AUTOSAR XML (schema 4-2-2)
package /MICROSAR/NvM_swc/DataTypes
  impl type NvM_RequestResultType: compu {0=NVM_REQ_OK, 1=NVM_REQ_NOT_OK, 2=NVM_REQ_PENDING, 3=NVM_REQ_INTEGRITY_FAILED, 4=NVM_REQ_BLOCK_SKIPPED, 5=NVM_REQ_NV_INVALIDATED, 6=NVM_REQ_CANCELED, 7=NVM_REQ_REDUNDANCY_FAILED, 8=NVM_REQ_RESTORED_FROM_ROM}, implementation-data-type=uint8
  impl type NvM_BlockIdType: range raw 1..32767, implementation-data-type=uint16
package /MICROSAR/NvM_swc/Interfaces
  client server interface NvMAdministration: is-service=true, service-kind=NON-VOLATILE-RAM-MANAGER
    operation SetBlockProtection: possible-error=NvMAdministration/E_NOT_OK
      arg ProtectionEnabled: type=boolean, direction=IN
    error E_NOT_OK: error-code=1
  client server interface NvMService_AC3_SRBS: is-service=true, service-kind=NON-VOLATILE-RAM-MANAGER
    6 x operation, all with possible-error=NvMService_AC3_SRBS/E_NOT_OK:
      GetErrorStatus
        arg ErrorStatus: type=NvM_RequestResultType, direction=OUT
      SetRamBlockStatus
        arg RamBlockStatus: type=boolean, direction=IN
      ReadBlock
        arg DstPtr: type=dtRef_VOID, direction=IN
      WriteBlock
        arg SrcPtr: type=dtRef_const_VOID, direction=IN
      InvalidateNvBlock
      EraseBlock
    error E_NOT_OK: error-code=1
  client server interface NvMService_AC3_SRBS_Defs: is-service=true, service-kind=NON-VOLATILE-RAM-MANAGER
    7 x operation, all with possible-error=NvMService_AC3_SRBS_Defs/E_NOT_OK:
      GetErrorStatus
        arg ErrorStatus: type=NvM_RequestResultType, direction=OUT
      SetRamBlockStatus
        arg RamBlockStatus: type=boolean, direction=IN
      ReadBlock
        arg DstPtr: type=dtRef_VOID, direction=IN
      WriteBlock
        arg SrcPtr: type=dtRef_const_VOID, direction=IN
      RestoreBlockDefaults
        arg DstPtr: type=dtRef_VOID, direction=IN
      InvalidateNvBlock
      EraseBlock
    error E_NOT_OK: error-code=1
package /MICROSAR/NvM_swc/ComponentTypes
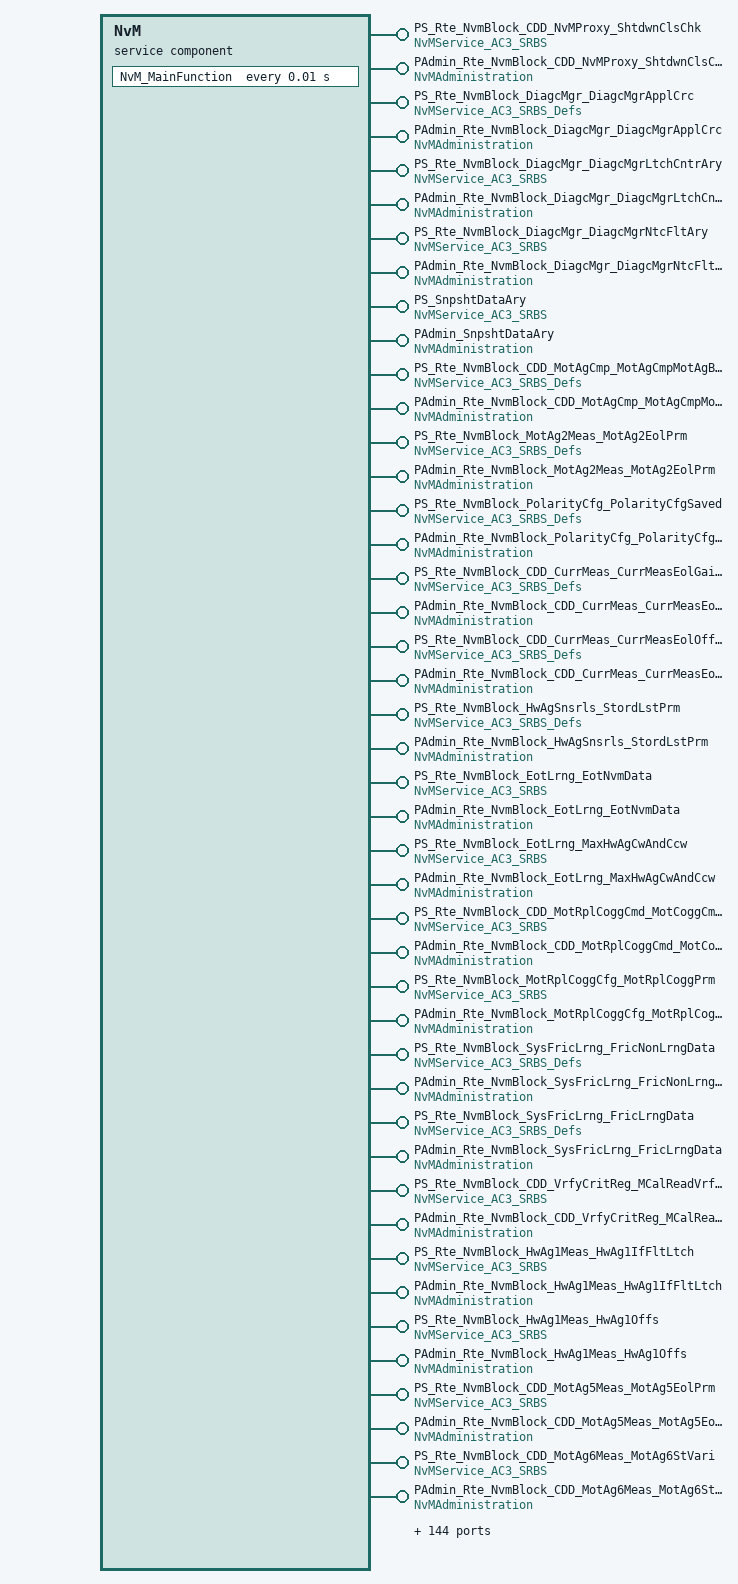
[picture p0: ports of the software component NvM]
  service sw component type NvM: category=SERVICE_COMPONENT
    188 x provide port:
      PS_Rte_NvmBlock_CDD_NvMProxy_ShtdwnClsChk: provided-interface=NvMService_AC3_SRBS
      PAdmin_Rte_NvmBlock_CDD_NvMProxy_ShtdwnClsChk: provided-interface=NvMAdministration
      PS_Rte_NvmBlock_DiagcMgr_DiagcMgrApplCrc: provided-interface=NvMService_AC3_SRBS_Defs
      PAdmin_Rte_NvmBlock_DiagcMgr_DiagcMgrApplCrc: provided-interface=NvMAdministration
      PS_Rte_NvmBlock_DiagcMgr_DiagcMgrLtchCntrAry: provided-interface=NvMService_AC3_SRBS
      PAdmin_Rte_NvmBlock_DiagcMgr_DiagcMgrLtchCntrAry: provided-interface=NvMAdministration
      PS_Rte_NvmBlock_DiagcMgr_DiagcMgrNtcFltAry: provided-interface=NvMService_AC3_SRBS
      PAdmin_Rte_NvmBlock_DiagcMgr_DiagcMgrNtcFltAry: provided-interface=NvMAdministration
      PS_SnpshtDataAry: provided-interface=NvMService_AC3_SRBS
      PAdmin_SnpshtDataAry: provided-interface=NvMAdministration
      PS_Rte_NvmBlock_CDD_MotAgCmp_MotAgCmpMotAgBackEmf: provided-interface=NvMService_AC3_SRBS_Defs
      PAdmin_Rte_NvmBlock_CDD_MotAgCmp_MotAgCmpMotAgBackEmf: provided-interface=NvMAdministration
      PS_Rte_NvmBlock_MotAg2Meas_MotAg2EolPrm: provided-interface=NvMService_AC3_SRBS_Defs
      PAdmin_Rte_NvmBlock_MotAg2Meas_MotAg2EolPrm: provided-interface=NvMAdministration
      PS_Rte_NvmBlock_PolarityCfg_PolarityCfgSaved: provided-interface=NvMService_AC3_SRBS_Defs
      PAdmin_Rte_NvmBlock_PolarityCfg_PolarityCfgSaved: provided-interface=NvMAdministration
      PS_Rte_NvmBlock_CDD_CurrMeas_CurrMeasEolGainCalSetABC: provided-interface=NvMService_AC3_SRBS_Defs
      PAdmin_Rte_NvmBlock_CDD_CurrMeas_CurrMeasEolGainCalSetABC: provided-interface=NvMAdministration
      PS_Rte_NvmBlock_CDD_CurrMeas_CurrMeasEolOffsCalSetABC: provided-interface=NvMService_AC3_SRBS_Defs
      PAdmin_Rte_NvmBlock_CDD_CurrMeas_CurrMeasEolOffsCalSetABC: provided-interface=NvMAdministration
      PS_Rte_NvmBlock_HwAgSnsrls_StordLstPrm: provided-interface=NvMService_AC3_SRBS_Defs
      PAdmin_Rte_NvmBlock_HwAgSnsrls_StordLstPrm: provided-interface=NvMAdministration
      PS_Rte_NvmBlock_EotLrng_EotNvmData: provided-interface=NvMService_AC3_SRBS
      PAdmin_Rte_NvmBlock_EotLrng_EotNvmData: provided-interface=NvMAdministration
      PS_Rte_NvmBlock_EotLrng_MaxHwAgCwAndCcw: provided-interface=NvMService_AC3_SRBS
      PAdmin_Rte_NvmBlock_EotLrng_MaxHwAgCwAndCcw: provided-interface=NvMAdministration
      PS_Rte_NvmBlock_CDD_MotRplCoggCmd_MotCoggCmdY: provided-interface=NvMService_AC3_SRBS
      PAdmin_Rte_NvmBlock_CDD_MotRplCoggCmd_MotCoggCmdY: provided-interface=NvMAdministration
      PS_Rte_NvmBlock_MotRplCoggCfg_MotRplCoggPrm: provided-interface=NvMService_AC3_SRBS
      PAdmin_Rte_NvmBlock_MotRplCoggCfg_MotRplCoggPrm: provided-interface=NvMAdministration
      PS_Rte_NvmBlock_SysFricLrng_FricNonLrngData: provided-interface=NvMService_AC3_SRBS_Defs
      PAdmin_Rte_NvmBlock_SysFricLrng_FricNonLrngData: provided-interface=NvMAdministration
      PS_Rte_NvmBlock_SysFricLrng_FricLrngData: provided-interface=NvMService_AC3_SRBS_Defs
      PAdmin_Rte_NvmBlock_SysFricLrng_FricLrngData: provided-interface=NvMAdministration
      PS_Rte_NvmBlock_CDD_VrfyCritReg_MCalReadVrfyCritRegFltNvmInfo: provided-interface=NvMService_AC3_SRBS
      PAdmin_Rte_NvmBlock_CDD_VrfyCritReg_MCalReadVrfyCritRegFltNvmInfo: provided-interface=NvMAdministration
      PS_Rte_NvmBlock_HwAg1Meas_HwAg1IfFltLtch: provided-interface=NvMService_AC3_SRBS
      PAdmin_Rte_NvmBlock_HwAg1Meas_HwAg1IfFltLtch: provided-interface=NvMAdministration
      PS_Rte_NvmBlock_HwAg1Meas_HwAg1Offs: provided-interface=NvMService_AC3_SRBS
      PAdmin_Rte_NvmBlock_HwAg1Meas_HwAg1Offs: provided-interface=NvMAdministration
      PS_Rte_NvmBlock_CDD_MotAg5Meas_MotAg5EolPrm: provided-interface=NvMService_AC3_SRBS
      PAdmin_Rte_NvmBlock_CDD_MotAg5Meas_MotAg5EolPrm: provided-interface=NvMAdministration
      PS_Rte_NvmBlock_CDD_MotAg6Meas_MotAg6StVari: provided-interface=NvMService_AC3_SRBS
      PAdmin_Rte_NvmBlock_CDD_MotAg6Meas_MotAg6StVari: provided-interface=NvMAdministration
      PS_Rte_NvmBlock_CDD_MotAg6Meas_MotAg6EolPrm: provided-interface=NvMService_AC3_SRBS
      PAdmin_Rte_NvmBlock_CDD_MotAg6Meas_MotAg6EolPrm: provided-interface=NvMAdministration
      PS_Rte_NvmBlock_CDD_MotAg5Meas_MotAg5StVari: provided-interface=NvMService_AC3_SRBS
      PAdmin_Rte_NvmBlock_CDD_MotAg5Meas_MotAg5StVari: provided-interface=NvMAdministration
      PS_Rte_NvmBlock_MotCtrlPrmEstimn_MotPrmNom: provided-interface=NvMService_AC3_SRBS
      PAdmin_Rte_NvmBlock_MotCtrlPrmEstimn_MotPrmNom: provided-interface=NvMAdministration
      PS_Deprecated_Rte_NvmBlock_HwTqCorrln_HwTqChACmnModCmpLpFilSt: provided-interface=NvMService_AC3_SRBS
      PAdmin_Deprecated_Rte_NvmBlock_HwTqCorrln_HwTqChACmnModCmpLpFilSt: provided-interface=NvMAdministration
      PS_Rte_NvmBlock_MotTqCmdSca_MotTqScaFac: provided-interface=NvMService_AC3_SRBS
      PAdmin_Rte_NvmBlock_MotTqCmdSca_MotTqScaFac: provided-interface=NvMAdministration
      PS_Rte_NvmBlock_DutyCycThermProtn_FilStVal: provided-interface=NvMService_AC3_SRBS
      PAdmin_Rte_NvmBlock_DutyCycThermProtn_FilStVal: provided-interface=NvMAdministration
      PS_Rte_NvmBlock_CmnMfgSrv_MfgTmpBuf1: provided-interface=NvMService_AC3_SRBS
      PAdmin_Rte_NvmBlock_CmnMfgSrv_MfgTmpBuf1: provided-interface=NvMAdministration
      PS_Rte_NvmBlock_CmnMfgSrv_DiRestore: provided-interface=NvMService_AC3_SRBS
      PAdmin_Rte_NvmBlock_CmnMfgSrv_DiRestore: provided-interface=NvMAdministration
      PS_Rte_NvmBlock_CmnMfgSrv_NxtrMfgEnaCntr: provided-interface=NvMService_AC3_SRBS_Defs
      PAdmin_Rte_NvmBlock_CmnMfgSrv_NxtrMfgEnaCntr: provided-interface=NvMAdministration
      PS_Rte_NvmBlock_CmnMfgSrv_MfgTmpBuf0: provided-interface=NvMService_AC3_SRBS
      PAdmin_Rte_NvmBlock_CmnMfgSrv_MfgTmpBuf0: provided-interface=NvMAdministration
      PS_Rte_NvmBlock_CmnMfgSrv_MfgTmpBuf3: provided-interface=NvMService_AC3_SRBS
      PAdmin_Rte_NvmBlock_CmnMfgSrv_MfgTmpBuf3: provided-interface=NvMAdministration
      PS_Rte_NvmBlock_CmnMfgSrv_EpsSysSerlNr: provided-interface=NvMService_AC3_SRBS
      PAdmin_Rte_NvmBlock_CmnMfgSrv_EpsSysSerlNr: provided-interface=NvMAdministration
      PS_Rte_NvmBlock_CmnMfgSrv_MfgTmpBuf2: provided-interface=NvMService_AC3_SRBS
      PAdmin_Rte_NvmBlock_CmnMfgSrv_MfgTmpBuf2: provided-interface=NvMAdministration
      PS_Rte_NvmBlock_CmnMfgSrv_CcaHwPartNr: provided-interface=NvMService_AC3_SRBS
      PAdmin_Rte_NvmBlock_CmnMfgSrv_CcaHwPartNr: provided-interface=NvMAdministration
      PS_Rte_NvmBlock_CmnMfgSrv_MfgTmpBuf4: provided-interface=NvMService_AC3_SRBS
      PAdmin_Rte_NvmBlock_CmnMfgSrv_MfgTmpBuf4: provided-interface=NvMAdministration
      PS_Rte_NvmBlock_CmnMfgSrv_SeedKey: provided-interface=NvMService_AC3_SRBS_Defs
      PAdmin_Rte_NvmBlock_CmnMfgSrv_SeedKey: provided-interface=NvMAdministration
      PS_Rte_NvmBlock_CmnMfgSrv_IgnCntr: provided-interface=NvMService_AC3_SRBS_Defs
      PAdmin_Rte_NvmBlock_CmnMfgSrv_IgnCntr: provided-interface=NvMAdministration
      PS_Rte_NvmBlock_CmnMfgSrv_CcaSerlNr: provided-interface=NvMService_AC3_SRBS
      PAdmin_Rte_NvmBlock_CmnMfgSrv_CcaSerlNr: provided-interface=NvMAdministration
      PS_Rte_NvmBlock_CDD_HwTq1Meas_HwTq1Offs: provided-interface=NvMService_AC3_SRBS_Defs
      PAdmin_Rte_NvmBlock_CDD_HwTq1Meas_HwTq1Offs: provided-interface=NvMAdministration
      PS_Rte_NvmBlock_CDD_HwTq8Meas_HwTq8Offs: provided-interface=NvMService_AC3_SRBS_Defs
      PAdmin_Rte_NvmBlock_CDD_HwTq8Meas_HwTq8Offs: provided-interface=NvMAdministration
      PS_Rte_NvmBlock_TEstimn_TFilStVal: provided-interface=NvMService_AC3_SRBS
      PAdmin_Rte_NvmBlock_TEstimn_TFilStVal: provided-interface=NvMAdministration
      PS_Rte_NvmBlock_HwTq9Meas_HwTq9Offs: provided-interface=NvMService_AC3_SRBS
      PAdmin_Rte_NvmBlock_HwTq9Meas_HwTq9Offs: provided-interface=NvMAdministration
      PS_Rte_NvmBlock_HwTq10Meas_HwTq10Offs: provided-interface=NvMService_AC3_SRBS
      PAdmin_Rte_NvmBlock_HwTq10Meas_HwTq10Offs: provided-interface=NvMAdministration
      PS_Rte_NvmBlock_CustDiag_DidDE04: provided-interface=NvMService_AC3_SRBS_Defs
      PAdmin_Rte_NvmBlock_CustDiag_DidDE04: provided-interface=NvMAdministration
      PS_Rte_NvmBlock_CustDiag_Did3003: provided-interface=NvMService_AC3_SRBS_Defs
      PAdmin_Rte_NvmBlock_CustDiag_Did3003: provided-interface=NvMAdministration
      PS_Rte_NvmBlock_CustDiag_DidEE01: provided-interface=NvMService_AC3_SRBS_Defs
      PAdmin_Rte_NvmBlock_CustDiag_DidEE01: provided-interface=NvMAdministration
      PS_Rte_NvmBlock_CustDiag_DidF111: provided-interface=NvMService_AC3_SRBS_Defs
      PAdmin_Rte_NvmBlock_CustDiag_DidF111: provided-interface=NvMAdministration
      PS_Rte_NvmBlock_CustDiag_DidF113: provided-interface=NvMService_AC3_SRBS_Defs
      PAdmin_Rte_NvmBlock_CustDiag_DidF113: provided-interface=NvMAdministration
      PS_Rte_NvmBlock_CustDiag_DidEE02: provided-interface=NvMService_AC3_SRBS_Defs
      PAdmin_Rte_NvmBlock_CustDiag_DidEE02: provided-interface=NvMAdministration
      PS_Rte_NvmBlock_CustDiag_DidDE02: provided-interface=NvMService_AC3_SRBS_Defs
      PAdmin_Rte_NvmBlock_CustDiag_DidDE02: provided-interface=NvMAdministration
      PS_Rte_NvmBlock_CustDiag_DidDE03: provided-interface=NvMService_AC3_SRBS_Defs
      PAdmin_Rte_NvmBlock_CustDiag_DidDE03: provided-interface=NvMAdministration
      PS_Rte_NvmBlock_CustDiag_DidDE00: provided-interface=NvMService_AC3_SRBS_Defs
      PAdmin_Rte_NvmBlock_CustDiag_DidDE00: provided-interface=NvMAdministration
      PS_Rte_NvmBlock_CustDiag_DidDE01: provided-interface=NvMService_AC3_SRBS_Defs
      PAdmin_Rte_NvmBlock_CustDiag_DidDE01: provided-interface=NvMAdministration
      PS_Rte_NvmBlock_FordVehSpdArbn_FordVehTireCircum: provided-interface=NvMService_AC3_SRBS
      PAdmin_Rte_NvmBlock_FordVehSpdArbn_FordVehTireCircum: provided-interface=NvMAdministration
      PS_Rte_NvmBlock_FordHwAgArbn_PrevIgnCycVal: provided-interface=NvMService_AC3_SRBS_Defs
      PAdmin_Rte_NvmBlock_FordHwAgArbn_PrevIgnCycVal: provided-interface=NvMAdministration
      PS_Rte_NvmBlock_FordHwAgArbn_NonAbsOffsVldFlg: provided-interface=NvMService_AC3_SRBS
      PAdmin_Rte_NvmBlock_FordHwAgArbn_NonAbsOffsVldFlg: provided-interface=NvMAdministration
      PS_Rte_NvmBlock_FordHwAgArbn_NonAbsOffs: provided-interface=NvMService_AC3_SRBS
      PAdmin_Rte_NvmBlock_FordHwAgArbn_NonAbsOffs: provided-interface=NvMAdministration
      PS_Rte_NvmBlock_CustDiag_DidF15F: provided-interface=NvMService_AC3_SRBS_Defs
      PAdmin_Rte_NvmBlock_CustDiag_DidF15F: provided-interface=NvMAdministration
      PS_Rte_NvmBlock_CustDiag_DidEE88: provided-interface=NvMService_AC3_SRBS_Defs
      PAdmin_Rte_NvmBlock_CustDiag_DidEE88: provided-interface=NvMAdministration
      PS_Rte_NvmBlock_CustDiag_DidF110: provided-interface=NvMService_AC3_SRBS_Defs
      PAdmin_Rte_NvmBlock_CustDiag_DidF110: provided-interface=NvMAdministration
      PS_Rte_NvmBlock_CustDiag_DidEED0: provided-interface=NvMService_AC3_SRBS_Defs
      PAdmin_Rte_NvmBlock_CustDiag_DidEED0: provided-interface=NvMAdministration
      PS_Rte_NvmBlock_CustDiag_DidEE83: provided-interface=NvMService_AC3_SRBS_Defs
      PAdmin_Rte_NvmBlock_CustDiag_DidEE83: provided-interface=NvMAdministration
      PS_Rte_NvmBlock_CustDiag_Did301A: provided-interface=NvMService_AC3_SRBS_Defs
      PAdmin_Rte_NvmBlock_CustDiag_Did301A: provided-interface=NvMAdministration
      PS_Rte_NvmBlock_CustDiag_DidF162: provided-interface=NvMService_AC3_SRBS_Defs
      PAdmin_Rte_NvmBlock_CustDiag_DidF162: provided-interface=NvMAdministration
      PS_Rte_NvmBlock_CustDiag_DidEE40: provided-interface=NvMService_AC3_SRBS_Defs
      PAdmin_Rte_NvmBlock_CustDiag_DidEE40: provided-interface=NvMAdministration
      PS_Rte_NvmBlock_CustDiag_DidEE81: provided-interface=NvMService_AC3_SRBS_Defs
      PAdmin_Rte_NvmBlock_CustDiag_DidEE81: provided-interface=NvMAdministration
      PS_Rte_NvmBlock_CustDiag_DidEE82: provided-interface=NvMService_AC3_SRBS_Defs
      PAdmin_Rte_NvmBlock_CustDiag_DidEE82: provided-interface=NvMAdministration
      PS_Rte_NvmBlock_CustDiag_DidEE41: provided-interface=NvMService_AC3_SRBS_Defs
      PAdmin_Rte_NvmBlock_CustDiag_DidEE41: provided-interface=NvMAdministration
      PS_Rte_NvmBlock_CustDiag_DidEE84: provided-interface=NvMService_AC3_SRBS_Defs
      PAdmin_Rte_NvmBlock_CustDiag_DidEE84: provided-interface=NvMAdministration
      PS_Rte_NvmBlock_CustDiag_DidF18A: provided-interface=NvMService_AC3_SRBS_Defs
      PAdmin_Rte_NvmBlock_CustDiag_DidF18A: provided-interface=NvMAdministration
      PS_Rte_NvmBlock_CustDiag_DidEE00: provided-interface=NvMService_AC3_SRBS_Defs
      PAdmin_Rte_NvmBlock_CustDiag_DidEE00: provided-interface=NvMAdministration
      PS_Rte_NvmBlock_CustDiag_DidF166: provided-interface=NvMService_AC3_SRBS_Defs
      PAdmin_Rte_NvmBlock_CustDiag_DidF166: provided-interface=NvMAdministration
      PS_Rte_NvmBlock_CustDiag_Did205A: provided-interface=NvMService_AC3_SRBS_Defs
      PAdmin_Rte_NvmBlock_CustDiag_Did205A: provided-interface=NvMAdministration
      PS_Rte_NvmBlock_CustDiag_DidEE87: provided-interface=NvMService_AC3_SRBS_Defs
      PAdmin_Rte_NvmBlock_CustDiag_DidEE87: provided-interface=NvMAdministration
      PS_Rte_NvmBlock_CustDiag_DidDE05: provided-interface=NvMService_AC3_SRBS_Defs
      PAdmin_Rte_NvmBlock_CustDiag_DidDE05: provided-interface=NvMAdministration
      PS_Rte_NvmBlock_CustDiag_DidEE86: provided-interface=NvMService_AC3_SRBS_Defs
      PAdmin_Rte_NvmBlock_CustDiag_DidEE86: provided-interface=NvMAdministration
      PS_Rte_NvmBlock_CustDiag_DidF163: provided-interface=NvMService_AC3_SRBS_Defs
      PAdmin_Rte_NvmBlock_CustDiag_DidF163: provided-interface=NvMAdministration
      PS_Rte_NvmBlock_CustDiag_DidF18C: provided-interface=NvMService_AC3_SRBS_Defs
      PAdmin_Rte_NvmBlock_CustDiag_DidF18C: provided-interface=NvMAdministration
      PS_Rte_NvmBlock_CustDiag_Did205B: provided-interface=NvMService_AC3_SRBS_Defs
      PAdmin_Rte_NvmBlock_CustDiag_Did205B: provided-interface=NvMAdministration
      PS_Rte_NvmBlock_CustDiag_DidEE85: provided-interface=NvMService_AC3_SRBS_Defs
      PAdmin_Rte_NvmBlock_CustDiag_DidEE85: provided-interface=NvMAdministration
      PS_Rte_NvmBlock_CustDiag_DidEE21: provided-interface=NvMService_AC3_SRBS_Defs
      PAdmin_Rte_NvmBlock_CustDiag_DidEE21: provided-interface=NvMAdministration
      PS_Rte_NvmBlock_CustDiag_DidEE22: provided-interface=NvMService_AC3_SRBS_Defs
      PAdmin_Rte_NvmBlock_CustDiag_DidEE22: provided-interface=NvMAdministration
      PS_Rte_NvmBlock_CustDiag_DidF190: provided-interface=NvMService_AC3_SRBS_Defs
      PAdmin_Rte_NvmBlock_CustDiag_DidF190: provided-interface=NvMAdministration
      PS_Rte_NvmBlock_CustDiag_Did630F: provided-interface=NvMService_AC3_SRBS_Defs
      PAdmin_Rte_NvmBlock_CustDiag_Did630F: provided-interface=NvMAdministration
      PS_Rte_NvmBlock_CustDiag_Did630FChk: provided-interface=NvMService_AC3_SRBS_Defs
      PAdmin_Rte_NvmBlock_CustDiag_Did630FChk: provided-interface=NvMAdministration
      PS_Rte_NvmBlock_CustDiag_DidEE23: provided-interface=NvMService_AC3_SRBS_Defs
      PAdmin_Rte_NvmBlock_CustDiag_DidEE23: provided-interface=NvMAdministration
      PS_Rte_NvmBlock_StackMeas_StackMeasRes: provided-interface=NvMService_AC3_SRBS_Defs
      PAdmin_Rte_NvmBlock_StackMeas_StackMeasRes: provided-interface=NvMAdministration
      PS_Rte_NvmBlock_StackMeas_StackMeasApplCrc: provided-interface=NvMService_AC3_SRBS
      PAdmin_Rte_NvmBlock_StackMeas_StackMeasApplCrc: provided-interface=NvMAdministration
      PS_Rte_NvmBlock_CDD_FordBlaBoxIfCmp1_LaneAssi: provided-interface=NvMService_AC3_SRBS_Defs
      PAdmin_Rte_NvmBlock_CDD_FordBlaBoxIfCmp1_LaneAssi: provided-interface=NvMAdministration
      PS_Rte_NvmBlock_CDD_FordBlaBoxIfCmp1_PullDriftCmp: provided-interface=NvMService_AC3_SRBS_Defs
      PAdmin_Rte_NvmBlock_CDD_FordBlaBoxIfCmp1_PullDriftCmp: provided-interface=NvMAdministration
      PS_Rte_NvmBlock_CDD_FordBlaBoxIfCmp1_TrlrBackupAssi: provided-interface=NvMService_AC3_SRBS_Defs
      PAdmin_Rte_NvmBlock_CDD_FordBlaBoxIfCmp1_TrlrBackupAssi: provided-interface=NvMAdministration
      PS_Rte_NvmBlock_CDD_FordBlaBoxIfCmp1_ActvNiblCtrl: provided-interface=NvMService_AC3_SRBS_Defs
      PAdmin_Rte_NvmBlock_CDD_FordBlaBoxIfCmp1_ActvNiblCtrl: provided-interface=NvMAdministration
    behavior NvMInternalBehavior: handle-termination-and-restart=NO-SUPPORT
      timing event Timer_NvM_MainFunction: start-on-event=NvM_MainFunction, period=0.01
      717 x operation invoked event:
        OpEventGetErrorStatus_GetErrorStatus_PS_Rte_NvmBlock_CDD_NvMProxy_ShtdwnClsChk: start-on-event=GetErrorStatus, operation=PS_Rte_NvmBlock_CDD_NvMProxy_ShtdwnClsChk.GetErrorStatus
        OpEventGetErrorStatus_GetErrorStatus_PS_Rte_NvmBlock_DiagcMgr_DiagcMgrApplCrc: start-on-event=GetErrorStatus, operation=PS_Rte_NvmBlock_DiagcMgr_DiagcMgrApplCrc.GetErrorStatus
        OpEventGetErrorStatus_GetErrorStatus_PS_Rte_NvmBlock_DiagcMgr_DiagcMgrLtchCntrAry: start-on-event=GetErrorStatus, operation=PS_Rte_NvmBlock_DiagcMgr_DiagcMgrLtchCntrAry.GetErrorStatus
        OpEventGetErrorStatus_GetErrorStatus_PS_Rte_NvmBlock_DiagcMgr_DiagcMgrNtcFltAry: start-on-event=GetErrorStatus, operation=PS_Rte_NvmBlock_DiagcMgr_DiagcMgrNtcFltAry.GetErrorStatus
        OpEventGetErrorStatus_GetErrorStatus_PS_SnpshtDataAry: start-on-event=GetErrorStatus, operation=PS_SnpshtDataAry.GetErrorStatus
        OpEventGetErrorStatus_GetErrorStatus_PS_Rte_NvmBlock_CDD_MotAgCmp_MotAgCmpMotAgBackEmf: start-on-event=GetErrorStatus, operation=PS_Rte_NvmBlock_CDD_MotAgCmp_MotAgCmpMotAgBackEmf.GetErrorStatus
        OpEventGetErrorStatus_GetErrorStatus_PS_Rte_NvmBlock_MotAg2Meas_MotAg2EolPrm: start-on-event=GetErrorStatus, operation=PS_Rte_NvmBlock_MotAg2Meas_MotAg2EolPrm.GetErrorStatus
        OpEventGetErrorStatus_GetErrorStatus_PS_Rte_NvmBlock_PolarityCfg_PolarityCfgSaved: start-on-event=GetErrorStatus, operation=PS_Rte_NvmBlock_PolarityCfg_PolarityCfgSaved.GetErrorStatus
        OpEventGetErrorStatus_GetErrorStatus_PS_Rte_NvmBlock_CDD_CurrMeas_CurrMeasEolGainCalSetABC: start-on-event=GetErrorStatus, operation=PS_Rte_NvmBlock_CDD_CurrMeas_CurrMeasEolGainCalSetABC.GetErrorStatus
        OpEventGetErrorStatus_GetErrorStatus_PS_Rte_NvmBlock_CDD_CurrMeas_CurrMeasEolOffsCalSetABC: start-on-event=GetErrorStatus, operation=PS_Rte_NvmBlock_CDD_CurrMeas_CurrMeasEolOffsCalSetABC.GetErrorStatus
        OpEventGetErrorStatus_GetErrorStatus_PS_Rte_NvmBlock_HwAgSnsrls_StordLstPrm: start-on-event=GetErrorStatus, operation=PS_Rte_NvmBlock_HwAgSnsrls_StordLstPrm.GetErrorStatus
        OpEventGetErrorStatus_GetErrorStatus_PS_Rte_NvmBlock_EotLrng_EotNvmData: start-on-event=GetErrorStatus, operation=PS_Rte_NvmBlock_EotLrng_EotNvmData.GetErrorStatus
        OpEventGetErrorStatus_GetErrorStatus_PS_Rte_NvmBlock_EotLrng_MaxHwAgCwAndCcw: start-on-event=GetErrorStatus, operation=PS_Rte_NvmBlock_EotLrng_MaxHwAgCwAndCcw.GetErrorStatus
        OpEventGetErrorStatus_GetErrorStatus_PS_Rte_NvmBlock_CDD_MotRplCoggCmd_MotCoggCmdY: start-on-event=GetErrorStatus, operation=PS_Rte_NvmBlock_CDD_MotRplCoggCmd_MotCoggCmdY.GetErrorStatus
        OpEventGetErrorStatus_GetErrorStatus_PS_Rte_NvmBlock_MotRplCoggCfg_MotRplCoggPrm: start-on-event=GetErrorStatus, operation=PS_Rte_NvmBlock_MotRplCoggCfg_MotRplCoggPrm.GetErrorStatus
        OpEventGetErrorStatus_GetErrorStatus_PS_Rte_NvmBlock_SysFricLrng_FricNonLrngData: start-on-event=GetErrorStatus, operation=PS_Rte_NvmBlock_SysFricLrng_FricNonLrngData.GetErrorStatus
        OpEventGetErrorStatus_GetErrorStatus_PS_Rte_NvmBlock_SysFricLrng_FricLrngData: start-on-event=GetErrorStatus, operation=PS_Rte_NvmBlock_SysFricLrng_FricLrngData.GetErrorStatus
        OpEventGetErrorStatus_GetErrorStatus_PS_Rte_NvmBlock_CDD_VrfyCritReg_MCalReadVrfyCritRegFltNvmInfo: start-on-event=GetErrorStatus, operation=PS_Rte_NvmBlock_CDD_VrfyCritReg_MCalReadVrfyCritRegFltNvmInfo.GetErrorStatus
        OpEventGetErrorStatus_GetErrorStatus_PS_Rte_NvmBlock_HwAg1Meas_HwAg1IfFltLtch: start-on-event=GetErrorStatus, operation=PS_Rte_NvmBlock_HwAg1Meas_HwAg1IfFltLtch.GetErrorStatus
        OpEventGetErrorStatus_GetErrorStatus_PS_Rte_NvmBlock_HwAg1Meas_HwAg1Offs: start-on-event=GetErrorStatus, operation=PS_Rte_NvmBlock_HwAg1Meas_HwAg1Offs.GetErrorStatus
        OpEventGetErrorStatus_GetErrorStatus_PS_Rte_NvmBlock_CDD_MotAg5Meas_MotAg5EolPrm: start-on-event=GetErrorStatus, operation=PS_Rte_NvmBlock_CDD_MotAg5Meas_MotAg5EolPrm.GetErrorStatus
        OpEventGetErrorStatus_GetErrorStatus_PS_Rte_NvmBlock_CDD_MotAg6Meas_MotAg6StVari: start-on-event=GetErrorStatus, operation=PS_Rte_NvmBlock_CDD_MotAg6Meas_MotAg6StVari.GetErrorStatus
        OpEventGetErrorStatus_GetErrorStatus_PS_Rte_NvmBlock_CDD_MotAg6Meas_MotAg6EolPrm: start-on-event=GetErrorStatus, operation=PS_Rte_NvmBlock_CDD_MotAg6Meas_MotAg6EolPrm.GetErrorStatus
        OpEventGetErrorStatus_GetErrorStatus_PS_Rte_NvmBlock_CDD_MotAg5Meas_MotAg5StVari: start-on-event=GetErrorStatus, operation=PS_Rte_NvmBlock_CDD_MotAg5Meas_MotAg5StVari.GetErrorStatus
        OpEventGetErrorStatus_GetErrorStatus_PS_Rte_NvmBlock_MotCtrlPrmEstimn_MotPrmNom: start-on-event=GetErrorStatus, operation=PS_Rte_NvmBlock_MotCtrlPrmEstimn_MotPrmNom.GetErrorStatus
        OpEventGetErrorStatus_GetErrorStatus_PS_Deprecated_Rte_NvmBlock_HwTqCorrln_HwTqChACmnModCmpLpFilSt: start-on-event=GetErrorStatus, operation=PS_Deprecated_Rte_NvmBlock_HwTqCorrln_HwTqChACmnModCmpLpFilSt.GetErrorStatus
        OpEventGetErrorStatus_GetErrorStatus_PS_Rte_NvmBlock_MotTqCmdSca_MotTqScaFac: start-on-event=GetErrorStatus, operation=PS_Rte_NvmBlock_MotTqCmdSca_MotTqScaFac.GetErrorStatus
        OpEventGetErrorStatus_GetErrorStatus_PS_Rte_NvmBlock_DutyCycThermProtn_FilStVal: start-on-event=GetErrorStatus, operation=PS_Rte_NvmBlock_DutyCycThermProtn_FilStVal.GetErrorStatus
        OpEventGetErrorStatus_GetErrorStatus_PS_Rte_NvmBlock_CmnMfgSrv_MfgTmpBuf1: start-on-event=GetErrorStatus, operation=PS_Rte_NvmBlock_CmnMfgSrv_MfgTmpBuf1.GetErrorStatus
        OpEventGetErrorStatus_GetErrorStatus_PS_Rte_NvmBlock_CmnMfgSrv_DiRestore: start-on-event=GetErrorStatus, operation=PS_Rte_NvmBlock_CmnMfgSrv_DiRestore.GetErrorStatus
        OpEventGetErrorStatus_GetErrorStatus_PS_Rte_NvmBlock_CmnMfgSrv_NxtrMfgEnaCntr: start-on-event=GetErrorStatus, operation=PS_Rte_NvmBlock_CmnMfgSrv_NxtrMfgEnaCntr.GetErrorStatus
        OpEventGetErrorStatus_GetErrorStatus_PS_Rte_NvmBlock_CmnMfgSrv_MfgTmpBuf0: start-on-event=GetErrorStatus, operation=PS_Rte_NvmBlock_CmnMfgSrv_MfgTmpBuf0.GetErrorStatus
        OpEventGetErrorStatus_GetErrorStatus_PS_Rte_NvmBlock_CmnMfgSrv_MfgTmpBuf3: start-on-event=GetErrorStatus, operation=PS_Rte_NvmBlock_CmnMfgSrv_MfgTmpBuf3.GetErrorStatus
        OpEventGetErrorStatus_GetErrorStatus_PS_Rte_NvmBlock_CmnMfgSrv_EpsSysSerlNr: start-on-event=GetErrorStatus, operation=PS_Rte_NvmBlock_CmnMfgSrv_EpsSysSerlNr.GetErrorStatus
        OpEventGetErrorStatus_GetErrorStatus_PS_Rte_NvmBlock_CmnMfgSrv_MfgTmpBuf2: start-on-event=GetErrorStatus, operation=PS_Rte_NvmBlock_CmnMfgSrv_MfgTmpBuf2.GetErrorStatus
        OpEventGetErrorStatus_GetErrorStatus_PS_Rte_NvmBlock_CmnMfgSrv_CcaHwPartNr: start-on-event=GetErrorStatus, operation=PS_Rte_NvmBlock_CmnMfgSrv_CcaHwPartNr.GetErrorStatus
        OpEventGetErrorStatus_GetErrorStatus_PS_Rte_NvmBlock_CmnMfgSrv_MfgTmpBuf4: start-on-event=GetErrorStatus, operation=PS_Rte_NvmBlock_CmnMfgSrv_MfgTmpBuf4.GetErrorStatus
        OpEventGetErrorStatus_GetErrorStatus_PS_Rte_NvmBlock_CmnMfgSrv_SeedKey: start-on-event=GetErrorStatus, operation=PS_Rte_NvmBlock_CmnMfgSrv_SeedKey.GetErrorStatus
        OpEventGetErrorStatus_GetErrorStatus_PS_Rte_NvmBlock_CmnMfgSrv_IgnCntr: start-on-event=GetErrorStatus, operation=PS_Rte_NvmBlock_CmnMfgSrv_IgnCntr.GetErrorStatus
        OpEventGetErrorStatus_GetErrorStatus_PS_Rte_NvmBlock_CmnMfgSrv_CcaSerlNr: start-on-event=GetErrorStatus, operation=PS_Rte_NvmBlock_CmnMfgSrv_CcaSerlNr.GetErrorStatus
        OpEventGetErrorStatus_GetErrorStatus_PS_Rte_NvmBlock_CDD_HwTq1Meas_HwTq1Offs: start-on-event=GetErrorStatus, operation=PS_Rte_NvmBlock_CDD_HwTq1Meas_HwTq1Offs.GetErrorStatus
        OpEventGetErrorStatus_GetErrorStatus_PS_Rte_NvmBlock_CDD_HwTq8Meas_HwTq8Offs: start-on-event=GetErrorStatus, operation=PS_Rte_NvmBlock_CDD_HwTq8Meas_HwTq8Offs.GetErrorStatus
        OpEventGetErrorStatus_GetErrorStatus_PS_Rte_NvmBlock_TEstimn_TFilStVal: start-on-event=GetErrorStatus, operation=PS_Rte_NvmBlock_TEstimn_TFilStVal.GetErrorStatus
        OpEventGetErrorStatus_GetErrorStatus_PS_Rte_NvmBlock_HwTq9Meas_HwTq9Offs: start-on-event=GetErrorStatus, operation=PS_Rte_NvmBlock_HwTq9Meas_HwTq9Offs.GetErrorStatus
        OpEventGetErrorStatus_GetErrorStatus_PS_Rte_NvmBlock_HwTq10Meas_HwTq10Offs: start-on-event=GetErrorStatus, operation=PS_Rte_NvmBlock_HwTq10Meas_HwTq10Offs.GetErrorStatus
        OpEventSetRamBlockStatus_SetRamBlockStatus_PS_Rte_NvmBlock_CDD_NvMProxy_ShtdwnClsChk: start-on-event=SetRamBlockStatus, operation=PS_Rte_NvmBlock_CDD_NvMProxy_ShtdwnClsChk.SetRamBlockStatus
        OpEventSetRamBlockStatus_SetRamBlockStatus_PS_Rte_NvmBlock_DiagcMgr_DiagcMgrApplCrc: start-on-event=SetRamBlockStatus, operation=PS_Rte_NvmBlock_DiagcMgr_DiagcMgrApplCrc.SetRamBlockStatus
        OpEventSetRamBlockStatus_SetRamBlockStatus_PS_Rte_NvmBlock_DiagcMgr_DiagcMgrLtchCntrAry: start-on-event=SetRamBlockStatus, operation=PS_Rte_NvmBlock_DiagcMgr_DiagcMgrLtchCntrAry.SetRamBlockStatus
        OpEventSetRamBlockStatus_SetRamBlockStatus_PS_Rte_NvmBlock_DiagcMgr_DiagcMgrNtcFltAry: start-on-event=SetRamBlockStatus, operation=PS_Rte_NvmBlock_DiagcMgr_DiagcMgrNtcFltAry.SetRamBlockStatus
        OpEventSetRamBlockStatus_SetRamBlockStatus_PS_SnpshtDataAry: start-on-event=SetRamBlockStatus, operation=PS_SnpshtDataAry.SetRamBlockStatus
        OpEventSetRamBlockStatus_SetRamBlockStatus_PS_Rte_NvmBlock_CDD_MotAgCmp_MotAgCmpMotAgBackEmf: start-on-event=SetRamBlockStatus, operation=PS_Rte_NvmBlock_CDD_MotAgCmp_MotAgCmpMotAgBackEmf.SetRamBlockStatus
        OpEventSetRamBlockStatus_SetRamBlockStatus_PS_Rte_NvmBlock_MotAg2Meas_MotAg2EolPrm: start-on-event=SetRamBlockStatus, operation=PS_Rte_NvmBlock_MotAg2Meas_MotAg2EolPrm.SetRamBlockStatus
        OpEventSetRamBlockStatus_SetRamBlockStatus_PS_Rte_NvmBlock_PolarityCfg_PolarityCfgSaved: start-on-event=SetRamBlockStatus, operation=PS_Rte_NvmBlock_PolarityCfg_PolarityCfgSaved.SetRamBlockStatus
        OpEventSetRamBlockStatus_SetRamBlockStatus_PS_Rte_NvmBlock_CDD_CurrMeas_CurrMeasEolGainCalSetABC: start-on-event=SetRamBlockStatus, operation=PS_Rte_NvmBlock_CDD_CurrMeas_CurrMeasEolGainCalSetABC.SetRamBlockStatus
        OpEventSetRamBlockStatus_SetRamBlockStatus_PS_Rte_NvmBlock_CDD_CurrMeas_CurrMeasEolOffsCalSetABC: start-on-event=SetRamBlockStatus, operation=PS_Rte_NvmBlock_CDD_CurrMeas_CurrMeasEolOffsCalSetABC.SetRamBlockStatus
        OpEventSetRamBlockStatus_SetRamBlockStatus_PS_Rte_NvmBlock_HwAgSnsrls_StordLstPrm: start-on-event=SetRamBlockStatus, operation=PS_Rte_NvmBlock_HwAgSnsrls_StordLstPrm.SetRamBlockStatus
        OpEventSetRamBlockStatus_SetRamBlockStatus_PS_Rte_NvmBlock_EotLrng_EotNvmData: start-on-event=SetRamBlockStatus, operation=PS_Rte_NvmBlock_EotLrng_EotNvmData.SetRamBlockStatus
        OpEventSetRamBlockStatus_SetRamBlockStatus_PS_Rte_NvmBlock_EotLrng_MaxHwAgCwAndCcw: start-on-event=SetRamBlockStatus, operation=PS_Rte_NvmBlock_EotLrng_MaxHwAgCwAndCcw.SetRamBlockStatus
        OpEventSetRamBlockStatus_SetRamBlockStatus_PS_Rte_NvmBlock_CDD_MotRplCoggCmd_MotCoggCmdY: start-on-event=SetRamBlockStatus, operation=PS_Rte_NvmBlock_CDD_MotRplCoggCmd_MotCoggCmdY.SetRamBlockStatus
        OpEventSetRamBlockStatus_SetRamBlockStatus_PS_Rte_NvmBlock_MotRplCoggCfg_MotRplCoggPrm: start-on-event=SetRamBlockStatus, operation=PS_Rte_NvmBlock_MotRplCoggCfg_MotRplCoggPrm.SetRamBlockStatus
        OpEventSetRamBlockStatus_SetRamBlockStatus_PS_Rte_NvmBlock_SysFricLrng_FricNonLrngData: start-on-event=SetRamBlockStatus, operation=PS_Rte_NvmBlock_SysFricLrng_FricNonLrngData.SetRamBlockStatus
        OpEventSetRamBlockStatus_SetRamBlockStatus_PS_Rte_NvmBlock_SysFricLrng_FricLrngData: start-on-event=SetRamBlockStatus, operation=PS_Rte_NvmBlock_SysFricLrng_FricLrngData.SetRamBlockStatus
        OpEventSetRamBlockStatus_SetRamBlockStatus_PS_Rte_NvmBlock_CDD_VrfyCritReg_MCalReadVrfyCritRegFltNvmInfo: start-on-event=SetRamBlockStatus, operation=PS_Rte_NvmBlock_CDD_VrfyCritReg_MCalReadVrfyCritRegFltNvmInfo.SetRamBlockStatus
        OpEventSetRamBlockStatus_SetRamBlockStatus_PS_Rte_NvmBlock_HwAg1Meas_HwAg1IfFltLtch: start-on-event=SetRamBlockStatus, operation=PS_Rte_NvmBlock_HwAg1Meas_HwAg1IfFltLtch.SetRamBlockStatus
        OpEventSetRamBlockStatus_SetRamBlockStatus_PS_Rte_NvmBlock_HwAg1Meas_HwAg1Offs: start-on-event=SetRamBlockStatus, operation=PS_Rte_NvmBlock_HwAg1Meas_HwAg1Offs.SetRamBlockStatus
        OpEventSetRamBlockStatus_SetRamBlockStatus_PS_Rte_NvmBlock_CDD_MotAg5Meas_MotAg5EolPrm: start-on-event=SetRamBlockStatus, operation=PS_Rte_NvmBlock_CDD_MotAg5Meas_MotAg5EolPrm.SetRamBlockStatus
        OpEventSetRamBlockStatus_SetRamBlockStatus_PS_Rte_NvmBlock_CDD_MotAg6Meas_MotAg6StVari: start-on-event=SetRamBlockStatus, operation=PS_Rte_NvmBlock_CDD_MotAg6Meas_MotAg6StVari.SetRamBlockStatus
        OpEventSetRamBlockStatus_SetRamBlockStatus_PS_Rte_NvmBlock_CDD_MotAg6Meas_MotAg6EolPrm: start-on-event=SetRamBlockStatus, operation=PS_Rte_NvmBlock_CDD_MotAg6Meas_MotAg6EolPrm.SetRamBlockStatus
        OpEventSetRamBlockStatus_SetRamBlockStatus_PS_Rte_NvmBlock_CDD_MotAg5Meas_MotAg5StVari: start-on-event=SetRamBlockStatus, operation=PS_Rte_NvmBlock_CDD_MotAg5Meas_MotAg5StVari.SetRamBlockStatus
        OpEventSetRamBlockStatus_SetRamBlockStatus_PS_Rte_NvmBlock_MotCtrlPrmEstimn_MotPrmNom: start-on-event=SetRamBlockStatus, operation=PS_Rte_NvmBlock_MotCtrlPrmEstimn_MotPrmNom.SetRamBlockStatus
        OpEventSetRamBlockStatus_SetRamBlockStatus_PS_Deprecated_Rte_NvmBlock_HwTqCorrln_HwTqChACmnModCmpLpFilSt: start-on-event=SetRamBlockStatus, operation=PS_Deprecated_Rte_NvmBlock_HwTqCorrln_HwTqChACmnModCmpLpFilSt.SetRamBlockStatus
        OpEventSetRamBlockStatus_SetRamBlockStatus_PS_Rte_NvmBlock_MotTqCmdSca_MotTqScaFac: start-on-event=SetRamBlockStatus, operation=PS_Rte_NvmBlock_MotTqCmdSca_MotTqScaFac.SetRamBlockStatus
        OpEventSetRamBlockStatus_SetRamBlockStatus_PS_Rte_NvmBlock_DutyCycThermProtn_FilStVal: start-on-event=SetRamBlockStatus, operation=PS_Rte_NvmBlock_DutyCycThermProtn_FilStVal.SetRamBlockStatus
        OpEventSetRamBlockStatus_SetRamBlockStatus_PS_Rte_NvmBlock_CmnMfgSrv_MfgTmpBuf1: start-on-event=SetRamBlockStatus, operation=PS_Rte_NvmBlock_CmnMfgSrv_MfgTmpBuf1.SetRamBlockStatus
        OpEventSetRamBlockStatus_SetRamBlockStatus_PS_Rte_NvmBlock_CmnMfgSrv_DiRestore: start-on-event=SetRamBlockStatus, operation=PS_Rte_NvmBlock_CmnMfgSrv_DiRestore.SetRamBlockStatus
        OpEventSetRamBlockStatus_SetRamBlockStatus_PS_Rte_NvmBlock_CmnMfgSrv_NxtrMfgEnaCntr: start-on-event=SetRamBlockStatus, operation=PS_Rte_NvmBlock_CmnMfgSrv_NxtrMfgEnaCntr.SetRamBlockStatus
        OpEventSetRamBlockStatus_SetRamBlockStatus_PS_Rte_NvmBlock_CmnMfgSrv_MfgTmpBuf0: start-on-event=SetRamBlockStatus, operation=PS_Rte_NvmBlock_CmnMfgSrv_MfgTmpBuf0.SetRamBlockStatus
        OpEventSetRamBlockStatus_SetRamBlockStatus_PS_Rte_NvmBlock_CmnMfgSrv_MfgTmpBuf3: start-on-event=SetRamBlockStatus, operation=PS_Rte_NvmBlock_CmnMfgSrv_MfgTmpBuf3.SetRamBlockStatus
        OpEventSetRamBlockStatus_SetRamBlockStatus_PS_Rte_NvmBlock_CmnMfgSrv_EpsSysSerlNr: start-on-event=SetRamBlockStatus, operation=PS_Rte_NvmBlock_CmnMfgSrv_EpsSysSerlNr.SetRamBlockStatus
        OpEventSetRamBlockStatus_SetRamBlockStatus_PS_Rte_NvmBlock_CmnMfgSrv_MfgTmpBuf2: start-on-event=SetRamBlockStatus, operation=PS_Rte_NvmBlock_CmnMfgSrv_MfgTmpBuf2.SetRamBlockStatus
        OpEventSetRamBlockStatus_SetRamBlockStatus_PS_Rte_NvmBlock_CmnMfgSrv_CcaHwPartNr: start-on-event=SetRamBlockStatus, operation=PS_Rte_NvmBlock_CmnMfgSrv_CcaHwPartNr.SetRamBlockStatus
        OpEventSetRamBlockStatus_SetRamBlockStatus_PS_Rte_NvmBlock_CmnMfgSrv_MfgTmpBuf4: start-on-event=SetRamBlockStatus, operation=PS_Rte_NvmBlock_CmnMfgSrv_MfgTmpBuf4.SetRamBlockStatus
        OpEventSetRamBlockStatus_SetRamBlockStatus_PS_Rte_NvmBlock_CmnMfgSrv_SeedKey: start-on-event=SetRamBlockStatus, operation=PS_Rte_NvmBlock_CmnMfgSrv_SeedKey.SetRamBlockStatus
        OpEventSetRamBlockStatus_SetRamBlockStatus_PS_Rte_NvmBlock_CmnMfgSrv_IgnCntr: start-on-event=SetRamBlockStatus, operation=PS_Rte_NvmBlock_CmnMfgSrv_IgnCntr.SetRamBlockStatus
        OpEventSetRamBlockStatus_SetRamBlockStatus_PS_Rte_NvmBlock_CmnMfgSrv_CcaSerlNr: start-on-event=SetRamBlockStatus, operation=PS_Rte_NvmBlock_CmnMfgSrv_CcaSerlNr.SetRamBlockStatus
        OpEventSetRamBlockStatus_SetRamBlockStatus_PS_Rte_NvmBlock_CDD_HwTq1Meas_HwTq1Offs: start-on-event=SetRamBlockStatus, operation=PS_Rte_NvmBlock_CDD_HwTq1Meas_HwTq1Offs.SetRamBlockStatus
        OpEventSetRamBlockStatus_SetRamBlockStatus_PS_Rte_NvmBlock_CDD_HwTq8Meas_HwTq8Offs: start-on-event=SetRamBlockStatus, operation=PS_Rte_NvmBlock_CDD_HwTq8Meas_HwTq8Offs.SetRamBlockStatus
        OpEventSetRamBlockStatus_SetRamBlockStatus_PS_Rte_NvmBlock_TEstimn_TFilStVal: start-on-event=SetRamBlockStatus, operation=PS_Rte_NvmBlock_TEstimn_TFilStVal.SetRamBlockStatus
        OpEventSetRamBlockStatus_SetRamBlockStatus_PS_Rte_NvmBlock_HwTq9Meas_HwTq9Offs: start-on-event=SetRamBlockStatus, operation=PS_Rte_NvmBlock_HwTq9Meas_HwTq9Offs.SetRamBlockStatus
        OpEventSetRamBlockStatus_SetRamBlockStatus_PS_Rte_NvmBlock_HwTq10Meas_HwTq10Offs: start-on-event=SetRamBlockStatus, operation=PS_Rte_NvmBlock_HwTq10Meas_HwTq10Offs.SetRamBlockStatus
        OpEventReadBlock_ReadBlock_PS_Rte_NvmBlock_CDD_NvMProxy_ShtdwnClsChk: start-on-event=ReadBlock, operation=PS_Rte_NvmBlock_CDD_NvMProxy_ShtdwnClsChk.ReadBlock
        OpEventReadBlock_ReadBlock_PS_Rte_NvmBlock_DiagcMgr_DiagcMgrApplCrc: start-on-event=ReadBlock, operation=PS_Rte_NvmBlock_DiagcMgr_DiagcMgrApplCrc.ReadBlock
        OpEventReadBlock_ReadBlock_PS_Rte_NvmBlock_DiagcMgr_DiagcMgrLtchCntrAry: start-on-event=ReadBlock, operation=PS_Rte_NvmBlock_DiagcMgr_DiagcMgrLtchCntrAry.ReadBlock
        OpEventReadBlock_ReadBlock_PS_Rte_NvmBlock_DiagcMgr_DiagcMgrNtcFltAry: start-on-event=ReadBlock, operation=PS_Rte_NvmBlock_DiagcMgr_DiagcMgrNtcFltAry.ReadBlock
        OpEventReadBlock_ReadBlock_PS_SnpshtDataAry: start-on-event=ReadBlock, operation=PS_SnpshtDataAry.ReadBlock
        OpEventReadBlock_ReadBlock_PS_Rte_NvmBlock_CDD_MotAgCmp_MotAgCmpMotAgBackEmf: start-on-event=ReadBlock, operation=PS_Rte_NvmBlock_CDD_MotAgCmp_MotAgCmpMotAgBackEmf.ReadBlock
        OpEventReadBlock_ReadBlock_PS_Rte_NvmBlock_MotAg2Meas_MotAg2EolPrm: start-on-event=ReadBlock, operation=PS_Rte_NvmBlock_MotAg2Meas_MotAg2EolPrm.ReadBlock
        OpEventReadBlock_ReadBlock_PS_Rte_NvmBlock_PolarityCfg_PolarityCfgSaved: start-on-event=ReadBlock, operation=PS_Rte_NvmBlock_PolarityCfg_PolarityCfgSaved.ReadBlock
        OpEventReadBlock_ReadBlock_PS_Rte_NvmBlock_CDD_CurrMeas_CurrMeasEolGainCalSetABC: start-on-event=ReadBlock, operation=PS_Rte_NvmBlock_CDD_CurrMeas_CurrMeasEolGainCalSetABC.ReadBlock
        OpEventReadBlock_ReadBlock_PS_Rte_NvmBlock_CDD_CurrMeas_CurrMeasEolOffsCalSetABC: start-on-event=ReadBlock, operation=PS_Rte_NvmBlock_CDD_CurrMeas_CurrMeasEolOffsCalSetABC.ReadBlock
        OpEventReadBlock_ReadBlock_PS_Rte_NvmBlock_HwAgSnsrls_StordLstPrm: start-on-event=ReadBlock, operation=PS_Rte_NvmBlock_HwAgSnsrls_StordLstPrm.ReadBlock
        OpEventReadBlock_ReadBlock_PS_Rte_NvmBlock_EotLrng_EotNvmData: start-on-event=ReadBlock, operation=PS_Rte_NvmBlock_EotLrng_EotNvmData.ReadBlock
        OpEventReadBlock_ReadBlock_PS_Rte_NvmBlock_EotLrng_MaxHwAgCwAndCcw: start-on-event=ReadBlock, operation=PS_Rte_NvmBlock_EotLrng_MaxHwAgCwAndCcw.ReadBlock
        OpEventReadBlock_ReadBlock_PS_Rte_NvmBlock_CDD_MotRplCoggCmd_MotCoggCmdY: start-on-event=ReadBlock, operation=PS_Rte_NvmBlock_CDD_MotRplCoggCmd_MotCoggCmdY.ReadBlock
        OpEventReadBlock_ReadBlock_PS_Rte_NvmBlock_MotRplCoggCfg_MotRplCoggPrm: start-on-event=ReadBlock, operation=PS_Rte_NvmBlock_MotRplCoggCfg_MotRplCoggPrm.ReadBlock
        OpEventReadBlock_ReadBlock_PS_Rte_NvmBlock_SysFricLrng_FricNonLrngData: start-on-event=ReadBlock, operation=PS_Rte_NvmBlock_SysFricLrng_FricNonLrngData.ReadBlock
        OpEventReadBlock_ReadBlock_PS_Rte_NvmBlock_SysFricLrng_FricLrngData: start-on-event=ReadBlock, operation=PS_Rte_NvmBlock_SysFricLrng_FricLrngData.ReadBlock
        OpEventReadBlock_ReadBlock_PS_Rte_NvmBlock_CDD_VrfyCritReg_MCalReadVrfyCritRegFltNvmInfo: start-on-event=ReadBlock, operation=PS_Rte_NvmBlock_CDD_VrfyCritReg_MCalReadVrfyCritRegFltNvmInfo.ReadBlock
        OpEventReadBlock_ReadBlock_PS_Rte_NvmBlock_HwAg1Meas_HwAg1IfFltLtch: start-on-event=ReadBlock, operation=PS_Rte_NvmBlock_HwAg1Meas_HwAg1IfFltLtch.ReadBlock
        OpEventReadBlock_ReadBlock_PS_Rte_NvmBlock_HwAg1Meas_HwAg1Offs: start-on-event=ReadBlock, operation=PS_Rte_NvmBlock_HwAg1Meas_HwAg1Offs.ReadBlock
        OpEventReadBlock_ReadBlock_PS_Rte_NvmBlock_CDD_MotAg5Meas_MotAg5EolPrm: start-on-event=ReadBlock, operation=PS_Rte_NvmBlock_CDD_MotAg5Meas_MotAg5EolPrm.ReadBlock
        OpEventReadBlock_ReadBlock_PS_Rte_NvmBlock_CDD_MotAg6Meas_MotAg6StVari: start-on-event=ReadBlock, operation=PS_Rte_NvmBlock_CDD_MotAg6Meas_MotAg6StVari.ReadBlock
        OpEventReadBlock_ReadBlock_PS_Rte_NvmBlock_CDD_MotAg6Meas_MotAg6EolPrm: start-on-event=ReadBlock, operation=PS_Rte_NvmBlock_CDD_MotAg6Meas_MotAg6EolPrm.ReadBlock
        OpEventReadBlock_ReadBlock_PS_Rte_NvmBlock_CDD_MotAg5Meas_MotAg5StVari: start-on-event=ReadBlock, operation=PS_Rte_NvmBlock_CDD_MotAg5Meas_MotAg5StVari.ReadBlock
        OpEventReadBlock_ReadBlock_PS_Rte_NvmBlock_MotCtrlPrmEstimn_MotPrmNom: start-on-event=ReadBlock, operation=PS_Rte_NvmBlock_MotCtrlPrmEstimn_MotPrmNom.ReadBlock
        OpEventReadBlock_ReadBlock_PS_Deprecated_Rte_NvmBlock_HwTqCorrln_HwTqChACmnModCmpLpFilSt: start-on-event=ReadBlock, operation=PS_Deprecated_Rte_NvmBlock_HwTqCorrln_HwTqChACmnModCmpLpFilSt.ReadBlock
        OpEventReadBlock_ReadBlock_PS_Rte_NvmBlock_MotTqCmdSca_MotTqScaFac: start-on-event=ReadBlock, operation=PS_Rte_NvmBlock_MotTqCmdSca_MotTqScaFac.ReadBlock
        OpEventReadBlock_ReadBlock_PS_Rte_NvmBlock_DutyCycThermProtn_FilStVal: start-on-event=ReadBlock, operation=PS_Rte_NvmBlock_DutyCycThermProtn_FilStVal.ReadBlock
        OpEventReadBlock_ReadBlock_PS_Rte_NvmBlock_CmnMfgSrv_MfgTmpBuf1: start-on-event=ReadBlock, operation=PS_Rte_NvmBlock_CmnMfgSrv_MfgTmpBuf1.ReadBlock
        OpEventReadBlock_ReadBlock_PS_Rte_NvmBlock_CmnMfgSrv_DiRestore: start-on-event=ReadBlock, operation=PS_Rte_NvmBlock_CmnMfgSrv_DiRestore.ReadBlock
        OpEventReadBlock_ReadBlock_PS_Rte_NvmBlock_CmnMfgSrv_NxtrMfgEnaCntr: start-on-event=ReadBlock, operation=PS_Rte_NvmBlock_CmnMfgSrv_NxtrMfgEnaCntr.ReadBlock
        OpEventReadBlock_ReadBlock_PS_Rte_NvmBlock_CmnMfgSrv_MfgTmpBuf0: start-on-event=ReadBlock, operation=PS_Rte_NvmBlock_CmnMfgSrv_MfgTmpBuf0.ReadBlock
        OpEventReadBlock_ReadBlock_PS_Rte_NvmBlock_CmnMfgSrv_MfgTmpBuf3: start-on-event=ReadBlock, operation=PS_Rte_NvmBlock_CmnMfgSrv_MfgTmpBuf3.ReadBlock
        OpEventReadBlock_ReadBlock_PS_Rte_NvmBlock_CmnMfgSrv_EpsSysSerlNr: start-on-event=ReadBlock, operation=PS_Rte_NvmBlock_CmnMfgSrv_EpsSysSerlNr.ReadBlock
        OpEventReadBlock_ReadBlock_PS_Rte_NvmBlock_CmnMfgSrv_MfgTmpBuf2: start-on-event=ReadBlock, operation=PS_Rte_NvmBlock_CmnMfgSrv_MfgTmpBuf2.ReadBlock
        OpEventReadBlock_ReadBlock_PS_Rte_NvmBlock_CmnMfgSrv_CcaHwPartNr: start-on-event=ReadBlock, operation=PS_Rte_NvmBlock_CmnMfgSrv_CcaHwPartNr.ReadBlock
        OpEventReadBlock_ReadBlock_PS_Rte_NvmBlock_CmnMfgSrv_MfgTmpBuf4: start-on-event=ReadBlock, operation=PS_Rte_NvmBlock_CmnMfgSrv_MfgTmpBuf4.ReadBlock
        OpEventReadBlock_ReadBlock_PS_Rte_NvmBlock_CmnMfgSrv_SeedKey: start-on-event=ReadBlock, operation=PS_Rte_NvmBlock_CmnMfgSrv_SeedKey.ReadBlock
        OpEventReadBlock_ReadBlock_PS_Rte_NvmBlock_CmnMfgSrv_IgnCntr: start-on-event=ReadBlock, operation=PS_Rte_NvmBlock_CmnMfgSrv_IgnCntr.ReadBlock
        OpEventReadBlock_ReadBlock_PS_Rte_NvmBlock_CmnMfgSrv_CcaSerlNr: start-on-event=ReadBlock, operation=PS_Rte_NvmBlock_CmnMfgSrv_CcaSerlNr.ReadBlock
        OpEventReadBlock_ReadBlock_PS_Rte_NvmBlock_CDD_HwTq1Meas_HwTq1Offs: start-on-event=ReadBlock, operation=PS_Rte_NvmBlock_CDD_HwTq1Meas_HwTq1Offs.ReadBlock
        OpEventReadBlock_ReadBlock_PS_Rte_NvmBlock_CDD_HwTq8Meas_HwTq8Offs: start-on-event=ReadBlock, operation=PS_Rte_NvmBlock_CDD_HwTq8Meas_HwTq8Offs.ReadBlock
        OpEventReadBlock_ReadBlock_PS_Rte_NvmBlock_TEstimn_TFilStVal: start-on-event=ReadBlock, operation=PS_Rte_NvmBlock_TEstimn_TFilStVal.ReadBlock
        OpEventReadBlock_ReadBlock_PS_Rte_NvmBlock_HwTq9Meas_HwTq9Offs: start-on-event=ReadBlock, operation=PS_Rte_NvmBlock_HwTq9Meas_HwTq9Offs.ReadBlock
        OpEventReadBlock_ReadBlock_PS_Rte_NvmBlock_HwTq10Meas_HwTq10Offs: start-on-event=ReadBlock, operation=PS_Rte_NvmBlock_HwTq10Meas_HwTq10Offs.ReadBlock
        OpEventWriteBlock_WriteBlock_PS_Rte_NvmBlock_CDD_NvMProxy_ShtdwnClsChk: start-on-event=WriteBlock, operation=PS_Rte_NvmBlock_CDD_NvMProxy_ShtdwnClsChk.WriteBlock
        OpEventWriteBlock_WriteBlock_PS_Rte_NvmBlock_DiagcMgr_DiagcMgrApplCrc: start-on-event=WriteBlock, operation=PS_Rte_NvmBlock_DiagcMgr_DiagcMgrApplCrc.WriteBlock
        OpEventWriteBlock_WriteBlock_PS_Rte_NvmBlock_DiagcMgr_DiagcMgrLtchCntrAry: start-on-event=WriteBlock, operation=PS_Rte_NvmBlock_DiagcMgr_DiagcMgrLtchCntrAry.WriteBlock
        OpEventWriteBlock_WriteBlock_PS_Rte_NvmBlock_DiagcMgr_DiagcMgrNtcFltAry: start-on-event=WriteBlock, operation=PS_Rte_NvmBlock_DiagcMgr_DiagcMgrNtcFltAry.WriteBlock
        OpEventWriteBlock_WriteBlock_PS_SnpshtDataAry: start-on-event=WriteBlock, operation=PS_SnpshtDataAry.WriteBlock
        OpEventWriteBlock_WriteBlock_PS_Rte_NvmBlock_CDD_MotAgCmp_MotAgCmpMotAgBackEmf: start-on-event=WriteBlock, operation=PS_Rte_NvmBlock_CDD_MotAgCmp_MotAgCmpMotAgBackEmf.WriteBlock
        OpEventWriteBlock_WriteBlock_PS_Rte_NvmBlock_MotAg2Meas_MotAg2EolPrm: start-on-event=WriteBlock, operation=PS_Rte_NvmBlock_MotAg2Meas_MotAg2EolPrm.WriteBlock
        OpEventWriteBlock_WriteBlock_PS_Rte_NvmBlock_PolarityCfg_PolarityCfgSaved: start-on-event=WriteBlock, operation=PS_Rte_NvmBlock_PolarityCfg_PolarityCfgSaved.WriteBlock
        OpEventWriteBlock_WriteBlock_PS_Rte_NvmBlock_CDD_CurrMeas_CurrMeasEolGainCalSetABC: start-on-event=WriteBlock, operation=PS_Rte_NvmBlock_CDD_CurrMeas_CurrMeasEolGainCalSetABC.WriteBlock
        OpEventWriteBlock_WriteBlock_PS_Rte_NvmBlock_CDD_CurrMeas_CurrMeasEolOffsCalSetABC: start-on-event=WriteBlock, operation=PS_Rte_NvmBlock_CDD_CurrMeas_CurrMeasEolOffsCalSetABC.WriteBlock
        OpEventWriteBlock_WriteBlock_PS_Rte_NvmBlock_HwAgSnsrls_StordLstPrm: start-on-event=WriteBlock, operation=PS_Rte_NvmBlock_HwAgSnsrls_StordLstPrm.WriteBlock
        OpEventWriteBlock_WriteBlock_PS_Rte_NvmBlock_EotLrng_EotNvmData: start-on-event=WriteBlock, operation=PS_Rte_NvmBlock_EotLrng_EotNvmData.WriteBlock
        OpEventWriteBlock_WriteBlock_PS_Rte_NvmBlock_EotLrng_MaxHwAgCwAndCcw: start-on-event=WriteBlock, operation=PS_Rte_NvmBlock_EotLrng_MaxHwAgCwAndCcw.WriteBlock
        OpEventWriteBlock_WriteBlock_PS_Rte_NvmBlock_CDD_MotRplCoggCmd_MotCoggCmdY: start-on-event=WriteBlock, operation=PS_Rte_NvmBlock_CDD_MotRplCoggCmd_MotCoggCmdY.WriteBlock
        OpEventWriteBlock_WriteBlock_PS_Rte_NvmBlock_MotRplCoggCfg_MotRplCoggPrm: start-on-event=WriteBlock, operation=PS_Rte_NvmBlock_MotRplCoggCfg_MotRplCoggPrm.WriteBlock
        OpEventWriteBlock_WriteBlock_PS_Rte_NvmBlock_SysFricLrng_FricNonLrngData: start-on-event=WriteBlock, operation=PS_Rte_NvmBlock_SysFricLrng_FricNonLrngData.WriteBlock
        OpEventWriteBlock_WriteBlock_PS_Rte_NvmBlock_SysFricLrng_FricLrngData: start-on-event=WriteBlock, operation=PS_Rte_NvmBlock_SysFricLrng_FricLrngData.WriteBlock
        OpEventWriteBlock_WriteBlock_PS_Rte_NvmBlock_CDD_VrfyCritReg_MCalReadVrfyCritRegFltNvmInfo: start-on-event=WriteBlock, operation=PS_Rte_NvmBlock_CDD_VrfyCritReg_MCalReadVrfyCritRegFltNvmInfo.WriteBlock
        OpEventWriteBlock_WriteBlock_PS_Rte_NvmBlock_HwAg1Meas_HwAg1IfFltLtch: start-on-event=WriteBlock, operation=PS_Rte_NvmBlock_HwAg1Meas_HwAg1IfFltLtch.WriteBlock
        OpEventWriteBlock_WriteBlock_PS_Rte_NvmBlock_HwAg1Meas_HwAg1Offs: start-on-event=WriteBlock, operation=PS_Rte_NvmBlock_HwAg1Meas_HwAg1Offs.WriteBlock
        OpEventWriteBlock_WriteBlock_PS_Rte_NvmBlock_CDD_MotAg5Meas_MotAg5EolPrm: start-on-event=WriteBlock, operation=PS_Rte_NvmBlock_CDD_MotAg5Meas_MotAg5EolPrm.WriteBlock
        OpEventWriteBlock_WriteBlock_PS_Rte_NvmBlock_CDD_MotAg6Meas_MotAg6StVari: start-on-event=WriteBlock, operation=PS_Rte_NvmBlock_CDD_MotAg6Meas_MotAg6StVari.WriteBlock
        OpEventWriteBlock_WriteBlock_PS_Rte_NvmBlock_CDD_MotAg6Meas_MotAg6EolPrm: start-on-event=WriteBlock, operation=PS_Rte_NvmBlock_CDD_MotAg6Meas_MotAg6EolPrm.WriteBlock
        OpEventWriteBlock_WriteBlock_PS_Rte_NvmBlock_CDD_MotAg5Meas_MotAg5StVari: start-on-event=WriteBlock, operation=PS_Rte_NvmBlock_CDD_MotAg5Meas_MotAg5StVari.WriteBlock
        OpEventWriteBlock_WriteBlock_PS_Rte_NvmBlock_MotCtrlPrmEstimn_MotPrmNom: start-on-event=WriteBlock, operation=PS_Rte_NvmBlock_MotCtrlPrmEstimn_MotPrmNom.WriteBlock
        OpEventWriteBlock_WriteBlock_PS_Deprecated_Rte_NvmBlock_HwTqCorrln_HwTqChACmnModCmpLpFilSt: start-on-event=WriteBlock, operation=PS_Deprecated_Rte_NvmBlock_HwTqCorrln_HwTqChACmnModCmpLpFilSt.WriteBlock
        OpEventWriteBlock_WriteBlock_PS_Rte_NvmBlock_MotTqCmdSca_MotTqScaFac: start-on-event=WriteBlock, operation=PS_Rte_NvmBlock_MotTqCmdSca_MotTqScaFac.WriteBlock
        OpEventWriteBlock_WriteBlock_PS_Rte_NvmBlock_DutyCycThermProtn_FilStVal: start-on-event=WriteBlock, operation=PS_Rte_NvmBlock_DutyCycThermProtn_FilStVal.WriteBlock
        OpEventWriteBlock_WriteBlock_PS_Rte_NvmBlock_CmnMfgSrv_MfgTmpBuf1: start-on-event=WriteBlock, operation=PS_Rte_NvmBlock_CmnMfgSrv_MfgTmpBuf1.WriteBlock
        OpEventWriteBlock_WriteBlock_PS_Rte_NvmBlock_CmnMfgSrv_DiRestore: start-on-event=WriteBlock, operation=PS_Rte_NvmBlock_CmnMfgSrv_DiRestore.WriteBlock
        OpEventWriteBlock_WriteBlock_PS_Rte_NvmBlock_CmnMfgSrv_NxtrMfgEnaCntr: start-on-event=WriteBlock, operation=PS_Rte_NvmBlock_CmnMfgSrv_NxtrMfgEnaCntr.WriteBlock
        OpEventWriteBlock_WriteBlock_PS_Rte_NvmBlock_CmnMfgSrv_MfgTmpBuf0: start-on-event=WriteBlock, operation=PS_Rte_NvmBlock_CmnMfgSrv_MfgTmpBuf0.WriteBlock
        OpEventWriteBlock_WriteBlock_PS_Rte_NvmBlock_CmnMfgSrv_MfgTmpBuf3: start-on-event=WriteBlock, operation=PS_Rte_NvmBlock_CmnMfgSrv_MfgTmpBuf3.WriteBlock
        OpEventWriteBlock_WriteBlock_PS_Rte_NvmBlock_CmnMfgSrv_EpsSysSerlNr: start-on-event=WriteBlock, operation=PS_Rte_NvmBlock_CmnMfgSrv_EpsSysSerlNr.WriteBlock
        OpEventWriteBlock_WriteBlock_PS_Rte_NvmBlock_CmnMfgSrv_MfgTmpBuf2: start-on-event=WriteBlock, operation=PS_Rte_NvmBlock_CmnMfgSrv_MfgTmpBuf2.WriteBlock
        OpEventWriteBlock_WriteBlock_PS_Rte_NvmBlock_CmnMfgSrv_CcaHwPartNr: start-on-event=WriteBlock, operation=PS_Rte_NvmBlock_CmnMfgSrv_CcaHwPartNr.WriteBlock
        OpEventWriteBlock_WriteBlock_PS_Rte_NvmBlock_CmnMfgSrv_MfgTmpBuf4: start-on-event=WriteBlock, operation=PS_Rte_NvmBlock_CmnMfgSrv_MfgTmpBuf4.WriteBlock
        OpEventWriteBlock_WriteBlock_PS_Rte_NvmBlock_CmnMfgSrv_SeedKey: start-on-event=WriteBlock, operation=PS_Rte_NvmBlock_CmnMfgSrv_SeedKey.WriteBlock
        OpEventWriteBlock_WriteBlock_PS_Rte_NvmBlock_CmnMfgSrv_IgnCntr: start-on-event=WriteBlock, operation=PS_Rte_NvmBlock_CmnMfgSrv_IgnCntr.WriteBlock
        OpEventWriteBlock_WriteBlock_PS_Rte_NvmBlock_CmnMfgSrv_CcaSerlNr: start-on-event=WriteBlock, operation=PS_Rte_NvmBlock_CmnMfgSrv_CcaSerlNr.WriteBlock
        OpEventWriteBlock_WriteBlock_PS_Rte_NvmBlock_CDD_HwTq1Meas_HwTq1Offs: start-on-event=WriteBlock, operation=PS_Rte_NvmBlock_CDD_HwTq1Meas_HwTq1Offs.WriteBlock
        OpEventWriteBlock_WriteBlock_PS_Rte_NvmBlock_CDD_HwTq8Meas_HwTq8Offs: start-on-event=WriteBlock, operation=PS_Rte_NvmBlock_CDD_HwTq8Meas_HwTq8Offs.WriteBlock
        OpEventWriteBlock_WriteBlock_PS_Rte_NvmBlock_TEstimn_TFilStVal: start-on-event=WriteBlock, operation=PS_Rte_NvmBlock_TEstimn_TFilStVal.WriteBlock
        OpEventWriteBlock_WriteBlock_PS_Rte_NvmBlock_HwTq9Meas_HwTq9Offs: start-on-event=WriteBlock, operation=PS_Rte_NvmBlock_HwTq9Meas_HwTq9Offs.WriteBlock
        OpEventWriteBlock_WriteBlock_PS_Rte_NvmBlock_HwTq10Meas_HwTq10Offs: start-on-event=WriteBlock, operation=PS_Rte_NvmBlock_HwTq10Meas_HwTq10Offs.WriteBlock
        OpEventInvalidateNvBlock_InvalidateNvBlock_PS_Rte_NvmBlock_CDD_NvMProxy_ShtdwnClsChk: start-on-event=InvalidateNvBlock, operation=PS_Rte_NvmBlock_CDD_NvMProxy_ShtdwnClsChk.InvalidateNvBlock
        OpEventInvalidateNvBlock_InvalidateNvBlock_PS_Rte_NvmBlock_DiagcMgr_DiagcMgrApplCrc: start-on-event=InvalidateNvBlock, operation=PS_Rte_NvmBlock_DiagcMgr_DiagcMgrApplCrc.InvalidateNvBlock
        OpEventInvalidateNvBlock_InvalidateNvBlock_PS_Rte_NvmBlock_DiagcMgr_DiagcMgrLtchCntrAry: start-on-event=InvalidateNvBlock, operation=PS_Rte_NvmBlock_DiagcMgr_DiagcMgrLtchCntrAry.InvalidateNvBlock
        OpEventInvalidateNvBlock_InvalidateNvBlock_PS_Rte_NvmBlock_DiagcMgr_DiagcMgrNtcFltAry: start-on-event=InvalidateNvBlock, operation=PS_Rte_NvmBlock_DiagcMgr_DiagcMgrNtcFltAry.InvalidateNvBlock
        OpEventInvalidateNvBlock_InvalidateNvBlock_PS_SnpshtDataAry: start-on-event=InvalidateNvBlock, operation=PS_SnpshtDataAry.InvalidateNvBlock
        OpEventInvalidateNvBlock_InvalidateNvBlock_PS_Rte_NvmBlock_CDD_MotAgCmp_MotAgCmpMotAgBackEmf: start-on-event=InvalidateNvBlock, operation=PS_Rte_NvmBlock_CDD_MotAgCmp_MotAgCmpMotAgBackEmf.InvalidateNvBlock
        OpEventInvalidateNvBlock_InvalidateNvBlock_PS_Rte_NvmBlock_MotAg2Meas_MotAg2EolPrm: start-on-event=InvalidateNvBlock, operation=PS_Rte_NvmBlock_MotAg2Meas_MotAg2EolPrm.InvalidateNvBlock
        OpEventInvalidateNvBlock_InvalidateNvBlock_PS_Rte_NvmBlock_PolarityCfg_PolarityCfgSaved: start-on-event=InvalidateNvBlock, operation=PS_Rte_NvmBlock_PolarityCfg_PolarityCfgSaved.InvalidateNvBlock
        OpEventInvalidateNvBlock_InvalidateNvBlock_PS_Rte_NvmBlock_CDD_CurrMeas_CurrMeasEolGainCalSetABC: start-on-event=InvalidateNvBlock, operation=PS_Rte_NvmBlock_CDD_CurrMeas_CurrMeasEolGainCalSetABC.InvalidateNvBlock
        OpEventInvalidateNvBlock_InvalidateNvBlock_PS_Rte_NvmBlock_CDD_CurrMeas_CurrMeasEolOffsCalSetABC: start-on-event=InvalidateNvBlock, operation=PS_Rte_NvmBlock_CDD_CurrMeas_CurrMeasEolOffsCalSetABC.InvalidateNvBlock
        OpEventInvalidateNvBlock_InvalidateNvBlock_PS_Rte_NvmBlock_HwAgSnsrls_StordLstPrm: start-on-event=InvalidateNvBlock, operation=PS_Rte_NvmBlock_HwAgSnsrls_StordLstPrm.InvalidateNvBlock
        OpEventInvalidateNvBlock_InvalidateNvBlock_PS_Rte_NvmBlock_EotLrng_EotNvmData: start-on-event=InvalidateNvBlock, operation=PS_Rte_NvmBlock_EotLrng_EotNvmData.InvalidateNvBlock
        OpEventInvalidateNvBlock_InvalidateNvBlock_PS_Rte_NvmBlock_EotLrng_MaxHwAgCwAndCcw: start-on-event=InvalidateNvBlock, operation=PS_Rte_NvmBlock_EotLrng_MaxHwAgCwAndCcw.InvalidateNvBlock
        OpEventInvalidateNvBlock_InvalidateNvBlock_PS_Rte_NvmBlock_CDD_MotRplCoggCmd_MotCoggCmdY: start-on-event=InvalidateNvBlock, operation=PS_Rte_NvmBlock_CDD_MotRplCoggCmd_MotCoggCmdY.InvalidateNvBlock
        OpEventInvalidateNvBlock_InvalidateNvBlock_PS_Rte_NvmBlock_MotRplCoggCfg_MotRplCoggPrm: start-on-event=InvalidateNvBlock, operation=PS_Rte_NvmBlock_MotRplCoggCfg_MotRplCoggPrm.InvalidateNvBlock
        OpEventInvalidateNvBlock_InvalidateNvBlock_PS_Rte_NvmBlock_SysFricLrng_FricNonLrngData: start-on-event=InvalidateNvBlock, operation=PS_Rte_NvmBlock_SysFricLrng_FricNonLrngData.InvalidateNvBlock
        OpEventInvalidateNvBlock_InvalidateNvBlock_PS_Rte_NvmBlock_SysFricLrng_FricLrngData: start-on-event=InvalidateNvBlock, operation=PS_Rte_NvmBlock_SysFricLrng_FricLrngData.InvalidateNvBlock
        OpEventInvalidateNvBlock_InvalidateNvBlock_PS_Rte_NvmBlock_CDD_VrfyCritReg_MCalReadVrfyCritRegFltNvmInfo: start-on-event=InvalidateNvBlock, operation=PS_Rte_NvmBlock_CDD_VrfyCritReg_MCalReadVrfyCritRegFltNvmInfo.InvalidateNvBlock
        OpEventInvalidateNvBlock_InvalidateNvBlock_PS_Rte_NvmBlock_HwAg1Meas_HwAg1IfFltLtch: start-on-event=InvalidateNvBlock, operation=PS_Rte_NvmBlock_HwAg1Meas_HwAg1IfFltLtch.InvalidateNvBlock
        OpEventInvalidateNvBlock_InvalidateNvBlock_PS_Rte_NvmBlock_HwAg1Meas_HwAg1Offs: start-on-event=InvalidateNvBlock, operation=PS_Rte_NvmBlock_HwAg1Meas_HwAg1Offs.InvalidateNvBlock
        OpEventInvalidateNvBlock_InvalidateNvBlock_PS_Rte_NvmBlock_CDD_MotAg5Meas_MotAg5EolPrm: start-on-event=InvalidateNvBlock, operation=PS_Rte_NvmBlock_CDD_MotAg5Meas_MotAg5EolPrm.InvalidateNvBlock
        OpEventInvalidateNvBlock_InvalidateNvBlock_PS_Rte_NvmBlock_CDD_MotAg6Meas_MotAg6StVari: start-on-event=InvalidateNvBlock, operation=PS_Rte_NvmBlock_CDD_MotAg6Meas_MotAg6StVari.InvalidateNvBlock
        OpEventInvalidateNvBlock_InvalidateNvBlock_PS_Rte_NvmBlock_CDD_MotAg6Meas_MotAg6EolPrm: start-on-event=InvalidateNvBlock, operation=PS_Rte_NvmBlock_CDD_MotAg6Meas_MotAg6EolPrm.InvalidateNvBlock
        OpEventInvalidateNvBlock_InvalidateNvBlock_PS_Rte_NvmBlock_CDD_MotAg5Meas_MotAg5StVari: start-on-event=InvalidateNvBlock, operation=PS_Rte_NvmBlock_CDD_MotAg5Meas_MotAg5StVari.InvalidateNvBlock
        OpEventInvalidateNvBlock_InvalidateNvBlock_PS_Rte_NvmBlock_MotCtrlPrmEstimn_MotPrmNom: start-on-event=InvalidateNvBlock, operation=PS_Rte_NvmBlock_MotCtrlPrmEstimn_MotPrmNom.InvalidateNvBlock
        OpEventInvalidateNvBlock_InvalidateNvBlock_PS_Deprecated_Rte_NvmBlock_HwTqCorrln_HwTqChACmnModCmpLpFilSt: start-on-event=InvalidateNvBlock, operation=PS_Deprecated_Rte_NvmBlock_HwTqCorrln_HwTqChACmnModCmpLpFilSt.InvalidateNvBlock
        OpEventInvalidateNvBlock_InvalidateNvBlock_PS_Rte_NvmBlock_MotTqCmdSca_MotTqScaFac: start-on-event=InvalidateNvBlock, operation=PS_Rte_NvmBlock_MotTqCmdSca_MotTqScaFac.InvalidateNvBlock
        OpEventInvalidateNvBlock_InvalidateNvBlock_PS_Rte_NvmBlock_DutyCycThermProtn_FilStVal: start-on-event=InvalidateNvBlock, operation=PS_Rte_NvmBlock_DutyCycThermProtn_FilStVal.InvalidateNvBlock
        OpEventInvalidateNvBlock_InvalidateNvBlock_PS_Rte_NvmBlock_CmnMfgSrv_MfgTmpBuf1: start-on-event=InvalidateNvBlock, operation=PS_Rte_NvmBlock_CmnMfgSrv_MfgTmpBuf1.InvalidateNvBlock
        OpEventInvalidateNvBlock_InvalidateNvBlock_PS_Rte_NvmBlock_CmnMfgSrv_DiRestore: start-on-event=InvalidateNvBlock, operation=PS_Rte_NvmBlock_CmnMfgSrv_DiRestore.InvalidateNvBlock
        OpEventInvalidateNvBlock_InvalidateNvBlock_PS_Rte_NvmBlock_CmnMfgSrv_NxtrMfgEnaCntr: start-on-event=InvalidateNvBlock, operation=PS_Rte_NvmBlock_CmnMfgSrv_NxtrMfgEnaCntr.InvalidateNvBlock
        OpEventInvalidateNvBlock_InvalidateNvBlock_PS_Rte_NvmBlock_CmnMfgSrv_MfgTmpBuf0: start-on-event=InvalidateNvBlock, operation=PS_Rte_NvmBlock_CmnMfgSrv_MfgTmpBuf0.InvalidateNvBlock
        OpEventInvalidateNvBlock_InvalidateNvBlock_PS_Rte_NvmBlock_CmnMfgSrv_MfgTmpBuf3: start-on-event=InvalidateNvBlock, operation=PS_Rte_NvmBlock_CmnMfgSrv_MfgTmpBuf3.InvalidateNvBlock
        OpEventInvalidateNvBlock_InvalidateNvBlock_PS_Rte_NvmBlock_CmnMfgSrv_EpsSysSerlNr: start-on-event=InvalidateNvBlock, operation=PS_Rte_NvmBlock_CmnMfgSrv_EpsSysSerlNr.InvalidateNvBlock
        OpEventInvalidateNvBlock_InvalidateNvBlock_PS_Rte_NvmBlock_CmnMfgSrv_MfgTmpBuf2: start-on-event=InvalidateNvBlock, operation=PS_Rte_NvmBlock_CmnMfgSrv_MfgTmpBuf2.InvalidateNvBlock
        OpEventInvalidateNvBlock_InvalidateNvBlock_PS_Rte_NvmBlock_CmnMfgSrv_CcaHwPartNr: start-on-event=InvalidateNvBlock, operation=PS_Rte_NvmBlock_CmnMfgSrv_CcaHwPartNr.InvalidateNvBlock
        OpEventInvalidateNvBlock_InvalidateNvBlock_PS_Rte_NvmBlock_CmnMfgSrv_MfgTmpBuf4: start-on-event=InvalidateNvBlock, operation=PS_Rte_NvmBlock_CmnMfgSrv_MfgTmpBuf4.InvalidateNvBlock
        OpEventInvalidateNvBlock_InvalidateNvBlock_PS_Rte_NvmBlock_CmnMfgSrv_SeedKey: start-on-event=InvalidateNvBlock, operation=PS_Rte_NvmBlock_CmnMfgSrv_SeedKey.InvalidateNvBlock
        OpEventInvalidateNvBlock_InvalidateNvBlock_PS_Rte_NvmBlock_CmnMfgSrv_IgnCntr: start-on-event=InvalidateNvBlock, operation=PS_Rte_NvmBlock_CmnMfgSrv_IgnCntr.InvalidateNvBlock
        OpEventInvalidateNvBlock_InvalidateNvBlock_PS_Rte_NvmBlock_CmnMfgSrv_CcaSerlNr: start-on-event=InvalidateNvBlock, operation=PS_Rte_NvmBlock_CmnMfgSrv_CcaSerlNr.InvalidateNvBlock
        OpEventInvalidateNvBlock_InvalidateNvBlock_PS_Rte_NvmBlock_CDD_HwTq1Meas_HwTq1Offs: start-on-event=InvalidateNvBlock, operation=PS_Rte_NvmBlock_CDD_HwTq1Meas_HwTq1Offs.InvalidateNvBlock
        OpEventInvalidateNvBlock_InvalidateNvBlock_PS_Rte_NvmBlock_CDD_HwTq8Meas_HwTq8Offs: start-on-event=InvalidateNvBlock, operation=PS_Rte_NvmBlock_CDD_HwTq8Meas_HwTq8Offs.InvalidateNvBlock
        OpEventInvalidateNvBlock_InvalidateNvBlock_PS_Rte_NvmBlock_TEstimn_TFilStVal: start-on-event=InvalidateNvBlock, operation=PS_Rte_NvmBlock_TEstimn_TFilStVal.InvalidateNvBlock
        OpEventInvalidateNvBlock_InvalidateNvBlock_PS_Rte_NvmBlock_HwTq9Meas_HwTq9Offs: start-on-event=InvalidateNvBlock, operation=PS_Rte_NvmBlock_HwTq9Meas_HwTq9Offs.InvalidateNvBlock
        OpEventInvalidateNvBlock_InvalidateNvBlock_PS_Rte_NvmBlock_HwTq10Meas_HwTq10Offs: start-on-event=InvalidateNvBlock, operation=PS_Rte_NvmBlock_HwTq10Meas_HwTq10Offs.InvalidateNvBlock
        OpEventEraseBlock_EraseBlock_PS_Rte_NvmBlock_CDD_NvMProxy_ShtdwnClsChk: start-on-event=EraseBlock, operation=PS_Rte_NvmBlock_CDD_NvMProxy_ShtdwnClsChk.EraseBlock
        OpEventEraseBlock_EraseBlock_PS_Rte_NvmBlock_DiagcMgr_DiagcMgrApplCrc: start-on-event=EraseBlock, operation=PS_Rte_NvmBlock_DiagcMgr_DiagcMgrApplCrc.EraseBlock
        OpEventEraseBlock_EraseBlock_PS_Rte_NvmBlock_DiagcMgr_DiagcMgrLtchCntrAry: start-on-event=EraseBlock, operation=PS_Rte_NvmBlock_DiagcMgr_DiagcMgrLtchCntrAry.EraseBlock
        OpEventEraseBlock_EraseBlock_PS_Rte_NvmBlock_DiagcMgr_DiagcMgrNtcFltAry: start-on-event=EraseBlock, operation=PS_Rte_NvmBlock_DiagcMgr_DiagcMgrNtcFltAry.EraseBlock
        OpEventEraseBlock_EraseBlock_PS_SnpshtDataAry: start-on-event=EraseBlock, operation=PS_SnpshtDataAry.EraseBlock
        OpEventEraseBlock_EraseBlock_PS_Rte_NvmBlock_CDD_MotAgCmp_MotAgCmpMotAgBackEmf: start-on-event=EraseBlock, operation=PS_Rte_NvmBlock_CDD_MotAgCmp_MotAgCmpMotAgBackEmf.EraseBlock
        OpEventEraseBlock_EraseBlock_PS_Rte_NvmBlock_MotAg2Meas_MotAg2EolPrm: start-on-event=EraseBlock, operation=PS_Rte_NvmBlock_MotAg2Meas_MotAg2EolPrm.EraseBlock
        OpEventEraseBlock_EraseBlock_PS_Rte_NvmBlock_PolarityCfg_PolarityCfgSaved: start-on-event=EraseBlock, operation=PS_Rte_NvmBlock_PolarityCfg_PolarityCfgSaved.EraseBlock
        OpEventEraseBlock_EraseBlock_PS_Rte_NvmBlock_CDD_CurrMeas_CurrMeasEolGainCalSetABC: start-on-event=EraseBlock, operation=PS_Rte_NvmBlock_CDD_CurrMeas_CurrMeasEolGainCalSetABC.EraseBlock
        OpEventEraseBlock_EraseBlock_PS_Rte_NvmBlock_CDD_CurrMeas_CurrMeasEolOffsCalSetABC: start-on-event=EraseBlock, operation=PS_Rte_NvmBlock_CDD_CurrMeas_CurrMeasEolOffsCalSetABC.EraseBlock
        OpEventEraseBlock_EraseBlock_PS_Rte_NvmBlock_HwAgSnsrls_StordLstPrm: start-on-event=EraseBlock, operation=PS_Rte_NvmBlock_HwAgSnsrls_StordLstPrm.EraseBlock
        OpEventEraseBlock_EraseBlock_PS_Rte_NvmBlock_EotLrng_EotNvmData: start-on-event=EraseBlock, operation=PS_Rte_NvmBlock_EotLrng_EotNvmData.EraseBlock
        OpEventEraseBlock_EraseBlock_PS_Rte_NvmBlock_EotLrng_MaxHwAgCwAndCcw: start-on-event=EraseBlock, operation=PS_Rte_NvmBlock_EotLrng_MaxHwAgCwAndCcw.EraseBlock
        OpEventEraseBlock_EraseBlock_PS_Rte_NvmBlock_CDD_MotRplCoggCmd_MotCoggCmdY: start-on-event=EraseBlock, operation=PS_Rte_NvmBlock_CDD_MotRplCoggCmd_MotCoggCmdY.EraseBlock
        OpEventEraseBlock_EraseBlock_PS_Rte_NvmBlock_MotRplCoggCfg_MotRplCoggPrm: start-on-event=EraseBlock, operation=PS_Rte_NvmBlock_MotRplCoggCfg_MotRplCoggPrm.EraseBlock
        OpEventEraseBlock_EraseBlock_PS_Rte_NvmBlock_SysFricLrng_FricNonLrngData: start-on-event=EraseBlock, operation=PS_Rte_NvmBlock_SysFricLrng_FricNonLrngData.EraseBlock
        OpEventEraseBlock_EraseBlock_PS_Rte_NvmBlock_SysFricLrng_FricLrngData: start-on-event=EraseBlock, operation=PS_Rte_NvmBlock_SysFricLrng_FricLrngData.EraseBlock
        OpEventEraseBlock_EraseBlock_PS_Rte_NvmBlock_CDD_VrfyCritReg_MCalReadVrfyCritRegFltNvmInfo: start-on-event=EraseBlock, operation=PS_Rte_NvmBlock_CDD_VrfyCritReg_MCalReadVrfyCritRegFltNvmInfo.EraseBlock
        OpEventEraseBlock_EraseBlock_PS_Rte_NvmBlock_HwAg1Meas_HwAg1IfFltLtch: start-on-event=EraseBlock, operation=PS_Rte_NvmBlock_HwAg1Meas_HwAg1IfFltLtch.EraseBlock
        OpEventEraseBlock_EraseBlock_PS_Rte_NvmBlock_HwAg1Meas_HwAg1Offs: start-on-event=EraseBlock, operation=PS_Rte_NvmBlock_HwAg1Meas_HwAg1Offs.EraseBlock
        OpEventEraseBlock_EraseBlock_PS_Rte_NvmBlock_CDD_MotAg5Meas_MotAg5EolPrm: start-on-event=EraseBlock, operation=PS_Rte_NvmBlock_CDD_MotAg5Meas_MotAg5EolPrm.EraseBlock
        OpEventEraseBlock_EraseBlock_PS_Rte_NvmBlock_CDD_MotAg6Meas_MotAg6StVari: start-on-event=EraseBlock, operation=PS_Rte_NvmBlock_CDD_MotAg6Meas_MotAg6StVari.EraseBlock
        OpEventEraseBlock_EraseBlock_PS_Rte_NvmBlock_CDD_MotAg6Meas_MotAg6EolPrm: start-on-event=EraseBlock, operation=PS_Rte_NvmBlock_CDD_MotAg6Meas_MotAg6EolPrm.EraseBlock
        OpEventEraseBlock_EraseBlock_PS_Rte_NvmBlock_CDD_MotAg5Meas_MotAg5StVari: start-on-event=EraseBlock, operation=PS_Rte_NvmBlock_CDD_MotAg5Meas_MotAg5StVari.EraseBlock
        OpEventEraseBlock_EraseBlock_PS_Rte_NvmBlock_MotCtrlPrmEstimn_MotPrmNom: start-on-event=EraseBlock, operation=PS_Rte_NvmBlock_MotCtrlPrmEstimn_MotPrmNom.EraseBlock
        OpEventEraseBlock_EraseBlock_PS_Deprecated_Rte_NvmBlock_HwTqCorrln_HwTqChACmnModCmpLpFilSt: start-on-event=EraseBlock, operation=PS_Deprecated_Rte_NvmBlock_HwTqCorrln_HwTqChACmnModCmpLpFilSt.EraseBlock
        OpEventEraseBlock_EraseBlock_PS_Rte_NvmBlock_MotTqCmdSca_MotTqScaFac: start-on-event=EraseBlock, operation=PS_Rte_NvmBlock_MotTqCmdSca_MotTqScaFac.EraseBlock
        OpEventEraseBlock_EraseBlock_PS_Rte_NvmBlock_DutyCycThermProtn_FilStVal: start-on-event=EraseBlock, operation=PS_Rte_NvmBlock_DutyCycThermProtn_FilStVal.EraseBlock
        OpEventEraseBlock_EraseBlock_PS_Rte_NvmBlock_CmnMfgSrv_MfgTmpBuf1: start-on-event=EraseBlock, operation=PS_Rte_NvmBlock_CmnMfgSrv_MfgTmpBuf1.EraseBlock
        OpEventEraseBlock_EraseBlock_PS_Rte_NvmBlock_CmnMfgSrv_DiRestore: start-on-event=EraseBlock, operation=PS_Rte_NvmBlock_CmnMfgSrv_DiRestore.EraseBlock
        OpEventEraseBlock_EraseBlock_PS_Rte_NvmBlock_CmnMfgSrv_NxtrMfgEnaCntr: start-on-event=EraseBlock, operation=PS_Rte_NvmBlock_CmnMfgSrv_NxtrMfgEnaCntr.EraseBlock
        OpEventEraseBlock_EraseBlock_PS_Rte_NvmBlock_CmnMfgSrv_MfgTmpBuf0: start-on-event=EraseBlock, operation=PS_Rte_NvmBlock_CmnMfgSrv_MfgTmpBuf0.EraseBlock
        OpEventEraseBlock_EraseBlock_PS_Rte_NvmBlock_CmnMfgSrv_MfgTmpBuf3: start-on-event=EraseBlock, operation=PS_Rte_NvmBlock_CmnMfgSrv_MfgTmpBuf3.EraseBlock
        OpEventEraseBlock_EraseBlock_PS_Rte_NvmBlock_CmnMfgSrv_EpsSysSerlNr: start-on-event=EraseBlock, operation=PS_Rte_NvmBlock_CmnMfgSrv_EpsSysSerlNr.EraseBlock
        OpEventEraseBlock_EraseBlock_PS_Rte_NvmBlock_CmnMfgSrv_MfgTmpBuf2: start-on-event=EraseBlock, operation=PS_Rte_NvmBlock_CmnMfgSrv_MfgTmpBuf2.EraseBlock
        OpEventEraseBlock_EraseBlock_PS_Rte_NvmBlock_CmnMfgSrv_CcaHwPartNr: start-on-event=EraseBlock, operation=PS_Rte_NvmBlock_CmnMfgSrv_CcaHwPartNr.EraseBlock
        OpEventEraseBlock_EraseBlock_PS_Rte_NvmBlock_CmnMfgSrv_MfgTmpBuf4: start-on-event=EraseBlock, operation=PS_Rte_NvmBlock_CmnMfgSrv_MfgTmpBuf4.EraseBlock
        OpEventEraseBlock_EraseBlock_PS_Rte_NvmBlock_CmnMfgSrv_SeedKey: start-on-event=EraseBlock, operation=PS_Rte_NvmBlock_CmnMfgSrv_SeedKey.EraseBlock
        OpEventEraseBlock_EraseBlock_PS_Rte_NvmBlock_CmnMfgSrv_IgnCntr: start-on-event=EraseBlock, operation=PS_Rte_NvmBlock_CmnMfgSrv_IgnCntr.EraseBlock
        OpEventEraseBlock_EraseBlock_PS_Rte_NvmBlock_CmnMfgSrv_CcaSerlNr: start-on-event=EraseBlock, operation=PS_Rte_NvmBlock_CmnMfgSrv_CcaSerlNr.EraseBlock
        OpEventEraseBlock_EraseBlock_PS_Rte_NvmBlock_CDD_HwTq1Meas_HwTq1Offs: start-on-event=EraseBlock, operation=PS_Rte_NvmBlock_CDD_HwTq1Meas_HwTq1Offs.EraseBlock
        OpEventEraseBlock_EraseBlock_PS_Rte_NvmBlock_CDD_HwTq8Meas_HwTq8Offs: start-on-event=EraseBlock, operation=PS_Rte_NvmBlock_CDD_HwTq8Meas_HwTq8Offs.EraseBlock
        OpEventEraseBlock_EraseBlock_PS_Rte_NvmBlock_TEstimn_TFilStVal: start-on-event=EraseBlock, operation=PS_Rte_NvmBlock_TEstimn_TFilStVal.EraseBlock
        OpEventEraseBlock_EraseBlock_PS_Rte_NvmBlock_HwTq9Meas_HwTq9Offs: start-on-event=EraseBlock, operation=PS_Rte_NvmBlock_HwTq9Meas_HwTq9Offs.EraseBlock
        OpEventEraseBlock_EraseBlock_PS_Rte_NvmBlock_HwTq10Meas_HwTq10Offs: start-on-event=EraseBlock, operation=PS_Rte_NvmBlock_HwTq10Meas_HwTq10Offs.EraseBlock
        OpEventSetBlockProtection_SetBlockProtection_PAdmin_Rte_NvmBlock_CDD_NvMProxy_ShtdwnClsChk: start-on-event=SetBlockProtection, operation=PAdmin_Rte_NvmBlock_CDD_NvMProxy_ShtdwnClsChk.SetBlockProtection
        OpEventSetBlockProtection_SetBlockProtection_PAdmin_Rte_NvmBlock_DiagcMgr_DiagcMgrApplCrc: start-on-event=SetBlockProtection, operation=PAdmin_Rte_NvmBlock_DiagcMgr_DiagcMgrApplCrc.SetBlockProtection
        OpEventSetBlockProtection_SetBlockProtection_PAdmin_Rte_NvmBlock_DiagcMgr_DiagcMgrLtchCntrAry: start-on-event=SetBlockProtection, operation=PAdmin_Rte_NvmBlock_DiagcMgr_DiagcMgrLtchCntrAry.SetBlockProtection
        OpEventSetBlockProtection_SetBlockProtection_PAdmin_Rte_NvmBlock_DiagcMgr_DiagcMgrNtcFltAry: start-on-event=SetBlockProtection, operation=PAdmin_Rte_NvmBlock_DiagcMgr_DiagcMgrNtcFltAry.SetBlockProtection
        OpEventSetBlockProtection_SetBlockProtection_PAdmin_SnpshtDataAry: start-on-event=SetBlockProtection, operation=PAdmin_SnpshtDataAry.SetBlockProtection
        OpEventSetBlockProtection_SetBlockProtection_PAdmin_Rte_NvmBlock_CDD_MotAgCmp_MotAgCmpMotAgBackEmf: start-on-event=SetBlockProtection, operation=PAdmin_Rte_NvmBlock_CDD_MotAgCmp_MotAgCmpMotAgBackEmf.SetBlockProtection
        OpEventSetBlockProtection_SetBlockProtection_PAdmin_Rte_NvmBlock_MotAg2Meas_MotAg2EolPrm: start-on-event=SetBlockProtection, operation=PAdmin_Rte_NvmBlock_MotAg2Meas_MotAg2EolPrm.SetBlockProtection
        OpEventSetBlockProtection_SetBlockProtection_PAdmin_Rte_NvmBlock_PolarityCfg_PolarityCfgSaved: start-on-event=SetBlockProtection, operation=PAdmin_Rte_NvmBlock_PolarityCfg_PolarityCfgSaved.SetBlockProtection
        OpEventSetBlockProtection_SetBlockProtection_PAdmin_Rte_NvmBlock_CDD_CurrMeas_CurrMeasEolGainCalSetABC: start-on-event=SetBlockProtection, operation=PAdmin_Rte_NvmBlock_CDD_CurrMeas_CurrMeasEolGainCalSetABC.SetBlockProtection
        OpEventSetBlockProtection_SetBlockProtection_PAdmin_Rte_NvmBlock_CDD_CurrMeas_CurrMeasEolOffsCalSetABC: start-on-event=SetBlockProtection, operation=PAdmin_Rte_NvmBlock_CDD_CurrMeas_CurrMeasEolOffsCalSetABC.SetBlockProtection
        OpEventSetBlockProtection_SetBlockProtection_PAdmin_Rte_NvmBlock_HwAgSnsrls_StordLstPrm: start-on-event=SetBlockProtection, operation=PAdmin_Rte_NvmBlock_HwAgSnsrls_StordLstPrm.SetBlockProtection
        OpEventSetBlockProtection_SetBlockProtection_PAdmin_Rte_NvmBlock_EotLrng_EotNvmData: start-on-event=SetBlockProtection, operation=PAdmin_Rte_NvmBlock_EotLrng_EotNvmData.SetBlockProtection
        OpEventSetBlockProtection_SetBlockProtection_PAdmin_Rte_NvmBlock_EotLrng_MaxHwAgCwAndCcw: start-on-event=SetBlockProtection, operation=PAdmin_Rte_NvmBlock_EotLrng_MaxHwAgCwAndCcw.SetBlockProtection
        OpEventSetBlockProtection_SetBlockProtection_PAdmin_Rte_NvmBlock_CDD_MotRplCoggCmd_MotCoggCmdY: start-on-event=SetBlockProtection, operation=PAdmin_Rte_NvmBlock_CDD_MotRplCoggCmd_MotCoggCmdY.SetBlockProtection
        OpEventSetBlockProtection_SetBlockProtection_PAdmin_Rte_NvmBlock_MotRplCoggCfg_MotRplCoggPrm: start-on-event=SetBlockProtection, operation=PAdmin_Rte_NvmBlock_MotRplCoggCfg_MotRplCoggPrm.SetBlockProtection
        OpEventSetBlockProtection_SetBlockProtection_PAdmin_Rte_NvmBlock_SysFricLrng_FricNonLrngData: start-on-event=SetBlockProtection, operation=PAdmin_Rte_NvmBlock_SysFricLrng_FricNonLrngData.SetBlockProtection
        OpEventSetBlockProtection_SetBlockProtection_PAdmin_Rte_NvmBlock_SysFricLrng_FricLrngData: start-on-event=SetBlockProtection, operation=PAdmin_Rte_NvmBlock_SysFricLrng_FricLrngData.SetBlockProtection
        OpEventSetBlockProtection_SetBlockProtection_PAdmin_Rte_NvmBlock_CDD_VrfyCritReg_MCalReadVrfyCritRegFltNvmInfo: start-on-event=SetBlockProtection, operation=PAdmin_Rte_NvmBlock_CDD_VrfyCritReg_MCalReadVrfyCritRegFltNvmInfo.SetBlockProtection
        OpEventSetBlockProtection_SetBlockProtection_PAdmin_Rte_NvmBlock_HwAg1Meas_HwAg1IfFltLtch: start-on-event=SetBlockProtection, operation=PAdmin_Rte_NvmBlock_HwAg1Meas_HwAg1IfFltLtch.SetBlockProtection
        OpEventSetBlockProtection_SetBlockProtection_PAdmin_Rte_NvmBlock_HwAg1Meas_HwAg1Offs: start-on-event=SetBlockProtection, operation=PAdmin_Rte_NvmBlock_HwAg1Meas_HwAg1Offs.SetBlockProtection
        OpEventSetBlockProtection_SetBlockProtection_PAdmin_Rte_NvmBlock_CDD_MotAg5Meas_MotAg5EolPrm: start-on-event=SetBlockProtection, operation=PAdmin_Rte_NvmBlock_CDD_MotAg5Meas_MotAg5EolPrm.SetBlockProtection
        OpEventSetBlockProtection_SetBlockProtection_PAdmin_Rte_NvmBlock_CDD_MotAg6Meas_MotAg6StVari: start-on-event=SetBlockProtection, operation=PAdmin_Rte_NvmBlock_CDD_MotAg6Meas_MotAg6StVari.SetBlockProtection
        OpEventSetBlockProtection_SetBlockProtection_PAdmin_Rte_NvmBlock_CDD_MotAg6Meas_MotAg6EolPrm: start-on-event=SetBlockProtection, operation=PAdmin_Rte_NvmBlock_CDD_MotAg6Meas_MotAg6EolPrm.SetBlockProtection
        OpEventSetBlockProtection_SetBlockProtection_PAdmin_Rte_NvmBlock_CDD_MotAg5Meas_MotAg5StVari: start-on-event=SetBlockProtection, operation=PAdmin_Rte_NvmBlock_CDD_MotAg5Meas_MotAg5StVari.SetBlockProtection
        OpEventSetBlockProtection_SetBlockProtection_PAdmin_Rte_NvmBlock_MotCtrlPrmEstimn_MotPrmNom: start-on-event=SetBlockProtection, operation=PAdmin_Rte_NvmBlock_MotCtrlPrmEstimn_MotPrmNom.SetBlockProtection
        OpEventSetBlockProtection_SetBlockProtection_PAdmin_Deprecated_Rte_NvmBlock_HwTqCorrln_HwTqChACmnModCmpLpFilSt: start-on-event=SetBlockProtection, operation=PAdmin_Deprecated_Rte_NvmBlock_HwTqCorrln_HwTqChACmnModCmpLpFilSt.SetBlockProtection
        OpEventSetBlockProtection_SetBlockProtection_PAdmin_Rte_NvmBlock_MotTqCmdSca_MotTqScaFac: start-on-event=SetBlockProtection, operation=PAdmin_Rte_NvmBlock_MotTqCmdSca_MotTqScaFac.SetBlockProtection
        OpEventSetBlockProtection_SetBlockProtection_PAdmin_Rte_NvmBlock_DutyCycThermProtn_FilStVal: start-on-event=SetBlockProtection, operation=PAdmin_Rte_NvmBlock_DutyCycThermProtn_FilStVal.SetBlockProtection
        OpEventSetBlockProtection_SetBlockProtection_PAdmin_Rte_NvmBlock_CmnMfgSrv_MfgTmpBuf1: start-on-event=SetBlockProtection, operation=PAdmin_Rte_NvmBlock_CmnMfgSrv_MfgTmpBuf1.SetBlockProtection
        OpEventSetBlockProtection_SetBlockProtection_PAdmin_Rte_NvmBlock_CmnMfgSrv_DiRestore: start-on-event=SetBlockProtection, operation=PAdmin_Rte_NvmBlock_CmnMfgSrv_DiRestore.SetBlockProtection
        OpEventSetBlockProtection_SetBlockProtection_PAdmin_Rte_NvmBlock_CmnMfgSrv_NxtrMfgEnaCntr: start-on-event=SetBlockProtection, operation=PAdmin_Rte_NvmBlock_CmnMfgSrv_NxtrMfgEnaCntr.SetBlockProtection
        OpEventSetBlockProtection_SetBlockProtection_PAdmin_Rte_NvmBlock_CmnMfgSrv_MfgTmpBuf0: start-on-event=SetBlockProtection, operation=PAdmin_Rte_NvmBlock_CmnMfgSrv_MfgTmpBuf0.SetBlockProtection
        OpEventSetBlockProtection_SetBlockProtection_PAdmin_Rte_NvmBlock_CmnMfgSrv_MfgTmpBuf3: start-on-event=SetBlockProtection, operation=PAdmin_Rte_NvmBlock_CmnMfgSrv_MfgTmpBuf3.SetBlockProtection
        OpEventSetBlockProtection_SetBlockProtection_PAdmin_Rte_NvmBlock_CmnMfgSrv_EpsSysSerlNr: start-on-event=SetBlockProtection, operation=PAdmin_Rte_NvmBlock_CmnMfgSrv_EpsSysSerlNr.SetBlockProtection
        OpEventSetBlockProtection_SetBlockProtection_PAdmin_Rte_NvmBlock_CmnMfgSrv_MfgTmpBuf2: start-on-event=SetBlockProtection, operation=PAdmin_Rte_NvmBlock_CmnMfgSrv_MfgTmpBuf2.SetBlockProtection
        OpEventSetBlockProtection_SetBlockProtection_PAdmin_Rte_NvmBlock_CmnMfgSrv_CcaHwPartNr: start-on-event=SetBlockProtection, operation=PAdmin_Rte_NvmBlock_CmnMfgSrv_CcaHwPartNr.SetBlockProtection
        OpEventSetBlockProtection_SetBlockProtection_PAdmin_Rte_NvmBlock_CmnMfgSrv_MfgTmpBuf4: start-on-event=SetBlockProtection, operation=PAdmin_Rte_NvmBlock_CmnMfgSrv_MfgTmpBuf4.SetBlockProtection
        OpEventSetBlockProtection_SetBlockProtection_PAdmin_Rte_NvmBlock_CmnMfgSrv_SeedKey: start-on-event=SetBlockProtection, operation=PAdmin_Rte_NvmBlock_CmnMfgSrv_SeedKey.SetBlockProtection
        OpEventSetBlockProtection_SetBlockProtection_PAdmin_Rte_NvmBlock_CmnMfgSrv_IgnCntr: start-on-event=SetBlockProtection, operation=PAdmin_Rte_NvmBlock_CmnMfgSrv_IgnCntr.SetBlockProtection
        OpEventSetBlockProtection_SetBlockProtection_PAdmin_Rte_NvmBlock_CmnMfgSrv_CcaSerlNr: start-on-event=SetBlockProtection, operation=PAdmin_Rte_NvmBlock_CmnMfgSrv_CcaSerlNr.SetBlockProtection
        OpEventSetBlockProtection_SetBlockProtection_PAdmin_Rte_NvmBlock_CDD_HwTq1Meas_HwTq1Offs: start-on-event=SetBlockProtection, operation=PAdmin_Rte_NvmBlock_CDD_HwTq1Meas_HwTq1Offs.SetBlockProtection
        OpEventSetBlockProtection_SetBlockProtection_PAdmin_Rte_NvmBlock_CDD_HwTq8Meas_HwTq8Offs: start-on-event=SetBlockProtection, operation=PAdmin_Rte_NvmBlock_CDD_HwTq8Meas_HwTq8Offs.SetBlockProtection
        OpEventSetBlockProtection_SetBlockProtection_PAdmin_Rte_NvmBlock_TEstimn_TFilStVal: start-on-event=SetBlockProtection, operation=PAdmin_Rte_NvmBlock_TEstimn_TFilStVal.SetBlockProtection
        OpEventSetBlockProtection_SetBlockProtection_PAdmin_Rte_NvmBlock_HwTq9Meas_HwTq9Offs: start-on-event=SetBlockProtection, operation=PAdmin_Rte_NvmBlock_HwTq9Meas_HwTq9Offs.SetBlockProtection
        OpEventSetBlockProtection_SetBlockProtection_PAdmin_Rte_NvmBlock_HwTq10Meas_HwTq10Offs: start-on-event=SetBlockProtection, operation=PAdmin_Rte_NvmBlock_HwTq10Meas_HwTq10Offs.SetBlockProtection
        OpEventRestoreBlockDefaults_RestoreBlockDefaults_PS_Rte_NvmBlock_DiagcMgr_DiagcMgrApplCrc: start-on-event=RestoreBlockDefaults, operation=PS_Rte_NvmBlock_DiagcMgr_DiagcMgrApplCrc.RestoreBlockDefaults
        OpEventRestoreBlockDefaults_RestoreBlockDefaults_PS_Rte_NvmBlock_CDD_MotAgCmp_MotAgCmpMotAgBackEmf: start-on-event=RestoreBlockDefaults, operation=PS_Rte_NvmBlock_CDD_MotAgCmp_MotAgCmpMotAgBackEmf.RestoreBlockDefaults
        OpEventRestoreBlockDefaults_RestoreBlockDefaults_PS_Rte_NvmBlock_MotAg2Meas_MotAg2EolPrm: start-on-event=RestoreBlockDefaults, operation=PS_Rte_NvmBlock_MotAg2Meas_MotAg2EolPrm.RestoreBlockDefaults
        OpEventRestoreBlockDefaults_RestoreBlockDefaults_PS_Rte_NvmBlock_PolarityCfg_PolarityCfgSaved: start-on-event=RestoreBlockDefaults, operation=PS_Rte_NvmBlock_PolarityCfg_PolarityCfgSaved.RestoreBlockDefaults
        OpEventRestoreBlockDefaults_RestoreBlockDefaults_PS_Rte_NvmBlock_CDD_CurrMeas_CurrMeasEolGainCalSetABC: start-on-event=RestoreBlockDefaults, operation=PS_Rte_NvmBlock_CDD_CurrMeas_CurrMeasEolGainCalSetABC.RestoreBlockDefaults
        OpEventRestoreBlockDefaults_RestoreBlockDefaults_PS_Rte_NvmBlock_CDD_CurrMeas_CurrMeasEolOffsCalSetABC: start-on-event=RestoreBlockDefaults, operation=PS_Rte_NvmBlock_CDD_CurrMeas_CurrMeasEolOffsCalSetABC.RestoreBlockDefaults
        OpEventRestoreBlockDefaults_RestoreBlockDefaults_PS_Rte_NvmBlock_HwAgSnsrls_StordLstPrm: start-on-event=RestoreBlockDefaults, operation=PS_Rte_NvmBlock_HwAgSnsrls_StordLstPrm.RestoreBlockDefaults
        OpEventRestoreBlockDefaults_RestoreBlockDefaults_PS_Rte_NvmBlock_SysFricLrng_FricNonLrngData: start-on-event=RestoreBlockDefaults, operation=PS_Rte_NvmBlock_SysFricLrng_FricNonLrngData.RestoreBlockDefaults
        OpEventRestoreBlockDefaults_RestoreBlockDefaults_PS_Rte_NvmBlock_SysFricLrng_FricLrngData: start-on-event=RestoreBlockDefaults, operation=PS_Rte_NvmBlock_SysFricLrng_FricLrngData.RestoreBlockDefaults
        OpEventRestoreBlockDefaults_RestoreBlockDefaults_PS_Rte_NvmBlock_CmnMfgSrv_NxtrMfgEnaCntr: start-on-event=RestoreBlockDefaults, operation=PS_Rte_NvmBlock_CmnMfgSrv_NxtrMfgEnaCntr.RestoreBlockDefaults
        OpEventRestoreBlockDefaults_RestoreBlockDefaults_PS_Rte_NvmBlock_CmnMfgSrv_SeedKey: start-on-event=RestoreBlockDefaults, operation=PS_Rte_NvmBlock_CmnMfgSrv_SeedKey.RestoreBlockDefaults
        OpEventRestoreBlockDefaults_RestoreBlockDefaults_PS_Rte_NvmBlock_CmnMfgSrv_IgnCntr: start-on-event=RestoreBlockDefaults, operation=PS_Rte_NvmBlock_CmnMfgSrv_IgnCntr.RestoreBlockDefaults
        OpEventRestoreBlockDefaults_RestoreBlockDefaults_PS_Rte_NvmBlock_CDD_HwTq1Meas_HwTq1Offs: start-on-event=RestoreBlockDefaults, operation=PS_Rte_NvmBlock_CDD_HwTq1Meas_HwTq1Offs.RestoreBlockDefaults
        OpEventRestoreBlockDefaults_RestoreBlockDefaults_PS_Rte_NvmBlock_CDD_HwTq8Meas_HwTq8Offs: start-on-event=RestoreBlockDefaults, operation=PS_Rte_NvmBlock_CDD_HwTq8Meas_HwTq8Offs.RestoreBlockDefaults
        OpEventGetErrorStatus_GetErrorStatus_PS_Rte_NvmBlock_CustDiag_DidDE04: start-on-event=GetErrorStatus, operation=PS_Rte_NvmBlock_CustDiag_DidDE04.GetErrorStatus
        OpEventGetErrorStatus_GetErrorStatus_PS_Rte_NvmBlock_CustDiag_Did3003: start-on-event=GetErrorStatus, operation=PS_Rte_NvmBlock_CustDiag_Did3003.GetErrorStatus
        OpEventGetErrorStatus_GetErrorStatus_PS_Rte_NvmBlock_CustDiag_DidEE01: start-on-event=GetErrorStatus, operation=PS_Rte_NvmBlock_CustDiag_DidEE01.GetErrorStatus
        OpEventGetErrorStatus_GetErrorStatus_PS_Rte_NvmBlock_CustDiag_DidF111: start-on-event=GetErrorStatus, operation=PS_Rte_NvmBlock_CustDiag_DidF111.GetErrorStatus
        OpEventGetErrorStatus_GetErrorStatus_PS_Rte_NvmBlock_CustDiag_DidF113: start-on-event=GetErrorStatus, operation=PS_Rte_NvmBlock_CustDiag_DidF113.GetErrorStatus
        OpEventGetErrorStatus_GetErrorStatus_PS_Rte_NvmBlock_CustDiag_DidEE02: start-on-event=GetErrorStatus, operation=PS_Rte_NvmBlock_CustDiag_DidEE02.GetErrorStatus
        OpEventGetErrorStatus_GetErrorStatus_PS_Rte_NvmBlock_CustDiag_DidDE02: start-on-event=GetErrorStatus, operation=PS_Rte_NvmBlock_CustDiag_DidDE02.GetErrorStatus
        OpEventGetErrorStatus_GetErrorStatus_PS_Rte_NvmBlock_CustDiag_DidDE03: start-on-event=GetErrorStatus, operation=PS_Rte_NvmBlock_CustDiag_DidDE03.GetErrorStatus
        OpEventGetErrorStatus_GetErrorStatus_PS_Rte_NvmBlock_CustDiag_DidDE00: start-on-event=GetErrorStatus, operation=PS_Rte_NvmBlock_CustDiag_DidDE00.GetErrorStatus
        OpEventGetErrorStatus_GetErrorStatus_PS_Rte_NvmBlock_CustDiag_DidDE01: start-on-event=GetErrorStatus, operation=PS_Rte_NvmBlock_CustDiag_DidDE01.GetErrorStatus
        OpEventSetRamBlockStatus_SetRamBlockStatus_PS_Rte_NvmBlock_CustDiag_DidDE04: start-on-event=SetRamBlockStatus, operation=PS_Rte_NvmBlock_CustDiag_DidDE04.SetRamBlockStatus
        OpEventSetRamBlockStatus_SetRamBlockStatus_PS_Rte_NvmBlock_CustDiag_Did3003: start-on-event=SetRamBlockStatus, operation=PS_Rte_NvmBlock_CustDiag_Did3003.SetRamBlockStatus
        OpEventSetRamBlockStatus_SetRamBlockStatus_PS_Rte_NvmBlock_CustDiag_DidEE01: start-on-event=SetRamBlockStatus, operation=PS_Rte_NvmBlock_CustDiag_DidEE01.SetRamBlockStatus
        OpEventSetRamBlockStatus_SetRamBlockStatus_PS_Rte_NvmBlock_CustDiag_DidF111: start-on-event=SetRamBlockStatus, operation=PS_Rte_NvmBlock_CustDiag_DidF111.SetRamBlockStatus
        OpEventSetRamBlockStatus_SetRamBlockStatus_PS_Rte_NvmBlock_CustDiag_DidF113: start-on-event=SetRamBlockStatus, operation=PS_Rte_NvmBlock_CustDiag_DidF113.SetRamBlockStatus
        OpEventSetRamBlockStatus_SetRamBlockStatus_PS_Rte_NvmBlock_CustDiag_DidEE02: start-on-event=SetRamBlockStatus, operation=PS_Rte_NvmBlock_CustDiag_DidEE02.SetRamBlockStatus
        OpEventSetRamBlockStatus_SetRamBlockStatus_PS_Rte_NvmBlock_CustDiag_DidDE02: start-on-event=SetRamBlockStatus, operation=PS_Rte_NvmBlock_CustDiag_DidDE02.SetRamBlockStatus
        OpEventSetRamBlockStatus_SetRamBlockStatus_PS_Rte_NvmBlock_CustDiag_DidDE03: start-on-event=SetRamBlockStatus, operation=PS_Rte_NvmBlock_CustDiag_DidDE03.SetRamBlockStatus
        OpEventSetRamBlockStatus_SetRamBlockStatus_PS_Rte_NvmBlock_CustDiag_DidDE00: start-on-event=SetRamBlockStatus, operation=PS_Rte_NvmBlock_CustDiag_DidDE00.SetRamBlockStatus
        OpEventSetRamBlockStatus_SetRamBlockStatus_PS_Rte_NvmBlock_CustDiag_DidDE01: start-on-event=SetRamBlockStatus, operation=PS_Rte_NvmBlock_CustDiag_DidDE01.SetRamBlockStatus
        OpEventReadBlock_ReadBlock_PS_Rte_NvmBlock_CustDiag_DidDE04: start-on-event=ReadBlock, operation=PS_Rte_NvmBlock_CustDiag_DidDE04.ReadBlock
        OpEventReadBlock_ReadBlock_PS_Rte_NvmBlock_CustDiag_Did3003: start-on-event=ReadBlock, operation=PS_Rte_NvmBlock_CustDiag_Did3003.ReadBlock
        OpEventReadBlock_ReadBlock_PS_Rte_NvmBlock_CustDiag_DidEE01: start-on-event=ReadBlock, operation=PS_Rte_NvmBlock_CustDiag_DidEE01.ReadBlock
        OpEventReadBlock_ReadBlock_PS_Rte_NvmBlock_CustDiag_DidF111: start-on-event=ReadBlock, operation=PS_Rte_NvmBlock_CustDiag_DidF111.ReadBlock
        OpEventReadBlock_ReadBlock_PS_Rte_NvmBlock_CustDiag_DidF113: start-on-event=ReadBlock, operation=PS_Rte_NvmBlock_CustDiag_DidF113.ReadBlock
        OpEventReadBlock_ReadBlock_PS_Rte_NvmBlock_CustDiag_DidEE02: start-on-event=ReadBlock, operation=PS_Rte_NvmBlock_CustDiag_DidEE02.ReadBlock
        OpEventReadBlock_ReadBlock_PS_Rte_NvmBlock_CustDiag_DidDE02: start-on-event=ReadBlock, operation=PS_Rte_NvmBlock_CustDiag_DidDE02.ReadBlock
        OpEventReadBlock_ReadBlock_PS_Rte_NvmBlock_CustDiag_DidDE03: start-on-event=ReadBlock, operation=PS_Rte_NvmBlock_CustDiag_DidDE03.ReadBlock
        OpEventReadBlock_ReadBlock_PS_Rte_NvmBlock_CustDiag_DidDE00: start-on-event=ReadBlock, operation=PS_Rte_NvmBlock_CustDiag_DidDE00.ReadBlock
        OpEventReadBlock_ReadBlock_PS_Rte_NvmBlock_CustDiag_DidDE01: start-on-event=ReadBlock, operation=PS_Rte_NvmBlock_CustDiag_DidDE01.ReadBlock
        OpEventWriteBlock_WriteBlock_PS_Rte_NvmBlock_CustDiag_DidDE04: start-on-event=WriteBlock, operation=PS_Rte_NvmBlock_CustDiag_DidDE04.WriteBlock
        OpEventWriteBlock_WriteBlock_PS_Rte_NvmBlock_CustDiag_Did3003: start-on-event=WriteBlock, operation=PS_Rte_NvmBlock_CustDiag_Did3003.WriteBlock
        OpEventWriteBlock_WriteBlock_PS_Rte_NvmBlock_CustDiag_DidEE01: start-on-event=WriteBlock, operation=PS_Rte_NvmBlock_CustDiag_DidEE01.WriteBlock
        OpEventWriteBlock_WriteBlock_PS_Rte_NvmBlock_CustDiag_DidF111: start-on-event=WriteBlock, operation=PS_Rte_NvmBlock_CustDiag_DidF111.WriteBlock
        OpEventWriteBlock_WriteBlock_PS_Rte_NvmBlock_CustDiag_DidF113: start-on-event=WriteBlock, operation=PS_Rte_NvmBlock_CustDiag_DidF113.WriteBlock
        OpEventWriteBlock_WriteBlock_PS_Rte_NvmBlock_CustDiag_DidEE02: start-on-event=WriteBlock, operation=PS_Rte_NvmBlock_CustDiag_DidEE02.WriteBlock
        OpEventWriteBlock_WriteBlock_PS_Rte_NvmBlock_CustDiag_DidDE02: start-on-event=WriteBlock, operation=PS_Rte_NvmBlock_CustDiag_DidDE02.WriteBlock
        OpEventWriteBlock_WriteBlock_PS_Rte_NvmBlock_CustDiag_DidDE03: start-on-event=WriteBlock, operation=PS_Rte_NvmBlock_CustDiag_DidDE03.WriteBlock
        OpEventWriteBlock_WriteBlock_PS_Rte_NvmBlock_CustDiag_DidDE00: start-on-event=WriteBlock, operation=PS_Rte_NvmBlock_CustDiag_DidDE00.WriteBlock
        OpEventWriteBlock_WriteBlock_PS_Rte_NvmBlock_CustDiag_DidDE01: start-on-event=WriteBlock, operation=PS_Rte_NvmBlock_CustDiag_DidDE01.WriteBlock
        OpEventInvalidateNvBlock_InvalidateNvBlock_PS_Rte_NvmBlock_CustDiag_DidDE04: start-on-event=InvalidateNvBlock, operation=PS_Rte_NvmBlock_CustDiag_DidDE04.InvalidateNvBlock
        OpEventInvalidateNvBlock_InvalidateNvBlock_PS_Rte_NvmBlock_CustDiag_Did3003: start-on-event=InvalidateNvBlock, operation=PS_Rte_NvmBlock_CustDiag_Did3003.InvalidateNvBlock
        OpEventInvalidateNvBlock_InvalidateNvBlock_PS_Rte_NvmBlock_CustDiag_DidEE01: start-on-event=InvalidateNvBlock, operation=PS_Rte_NvmBlock_CustDiag_DidEE01.InvalidateNvBlock
        OpEventInvalidateNvBlock_InvalidateNvBlock_PS_Rte_NvmBlock_CustDiag_DidF111: start-on-event=InvalidateNvBlock, operation=PS_Rte_NvmBlock_CustDiag_DidF111.InvalidateNvBlock
        OpEventInvalidateNvBlock_InvalidateNvBlock_PS_Rte_NvmBlock_CustDiag_DidF113: start-on-event=InvalidateNvBlock, operation=PS_Rte_NvmBlock_CustDiag_DidF113.InvalidateNvBlock
        OpEventInvalidateNvBlock_InvalidateNvBlock_PS_Rte_NvmBlock_CustDiag_DidEE02: start-on-event=InvalidateNvBlock, operation=PS_Rte_NvmBlock_CustDiag_DidEE02.InvalidateNvBlock
        OpEventInvalidateNvBlock_InvalidateNvBlock_PS_Rte_NvmBlock_CustDiag_DidDE02: start-on-event=InvalidateNvBlock, operation=PS_Rte_NvmBlock_CustDiag_DidDE02.InvalidateNvBlock
        OpEventInvalidateNvBlock_InvalidateNvBlock_PS_Rte_NvmBlock_CustDiag_DidDE03: start-on-event=InvalidateNvBlock, operation=PS_Rte_NvmBlock_CustDiag_DidDE03.InvalidateNvBlock
        OpEventInvalidateNvBlock_InvalidateNvBlock_PS_Rte_NvmBlock_CustDiag_DidDE00: start-on-event=InvalidateNvBlock, operation=PS_Rte_NvmBlock_CustDiag_DidDE00.InvalidateNvBlock
        OpEventInvalidateNvBlock_InvalidateNvBlock_PS_Rte_NvmBlock_CustDiag_DidDE01: start-on-event=InvalidateNvBlock, operation=PS_Rte_NvmBlock_CustDiag_DidDE01.InvalidateNvBlock
        OpEventEraseBlock_EraseBlock_PS_Rte_NvmBlock_CustDiag_DidDE04: start-on-event=EraseBlock, operation=PS_Rte_NvmBlock_CustDiag_DidDE04.EraseBlock
        OpEventEraseBlock_EraseBlock_PS_Rte_NvmBlock_CustDiag_Did3003: start-on-event=EraseBlock, operation=PS_Rte_NvmBlock_CustDiag_Did3003.EraseBlock
        OpEventEraseBlock_EraseBlock_PS_Rte_NvmBlock_CustDiag_DidEE01: start-on-event=EraseBlock, operation=PS_Rte_NvmBlock_CustDiag_DidEE01.EraseBlock
        OpEventEraseBlock_EraseBlock_PS_Rte_NvmBlock_CustDiag_DidF111: start-on-event=EraseBlock, operation=PS_Rte_NvmBlock_CustDiag_DidF111.EraseBlock
        OpEventEraseBlock_EraseBlock_PS_Rte_NvmBlock_CustDiag_DidF113: start-on-event=EraseBlock, operation=PS_Rte_NvmBlock_CustDiag_DidF113.EraseBlock
        OpEventEraseBlock_EraseBlock_PS_Rte_NvmBlock_CustDiag_DidEE02: start-on-event=EraseBlock, operation=PS_Rte_NvmBlock_CustDiag_DidEE02.EraseBlock
        OpEventEraseBlock_EraseBlock_PS_Rte_NvmBlock_CustDiag_DidDE02: start-on-event=EraseBlock, operation=PS_Rte_NvmBlock_CustDiag_DidDE02.EraseBlock
        OpEventEraseBlock_EraseBlock_PS_Rte_NvmBlock_CustDiag_DidDE03: start-on-event=EraseBlock, operation=PS_Rte_NvmBlock_CustDiag_DidDE03.EraseBlock
        OpEventEraseBlock_EraseBlock_PS_Rte_NvmBlock_CustDiag_DidDE00: start-on-event=EraseBlock, operation=PS_Rte_NvmBlock_CustDiag_DidDE00.EraseBlock
        OpEventEraseBlock_EraseBlock_PS_Rte_NvmBlock_CustDiag_DidDE01: start-on-event=EraseBlock, operation=PS_Rte_NvmBlock_CustDiag_DidDE01.EraseBlock
        OpEventSetBlockProtection_SetBlockProtection_PAdmin_Rte_NvmBlock_CustDiag_DidDE04: start-on-event=SetBlockProtection, operation=PAdmin_Rte_NvmBlock_CustDiag_DidDE04.SetBlockProtection
        OpEventSetBlockProtection_SetBlockProtection_PAdmin_Rte_NvmBlock_CustDiag_Did3003: start-on-event=SetBlockProtection, operation=PAdmin_Rte_NvmBlock_CustDiag_Did3003.SetBlockProtection
        OpEventSetBlockProtection_SetBlockProtection_PAdmin_Rte_NvmBlock_CustDiag_DidEE01: start-on-event=SetBlockProtection, operation=PAdmin_Rte_NvmBlock_CustDiag_DidEE01.SetBlockProtection
        OpEventSetBlockProtection_SetBlockProtection_PAdmin_Rte_NvmBlock_CustDiag_DidF111: start-on-event=SetBlockProtection, operation=PAdmin_Rte_NvmBlock_CustDiag_DidF111.SetBlockProtection
        OpEventSetBlockProtection_SetBlockProtection_PAdmin_Rte_NvmBlock_CustDiag_DidF113: start-on-event=SetBlockProtection, operation=PAdmin_Rte_NvmBlock_CustDiag_DidF113.SetBlockProtection
        OpEventSetBlockProtection_SetBlockProtection_PAdmin_Rte_NvmBlock_CustDiag_DidEE02: start-on-event=SetBlockProtection, operation=PAdmin_Rte_NvmBlock_CustDiag_DidEE02.SetBlockProtection
        OpEventSetBlockProtection_SetBlockProtection_PAdmin_Rte_NvmBlock_CustDiag_DidDE02: start-on-event=SetBlockProtection, operation=PAdmin_Rte_NvmBlock_CustDiag_DidDE02.SetBlockProtection
        OpEventSetBlockProtection_SetBlockProtection_PAdmin_Rte_NvmBlock_CustDiag_DidDE03: start-on-event=SetBlockProtection, operation=PAdmin_Rte_NvmBlock_CustDiag_DidDE03.SetBlockProtection
        OpEventSetBlockProtection_SetBlockProtection_PAdmin_Rte_NvmBlock_CustDiag_DidDE00: start-on-event=SetBlockProtection, operation=PAdmin_Rte_NvmBlock_CustDiag_DidDE00.SetBlockProtection
        OpEventSetBlockProtection_SetBlockProtection_PAdmin_Rte_NvmBlock_CustDiag_DidDE01: start-on-event=SetBlockProtection, operation=PAdmin_Rte_NvmBlock_CustDiag_DidDE01.SetBlockProtection
        OpEventRestoreBlockDefaults_RestoreBlockDefaults_PS_Rte_NvmBlock_CustDiag_DidDE01: start-on-event=RestoreBlockDefaults, operation=PS_Rte_NvmBlock_CustDiag_DidDE01.RestoreBlockDefaults
        OpEventRestoreBlockDefaults_RestoreBlockDefaults_PS_Rte_NvmBlock_CustDiag_Did3003: start-on-event=RestoreBlockDefaults, operation=PS_Rte_NvmBlock_CustDiag_Did3003.RestoreBlockDefaults
        OpEventRestoreBlockDefaults_RestoreBlockDefaults_PS_Rte_NvmBlock_CustDiag_DidF113: start-on-event=RestoreBlockDefaults, operation=PS_Rte_NvmBlock_CustDiag_DidF113.RestoreBlockDefaults
        OpEventRestoreBlockDefaults_RestoreBlockDefaults_PS_Rte_NvmBlock_CustDiag_DidDE03: start-on-event=RestoreBlockDefaults, operation=PS_Rte_NvmBlock_CustDiag_DidDE03.RestoreBlockDefaults
        OpEventRestoreBlockDefaults_RestoreBlockDefaults_PS_Rte_NvmBlock_CustDiag_DidEE02: start-on-event=RestoreBlockDefaults, operation=PS_Rte_NvmBlock_CustDiag_DidEE02.RestoreBlockDefaults
        OpEventRestoreBlockDefaults_RestoreBlockDefaults_PS_Rte_NvmBlock_CustDiag_DidDE02: start-on-event=RestoreBlockDefaults, operation=PS_Rte_NvmBlock_CustDiag_DidDE02.RestoreBlockDefaults
        OpEventRestoreBlockDefaults_RestoreBlockDefaults_PS_Rte_NvmBlock_CustDiag_DidEE01: start-on-event=RestoreBlockDefaults, operation=PS_Rte_NvmBlock_CustDiag_DidEE01.RestoreBlockDefaults
        OpEventRestoreBlockDefaults_RestoreBlockDefaults_PS_Rte_NvmBlock_CustDiag_DidDE00: start-on-event=RestoreBlockDefaults, operation=PS_Rte_NvmBlock_CustDiag_DidDE00.RestoreBlockDefaults
        OpEventRestoreBlockDefaults_RestoreBlockDefaults_PS_Rte_NvmBlock_CustDiag_DidF111: start-on-event=RestoreBlockDefaults, operation=PS_Rte_NvmBlock_CustDiag_DidF111.RestoreBlockDefaults
        OpEventRestoreBlockDefaults_RestoreBlockDefaults_PS_Rte_NvmBlock_CustDiag_DidDE04: start-on-event=RestoreBlockDefaults, operation=PS_Rte_NvmBlock_CustDiag_DidDE04.RestoreBlockDefaults
        OpEventGetErrorStatus_GetErrorStatus_PS_Rte_NvmBlock_FordVehSpdArbn_FordVehTireCircum: start-on-event=GetErrorStatus, operation=PS_Rte_NvmBlock_FordVehSpdArbn_FordVehTireCircum.GetErrorStatus
        OpEventGetErrorStatus_GetErrorStatus_PS_Rte_NvmBlock_FordHwAgArbn_PrevIgnCycVal: start-on-event=GetErrorStatus, operation=PS_Rte_NvmBlock_FordHwAgArbn_PrevIgnCycVal.GetErrorStatus
        OpEventGetErrorStatus_GetErrorStatus_PS_Rte_NvmBlock_FordHwAgArbn_NonAbsOffsVldFlg: start-on-event=GetErrorStatus, operation=PS_Rte_NvmBlock_FordHwAgArbn_NonAbsOffsVldFlg.GetErrorStatus
        OpEventGetErrorStatus_GetErrorStatus_PS_Rte_NvmBlock_FordHwAgArbn_NonAbsOffs: start-on-event=GetErrorStatus, operation=PS_Rte_NvmBlock_FordHwAgArbn_NonAbsOffs.GetErrorStatus
        OpEventSetRamBlockStatus_SetRamBlockStatus_PS_Rte_NvmBlock_FordVehSpdArbn_FordVehTireCircum: start-on-event=SetRamBlockStatus, operation=PS_Rte_NvmBlock_FordVehSpdArbn_FordVehTireCircum.SetRamBlockStatus
        OpEventSetRamBlockStatus_SetRamBlockStatus_PS_Rte_NvmBlock_FordHwAgArbn_PrevIgnCycVal: start-on-event=SetRamBlockStatus, operation=PS_Rte_NvmBlock_FordHwAgArbn_PrevIgnCycVal.SetRamBlockStatus
        OpEventSetRamBlockStatus_SetRamBlockStatus_PS_Rte_NvmBlock_FordHwAgArbn_NonAbsOffsVldFlg: start-on-event=SetRamBlockStatus, operation=PS_Rte_NvmBlock_FordHwAgArbn_NonAbsOffsVldFlg.SetRamBlockStatus
        OpEventSetRamBlockStatus_SetRamBlockStatus_PS_Rte_NvmBlock_FordHwAgArbn_NonAbsOffs: start-on-event=SetRamBlockStatus, operation=PS_Rte_NvmBlock_FordHwAgArbn_NonAbsOffs.SetRamBlockStatus
        OpEventReadBlock_ReadBlock_PS_Rte_NvmBlock_FordVehSpdArbn_FordVehTireCircum: start-on-event=ReadBlock, operation=PS_Rte_NvmBlock_FordVehSpdArbn_FordVehTireCircum.ReadBlock
        OpEventReadBlock_ReadBlock_PS_Rte_NvmBlock_FordHwAgArbn_PrevIgnCycVal: start-on-event=ReadBlock, operation=PS_Rte_NvmBlock_FordHwAgArbn_PrevIgnCycVal.ReadBlock
        OpEventReadBlock_ReadBlock_PS_Rte_NvmBlock_FordHwAgArbn_NonAbsOffsVldFlg: start-on-event=ReadBlock, operation=PS_Rte_NvmBlock_FordHwAgArbn_NonAbsOffsVldFlg.ReadBlock
        OpEventReadBlock_ReadBlock_PS_Rte_NvmBlock_FordHwAgArbn_NonAbsOffs: start-on-event=ReadBlock, operation=PS_Rte_NvmBlock_FordHwAgArbn_NonAbsOffs.ReadBlock
        OpEventWriteBlock_WriteBlock_PS_Rte_NvmBlock_FordVehSpdArbn_FordVehTireCircum: start-on-event=WriteBlock, operation=PS_Rte_NvmBlock_FordVehSpdArbn_FordVehTireCircum.WriteBlock
        OpEventWriteBlock_WriteBlock_PS_Rte_NvmBlock_FordHwAgArbn_PrevIgnCycVal: start-on-event=WriteBlock, operation=PS_Rte_NvmBlock_FordHwAgArbn_PrevIgnCycVal.WriteBlock
        OpEventWriteBlock_WriteBlock_PS_Rte_NvmBlock_FordHwAgArbn_NonAbsOffsVldFlg: start-on-event=WriteBlock, operation=PS_Rte_NvmBlock_FordHwAgArbn_NonAbsOffsVldFlg.WriteBlock
        OpEventWriteBlock_WriteBlock_PS_Rte_NvmBlock_FordHwAgArbn_NonAbsOffs: start-on-event=WriteBlock, operation=PS_Rte_NvmBlock_FordHwAgArbn_NonAbsOffs.WriteBlock
        OpEventInvalidateNvBlock_InvalidateNvBlock_PS_Rte_NvmBlock_FordVehSpdArbn_FordVehTireCircum: start-on-event=InvalidateNvBlock, operation=PS_Rte_NvmBlock_FordVehSpdArbn_FordVehTireCircum.InvalidateNvBlock
        OpEventInvalidateNvBlock_InvalidateNvBlock_PS_Rte_NvmBlock_FordHwAgArbn_PrevIgnCycVal: start-on-event=InvalidateNvBlock, operation=PS_Rte_NvmBlock_FordHwAgArbn_PrevIgnCycVal.InvalidateNvBlock
        OpEventInvalidateNvBlock_InvalidateNvBlock_PS_Rte_NvmBlock_FordHwAgArbn_NonAbsOffsVldFlg: start-on-event=InvalidateNvBlock, operation=PS_Rte_NvmBlock_FordHwAgArbn_NonAbsOffsVldFlg.InvalidateNvBlock
        OpEventInvalidateNvBlock_InvalidateNvBlock_PS_Rte_NvmBlock_FordHwAgArbn_NonAbsOffs: start-on-event=InvalidateNvBlock, operation=PS_Rte_NvmBlock_FordHwAgArbn_NonAbsOffs.InvalidateNvBlock
        OpEventEraseBlock_EraseBlock_PS_Rte_NvmBlock_FordVehSpdArbn_FordVehTireCircum: start-on-event=EraseBlock, operation=PS_Rte_NvmBlock_FordVehSpdArbn_FordVehTireCircum.EraseBlock
        OpEventEraseBlock_EraseBlock_PS_Rte_NvmBlock_FordHwAgArbn_PrevIgnCycVal: start-on-event=EraseBlock, operation=PS_Rte_NvmBlock_FordHwAgArbn_PrevIgnCycVal.EraseBlock
        OpEventEraseBlock_EraseBlock_PS_Rte_NvmBlock_FordHwAgArbn_NonAbsOffsVldFlg: start-on-event=EraseBlock, operation=PS_Rte_NvmBlock_FordHwAgArbn_NonAbsOffsVldFlg.EraseBlock
        OpEventEraseBlock_EraseBlock_PS_Rte_NvmBlock_FordHwAgArbn_NonAbsOffs: start-on-event=EraseBlock, operation=PS_Rte_NvmBlock_FordHwAgArbn_NonAbsOffs.EraseBlock
        OpEventSetBlockProtection_SetBlockProtection_PAdmin_Rte_NvmBlock_FordVehSpdArbn_FordVehTireCircum: start-on-event=SetBlockProtection, operation=PAdmin_Rte_NvmBlock_FordVehSpdArbn_FordVehTireCircum.SetBlockProtection
        OpEventSetBlockProtection_SetBlockProtection_PAdmin_Rte_NvmBlock_FordHwAgArbn_PrevIgnCycVal: start-on-event=SetBlockProtection, operation=PAdmin_Rte_NvmBlock_FordHwAgArbn_PrevIgnCycVal.SetBlockProtection
        OpEventSetBlockProtection_SetBlockProtection_PAdmin_Rte_NvmBlock_FordHwAgArbn_NonAbsOffsVldFlg: start-on-event=SetBlockProtection, operation=PAdmin_Rte_NvmBlock_FordHwAgArbn_NonAbsOffsVldFlg.SetBlockProtection
        OpEventSetBlockProtection_SetBlockProtection_PAdmin_Rte_NvmBlock_FordHwAgArbn_NonAbsOffs: start-on-event=SetBlockProtection, operation=PAdmin_Rte_NvmBlock_FordHwAgArbn_NonAbsOffs.SetBlockProtection
        OpEventRestoreBlockDefaults_RestoreBlockDefaults_PS_Rte_NvmBlock_FordHwAgArbn_PrevIgnCycVal: start-on-event=RestoreBlockDefaults, operation=PS_Rte_NvmBlock_FordHwAgArbn_PrevIgnCycVal.RestoreBlockDefaults
        OpEventGetErrorStatus_GetErrorStatus_PS_Rte_NvmBlock_CustDiag_DidF15F: start-on-event=GetErrorStatus, operation=PS_Rte_NvmBlock_CustDiag_DidF15F.GetErrorStatus
        OpEventGetErrorStatus_GetErrorStatus_PS_Rte_NvmBlock_CustDiag_DidEE88: start-on-event=GetErrorStatus, operation=PS_Rte_NvmBlock_CustDiag_DidEE88.GetErrorStatus
        OpEventGetErrorStatus_GetErrorStatus_PS_Rte_NvmBlock_CustDiag_DidF110: start-on-event=GetErrorStatus, operation=PS_Rte_NvmBlock_CustDiag_DidF110.GetErrorStatus
        OpEventGetErrorStatus_GetErrorStatus_PS_Rte_NvmBlock_CustDiag_DidEED0: start-on-event=GetErrorStatus, operation=PS_Rte_NvmBlock_CustDiag_DidEED0.GetErrorStatus
        OpEventGetErrorStatus_GetErrorStatus_PS_Rte_NvmBlock_CustDiag_DidEE83: start-on-event=GetErrorStatus, operation=PS_Rte_NvmBlock_CustDiag_DidEE83.GetErrorStatus
        OpEventGetErrorStatus_GetErrorStatus_PS_Rte_NvmBlock_CustDiag_Did301A: start-on-event=GetErrorStatus, operation=PS_Rte_NvmBlock_CustDiag_Did301A.GetErrorStatus
        OpEventGetErrorStatus_GetErrorStatus_PS_Rte_NvmBlock_CustDiag_DidF162: start-on-event=GetErrorStatus, operation=PS_Rte_NvmBlock_CustDiag_DidF162.GetErrorStatus
        OpEventGetErrorStatus_GetErrorStatus_PS_Rte_NvmBlock_CustDiag_DidEE40: start-on-event=GetErrorStatus, operation=PS_Rte_NvmBlock_CustDiag_DidEE40.GetErrorStatus
        OpEventGetErrorStatus_GetErrorStatus_PS_Rte_NvmBlock_CustDiag_DidEE81: start-on-event=GetErrorStatus, operation=PS_Rte_NvmBlock_CustDiag_DidEE81.GetErrorStatus
        OpEventGetErrorStatus_GetErrorStatus_PS_Rte_NvmBlock_CustDiag_DidEE82: start-on-event=GetErrorStatus, operation=PS_Rte_NvmBlock_CustDiag_DidEE82.GetErrorStatus
        OpEventGetErrorStatus_GetErrorStatus_PS_Rte_NvmBlock_CustDiag_DidEE41: start-on-event=GetErrorStatus, operation=PS_Rte_NvmBlock_CustDiag_DidEE41.GetErrorStatus
        OpEventGetErrorStatus_GetErrorStatus_PS_Rte_NvmBlock_CustDiag_DidEE84: start-on-event=GetErrorStatus, operation=PS_Rte_NvmBlock_CustDiag_DidEE84.GetErrorStatus
        OpEventGetErrorStatus_GetErrorStatus_PS_Rte_NvmBlock_CustDiag_DidF18A: start-on-event=GetErrorStatus, operation=PS_Rte_NvmBlock_CustDiag_DidF18A.GetErrorStatus
        OpEventGetErrorStatus_GetErrorStatus_PS_Rte_NvmBlock_CustDiag_DidEE00: start-on-event=GetErrorStatus, operation=PS_Rte_NvmBlock_CustDiag_DidEE00.GetErrorStatus
        OpEventGetErrorStatus_GetErrorStatus_PS_Rte_NvmBlock_CustDiag_DidF166: start-on-event=GetErrorStatus, operation=PS_Rte_NvmBlock_CustDiag_DidF166.GetErrorStatus
        OpEventGetErrorStatus_GetErrorStatus_PS_Rte_NvmBlock_CustDiag_Did205A: start-on-event=GetErrorStatus, operation=PS_Rte_NvmBlock_CustDiag_Did205A.GetErrorStatus
        OpEventGetErrorStatus_GetErrorStatus_PS_Rte_NvmBlock_CustDiag_DidEE87: start-on-event=GetErrorStatus, operation=PS_Rte_NvmBlock_CustDiag_DidEE87.GetErrorStatus
        OpEventGetErrorStatus_GetErrorStatus_PS_Rte_NvmBlock_CustDiag_DidDE05: start-on-event=GetErrorStatus, operation=PS_Rte_NvmBlock_CustDiag_DidDE05.GetErrorStatus
        OpEventGetErrorStatus_GetErrorStatus_PS_Rte_NvmBlock_CustDiag_DidEE86: start-on-event=GetErrorStatus, operation=PS_Rte_NvmBlock_CustDiag_DidEE86.GetErrorStatus
        OpEventGetErrorStatus_GetErrorStatus_PS_Rte_NvmBlock_CustDiag_DidF163: start-on-event=GetErrorStatus, operation=PS_Rte_NvmBlock_CustDiag_DidF163.GetErrorStatus
        OpEventGetErrorStatus_GetErrorStatus_PS_Rte_NvmBlock_CustDiag_DidF18C: start-on-event=GetErrorStatus, operation=PS_Rte_NvmBlock_CustDiag_DidF18C.GetErrorStatus
        OpEventGetErrorStatus_GetErrorStatus_PS_Rte_NvmBlock_CustDiag_Did205B: start-on-event=GetErrorStatus, operation=PS_Rte_NvmBlock_CustDiag_Did205B.GetErrorStatus
        OpEventGetErrorStatus_GetErrorStatus_PS_Rte_NvmBlock_CustDiag_DidEE85: start-on-event=GetErrorStatus, operation=PS_Rte_NvmBlock_CustDiag_DidEE85.GetErrorStatus
        OpEventSetRamBlockStatus_SetRamBlockStatus_PS_Rte_NvmBlock_CustDiag_DidF15F: start-on-event=SetRamBlockStatus, operation=PS_Rte_NvmBlock_CustDiag_DidF15F.SetRamBlockStatus
        OpEventSetRamBlockStatus_SetRamBlockStatus_PS_Rte_NvmBlock_CustDiag_DidEE88: start-on-event=SetRamBlockStatus, operation=PS_Rte_NvmBlock_CustDiag_DidEE88.SetRamBlockStatus
        OpEventSetRamBlockStatus_SetRamBlockStatus_PS_Rte_NvmBlock_CustDiag_DidF110: start-on-event=SetRamBlockStatus, operation=PS_Rte_NvmBlock_CustDiag_DidF110.SetRamBlockStatus
        OpEventSetRamBlockStatus_SetRamBlockStatus_PS_Rte_NvmBlock_CustDiag_DidEED0: start-on-event=SetRamBlockStatus, operation=PS_Rte_NvmBlock_CustDiag_DidEED0.SetRamBlockStatus
        OpEventSetRamBlockStatus_SetRamBlockStatus_PS_Rte_NvmBlock_CustDiag_DidEE83: start-on-event=SetRamBlockStatus, operation=PS_Rte_NvmBlock_CustDiag_DidEE83.SetRamBlockStatus
        OpEventSetRamBlockStatus_SetRamBlockStatus_PS_Rte_NvmBlock_CustDiag_Did301A: start-on-event=SetRamBlockStatus, operation=PS_Rte_NvmBlock_CustDiag_Did301A.SetRamBlockStatus
        OpEventSetRamBlockStatus_SetRamBlockStatus_PS_Rte_NvmBlock_CustDiag_DidF162: start-on-event=SetRamBlockStatus, operation=PS_Rte_NvmBlock_CustDiag_DidF162.SetRamBlockStatus
        OpEventSetRamBlockStatus_SetRamBlockStatus_PS_Rte_NvmBlock_CustDiag_DidEE40: start-on-event=SetRamBlockStatus, operation=PS_Rte_NvmBlock_CustDiag_DidEE40.SetRamBlockStatus
        OpEventSetRamBlockStatus_SetRamBlockStatus_PS_Rte_NvmBlock_CustDiag_DidEE81: start-on-event=SetRamBlockStatus, operation=PS_Rte_NvmBlock_CustDiag_DidEE81.SetRamBlockStatus
        OpEventSetRamBlockStatus_SetRamBlockStatus_PS_Rte_NvmBlock_CustDiag_DidEE82: start-on-event=SetRamBlockStatus, operation=PS_Rte_NvmBlock_CustDiag_DidEE82.SetRamBlockStatus
        OpEventSetRamBlockStatus_SetRamBlockStatus_PS_Rte_NvmBlock_CustDiag_DidEE41: start-on-event=SetRamBlockStatus, operation=PS_Rte_NvmBlock_CustDiag_DidEE41.SetRamBlockStatus
        OpEventSetRamBlockStatus_SetRamBlockStatus_PS_Rte_NvmBlock_CustDiag_DidEE84: start-on-event=SetRamBlockStatus, operation=PS_Rte_NvmBlock_CustDiag_DidEE84.SetRamBlockStatus
        OpEventSetRamBlockStatus_SetRamBlockStatus_PS_Rte_NvmBlock_CustDiag_DidF18A: start-on-event=SetRamBlockStatus, operation=PS_Rte_NvmBlock_CustDiag_DidF18A.SetRamBlockStatus
        OpEventSetRamBlockStatus_SetRamBlockStatus_PS_Rte_NvmBlock_CustDiag_DidEE00: start-on-event=SetRamBlockStatus, operation=PS_Rte_NvmBlock_CustDiag_DidEE00.SetRamBlockStatus
        OpEventSetRamBlockStatus_SetRamBlockStatus_PS_Rte_NvmBlock_CustDiag_DidF166: start-on-event=SetRamBlockStatus, operation=PS_Rte_NvmBlock_CustDiag_DidF166.SetRamBlockStatus
        OpEventSetRamBlockStatus_SetRamBlockStatus_PS_Rte_NvmBlock_CustDiag_Did205A: start-on-event=SetRamBlockStatus, operation=PS_Rte_NvmBlock_CustDiag_Did205A.SetRamBlockStatus
        OpEventSetRamBlockStatus_SetRamBlockStatus_PS_Rte_NvmBlock_CustDiag_DidEE87: start-on-event=SetRamBlockStatus, operation=PS_Rte_NvmBlock_CustDiag_DidEE87.SetRamBlockStatus
        OpEventSetRamBlockStatus_SetRamBlockStatus_PS_Rte_NvmBlock_CustDiag_DidDE05: start-on-event=SetRamBlockStatus, operation=PS_Rte_NvmBlock_CustDiag_DidDE05.SetRamBlockStatus
        OpEventSetRamBlockStatus_SetRamBlockStatus_PS_Rte_NvmBlock_CustDiag_DidEE86: start-on-event=SetRamBlockStatus, operation=PS_Rte_NvmBlock_CustDiag_DidEE86.SetRamBlockStatus
        OpEventSetRamBlockStatus_SetRamBlockStatus_PS_Rte_NvmBlock_CustDiag_DidF163: start-on-event=SetRamBlockStatus, operation=PS_Rte_NvmBlock_CustDiag_DidF163.SetRamBlockStatus
        OpEventSetRamBlockStatus_SetRamBlockStatus_PS_Rte_NvmBlock_CustDiag_DidF18C: start-on-event=SetRamBlockStatus, operation=PS_Rte_NvmBlock_CustDiag_DidF18C.SetRamBlockStatus
        OpEventSetRamBlockStatus_SetRamBlockStatus_PS_Rte_NvmBlock_CustDiag_Did205B: start-on-event=SetRamBlockStatus, operation=PS_Rte_NvmBlock_CustDiag_Did205B.SetRamBlockStatus
        OpEventSetRamBlockStatus_SetRamBlockStatus_PS_Rte_NvmBlock_CustDiag_DidEE85: start-on-event=SetRamBlockStatus, operation=PS_Rte_NvmBlock_CustDiag_DidEE85.SetRamBlockStatus
        OpEventReadBlock_ReadBlock_PS_Rte_NvmBlock_CustDiag_DidF15F: start-on-event=ReadBlock, operation=PS_Rte_NvmBlock_CustDiag_DidF15F.ReadBlock
        OpEventReadBlock_ReadBlock_PS_Rte_NvmBlock_CustDiag_DidEE88: start-on-event=ReadBlock, operation=PS_Rte_NvmBlock_CustDiag_DidEE88.ReadBlock
        OpEventReadBlock_ReadBlock_PS_Rte_NvmBlock_CustDiag_DidF110: start-on-event=ReadBlock, operation=PS_Rte_NvmBlock_CustDiag_DidF110.ReadBlock
        OpEventReadBlock_ReadBlock_PS_Rte_NvmBlock_CustDiag_DidEED0: start-on-event=ReadBlock, operation=PS_Rte_NvmBlock_CustDiag_DidEED0.ReadBlock
        OpEventReadBlock_ReadBlock_PS_Rte_NvmBlock_CustDiag_DidEE83: start-on-event=ReadBlock, operation=PS_Rte_NvmBlock_CustDiag_DidEE83.ReadBlock
        OpEventReadBlock_ReadBlock_PS_Rte_NvmBlock_CustDiag_Did301A: start-on-event=ReadBlock, operation=PS_Rte_NvmBlock_CustDiag_Did301A.ReadBlock
        OpEventReadBlock_ReadBlock_PS_Rte_NvmBlock_CustDiag_DidF162: start-on-event=ReadBlock, operation=PS_Rte_NvmBlock_CustDiag_DidF162.ReadBlock
        OpEventReadBlock_ReadBlock_PS_Rte_NvmBlock_CustDiag_DidEE40: start-on-event=ReadBlock, operation=PS_Rte_NvmBlock_CustDiag_DidEE40.ReadBlock
        OpEventReadBlock_ReadBlock_PS_Rte_NvmBlock_CustDiag_DidEE81: start-on-event=ReadBlock, operation=PS_Rte_NvmBlock_CustDiag_DidEE81.ReadBlock
        OpEventReadBlock_ReadBlock_PS_Rte_NvmBlock_CustDiag_DidEE82: start-on-event=ReadBlock, operation=PS_Rte_NvmBlock_CustDiag_DidEE82.ReadBlock
        OpEventReadBlock_ReadBlock_PS_Rte_NvmBlock_CustDiag_DidEE41: start-on-event=ReadBlock, operation=PS_Rte_NvmBlock_CustDiag_DidEE41.ReadBlock
        OpEventReadBlock_ReadBlock_PS_Rte_NvmBlock_CustDiag_DidEE84: start-on-event=ReadBlock, operation=PS_Rte_NvmBlock_CustDiag_DidEE84.ReadBlock
        OpEventReadBlock_ReadBlock_PS_Rte_NvmBlock_CustDiag_DidF18A: start-on-event=ReadBlock, operation=PS_Rte_NvmBlock_CustDiag_DidF18A.ReadBlock
        OpEventReadBlock_ReadBlock_PS_Rte_NvmBlock_CustDiag_DidEE00: start-on-event=ReadBlock, operation=PS_Rte_NvmBlock_CustDiag_DidEE00.ReadBlock
        OpEventReadBlock_ReadBlock_PS_Rte_NvmBlock_CustDiag_DidF166: start-on-event=ReadBlock, operation=PS_Rte_NvmBlock_CustDiag_DidF166.ReadBlock
        OpEventReadBlock_ReadBlock_PS_Rte_NvmBlock_CustDiag_Did205A: start-on-event=ReadBlock, operation=PS_Rte_NvmBlock_CustDiag_Did205A.ReadBlock
        OpEventReadBlock_ReadBlock_PS_Rte_NvmBlock_CustDiag_DidEE87: start-on-event=ReadBlock, operation=PS_Rte_NvmBlock_CustDiag_DidEE87.ReadBlock
        OpEventReadBlock_ReadBlock_PS_Rte_NvmBlock_CustDiag_DidDE05: start-on-event=ReadBlock, operation=PS_Rte_NvmBlock_CustDiag_DidDE05.ReadBlock
        OpEventReadBlock_ReadBlock_PS_Rte_NvmBlock_CustDiag_DidEE86: start-on-event=ReadBlock, operation=PS_Rte_NvmBlock_CustDiag_DidEE86.ReadBlock
        OpEventReadBlock_ReadBlock_PS_Rte_NvmBlock_CustDiag_DidF163: start-on-event=ReadBlock, operation=PS_Rte_NvmBlock_CustDiag_DidF163.ReadBlock
        OpEventReadBlock_ReadBlock_PS_Rte_NvmBlock_CustDiag_DidF18C: start-on-event=ReadBlock, operation=PS_Rte_NvmBlock_CustDiag_DidF18C.ReadBlock
        OpEventReadBlock_ReadBlock_PS_Rte_NvmBlock_CustDiag_Did205B: start-on-event=ReadBlock, operation=PS_Rte_NvmBlock_CustDiag_Did205B.ReadBlock
        OpEventReadBlock_ReadBlock_PS_Rte_NvmBlock_CustDiag_DidEE85: start-on-event=ReadBlock, operation=PS_Rte_NvmBlock_CustDiag_DidEE85.ReadBlock
        OpEventWriteBlock_WriteBlock_PS_Rte_NvmBlock_CustDiag_DidF15F: start-on-event=WriteBlock, operation=PS_Rte_NvmBlock_CustDiag_DidF15F.WriteBlock
        OpEventWriteBlock_WriteBlock_PS_Rte_NvmBlock_CustDiag_DidEE88: start-on-event=WriteBlock, operation=PS_Rte_NvmBlock_CustDiag_DidEE88.WriteBlock
        OpEventWriteBlock_WriteBlock_PS_Rte_NvmBlock_CustDiag_DidF110: start-on-event=WriteBlock, operation=PS_Rte_NvmBlock_CustDiag_DidF110.WriteBlock
        OpEventWriteBlock_WriteBlock_PS_Rte_NvmBlock_CustDiag_DidEED0: start-on-event=WriteBlock, operation=PS_Rte_NvmBlock_CustDiag_DidEED0.WriteBlock
        OpEventWriteBlock_WriteBlock_PS_Rte_NvmBlock_CustDiag_DidEE83: start-on-event=WriteBlock, operation=PS_Rte_NvmBlock_CustDiag_DidEE83.WriteBlock
        OpEventWriteBlock_WriteBlock_PS_Rte_NvmBlock_CustDiag_Did301A: start-on-event=WriteBlock, operation=PS_Rte_NvmBlock_CustDiag_Did301A.WriteBlock
        OpEventWriteBlock_WriteBlock_PS_Rte_NvmBlock_CustDiag_DidF162: start-on-event=WriteBlock, operation=PS_Rte_NvmBlock_CustDiag_DidF162.WriteBlock
        OpEventWriteBlock_WriteBlock_PS_Rte_NvmBlock_CustDiag_DidEE40: start-on-event=WriteBlock, operation=PS_Rte_NvmBlock_CustDiag_DidEE40.WriteBlock
        OpEventWriteBlock_WriteBlock_PS_Rte_NvmBlock_CustDiag_DidEE81: start-on-event=WriteBlock, operation=PS_Rte_NvmBlock_CustDiag_DidEE81.WriteBlock
        OpEventWriteBlock_WriteBlock_PS_Rte_NvmBlock_CustDiag_DidEE82: start-on-event=WriteBlock, operation=PS_Rte_NvmBlock_CustDiag_DidEE82.WriteBlock
        OpEventWriteBlock_WriteBlock_PS_Rte_NvmBlock_CustDiag_DidEE41: start-on-event=WriteBlock, operation=PS_Rte_NvmBlock_CustDiag_DidEE41.WriteBlock
        OpEventWriteBlock_WriteBlock_PS_Rte_NvmBlock_CustDiag_DidEE84: start-on-event=WriteBlock, operation=PS_Rte_NvmBlock_CustDiag_DidEE84.WriteBlock
        OpEventWriteBlock_WriteBlock_PS_Rte_NvmBlock_CustDiag_DidF18A: start-on-event=WriteBlock, operation=PS_Rte_NvmBlock_CustDiag_DidF18A.WriteBlock
        OpEventWriteBlock_WriteBlock_PS_Rte_NvmBlock_CustDiag_DidEE00: start-on-event=WriteBlock, operation=PS_Rte_NvmBlock_CustDiag_DidEE00.WriteBlock
        OpEventWriteBlock_WriteBlock_PS_Rte_NvmBlock_CustDiag_DidF166: start-on-event=WriteBlock, operation=PS_Rte_NvmBlock_CustDiag_DidF166.WriteBlock
        OpEventWriteBlock_WriteBlock_PS_Rte_NvmBlock_CustDiag_Did205A: start-on-event=WriteBlock, operation=PS_Rte_NvmBlock_CustDiag_Did205A.WriteBlock
        OpEventWriteBlock_WriteBlock_PS_Rte_NvmBlock_CustDiag_DidEE87: start-on-event=WriteBlock, operation=PS_Rte_NvmBlock_CustDiag_DidEE87.WriteBlock
        OpEventWriteBlock_WriteBlock_PS_Rte_NvmBlock_CustDiag_DidDE05: start-on-event=WriteBlock, operation=PS_Rte_NvmBlock_CustDiag_DidDE05.WriteBlock
        OpEventWriteBlock_WriteBlock_PS_Rte_NvmBlock_CustDiag_DidEE86: start-on-event=WriteBlock, operation=PS_Rte_NvmBlock_CustDiag_DidEE86.WriteBlock
        OpEventWriteBlock_WriteBlock_PS_Rte_NvmBlock_CustDiag_DidF163: start-on-event=WriteBlock, operation=PS_Rte_NvmBlock_CustDiag_DidF163.WriteBlock
        OpEventWriteBlock_WriteBlock_PS_Rte_NvmBlock_CustDiag_DidF18C: start-on-event=WriteBlock, operation=PS_Rte_NvmBlock_CustDiag_DidF18C.WriteBlock
        OpEventWriteBlock_WriteBlock_PS_Rte_NvmBlock_CustDiag_Did205B: start-on-event=WriteBlock, operation=PS_Rte_NvmBlock_CustDiag_Did205B.WriteBlock
        OpEventWriteBlock_WriteBlock_PS_Rte_NvmBlock_CustDiag_DidEE85: start-on-event=WriteBlock, operation=PS_Rte_NvmBlock_CustDiag_DidEE85.WriteBlock
        OpEventInvalidateNvBlock_InvalidateNvBlock_PS_Rte_NvmBlock_CustDiag_DidF15F: start-on-event=InvalidateNvBlock, operation=PS_Rte_NvmBlock_CustDiag_DidF15F.InvalidateNvBlock
        OpEventInvalidateNvBlock_InvalidateNvBlock_PS_Rte_NvmBlock_CustDiag_DidEE88: start-on-event=InvalidateNvBlock, operation=PS_Rte_NvmBlock_CustDiag_DidEE88.InvalidateNvBlock
        OpEventInvalidateNvBlock_InvalidateNvBlock_PS_Rte_NvmBlock_CustDiag_DidF110: start-on-event=InvalidateNvBlock, operation=PS_Rte_NvmBlock_CustDiag_DidF110.InvalidateNvBlock
        OpEventInvalidateNvBlock_InvalidateNvBlock_PS_Rte_NvmBlock_CustDiag_DidEED0: start-on-event=InvalidateNvBlock, operation=PS_Rte_NvmBlock_CustDiag_DidEED0.InvalidateNvBlock
        OpEventInvalidateNvBlock_InvalidateNvBlock_PS_Rte_NvmBlock_CustDiag_DidEE83: start-on-event=InvalidateNvBlock, operation=PS_Rte_NvmBlock_CustDiag_DidEE83.InvalidateNvBlock
        OpEventInvalidateNvBlock_InvalidateNvBlock_PS_Rte_NvmBlock_CustDiag_Did301A: start-on-event=InvalidateNvBlock, operation=PS_Rte_NvmBlock_CustDiag_Did301A.InvalidateNvBlock
        OpEventInvalidateNvBlock_InvalidateNvBlock_PS_Rte_NvmBlock_CustDiag_DidF162: start-on-event=InvalidateNvBlock, operation=PS_Rte_NvmBlock_CustDiag_DidF162.InvalidateNvBlock
        OpEventInvalidateNvBlock_InvalidateNvBlock_PS_Rte_NvmBlock_CustDiag_DidEE40: start-on-event=InvalidateNvBlock, operation=PS_Rte_NvmBlock_CustDiag_DidEE40.InvalidateNvBlock
        OpEventInvalidateNvBlock_InvalidateNvBlock_PS_Rte_NvmBlock_CustDiag_DidEE81: start-on-event=InvalidateNvBlock, operation=PS_Rte_NvmBlock_CustDiag_DidEE81.InvalidateNvBlock
        OpEventInvalidateNvBlock_InvalidateNvBlock_PS_Rte_NvmBlock_CustDiag_DidEE82: start-on-event=InvalidateNvBlock, operation=PS_Rte_NvmBlock_CustDiag_DidEE82.InvalidateNvBlock
        OpEventInvalidateNvBlock_InvalidateNvBlock_PS_Rte_NvmBlock_CustDiag_DidEE41: start-on-event=InvalidateNvBlock, operation=PS_Rte_NvmBlock_CustDiag_DidEE41.InvalidateNvBlock
        OpEventInvalidateNvBlock_InvalidateNvBlock_PS_Rte_NvmBlock_CustDiag_DidEE84: start-on-event=InvalidateNvBlock, operation=PS_Rte_NvmBlock_CustDiag_DidEE84.InvalidateNvBlock
        OpEventInvalidateNvBlock_InvalidateNvBlock_PS_Rte_NvmBlock_CustDiag_DidF18A: start-on-event=InvalidateNvBlock, operation=PS_Rte_NvmBlock_CustDiag_DidF18A.InvalidateNvBlock
        OpEventInvalidateNvBlock_InvalidateNvBlock_PS_Rte_NvmBlock_CustDiag_DidEE00: start-on-event=InvalidateNvBlock, operation=PS_Rte_NvmBlock_CustDiag_DidEE00.InvalidateNvBlock
        OpEventInvalidateNvBlock_InvalidateNvBlock_PS_Rte_NvmBlock_CustDiag_DidF166: start-on-event=InvalidateNvBlock, operation=PS_Rte_NvmBlock_CustDiag_DidF166.InvalidateNvBlock
        OpEventInvalidateNvBlock_InvalidateNvBlock_PS_Rte_NvmBlock_CustDiag_Did205A: start-on-event=InvalidateNvBlock, operation=PS_Rte_NvmBlock_CustDiag_Did205A.InvalidateNvBlock
        OpEventInvalidateNvBlock_InvalidateNvBlock_PS_Rte_NvmBlock_CustDiag_DidEE87: start-on-event=InvalidateNvBlock, operation=PS_Rte_NvmBlock_CustDiag_DidEE87.InvalidateNvBlock
        OpEventInvalidateNvBlock_InvalidateNvBlock_PS_Rte_NvmBlock_CustDiag_DidDE05: start-on-event=InvalidateNvBlock, operation=PS_Rte_NvmBlock_CustDiag_DidDE05.InvalidateNvBlock
        OpEventInvalidateNvBlock_InvalidateNvBlock_PS_Rte_NvmBlock_CustDiag_DidEE86: start-on-event=InvalidateNvBlock, operation=PS_Rte_NvmBlock_CustDiag_DidEE86.InvalidateNvBlock
        OpEventInvalidateNvBlock_InvalidateNvBlock_PS_Rte_NvmBlock_CustDiag_DidF163: start-on-event=InvalidateNvBlock, operation=PS_Rte_NvmBlock_CustDiag_DidF163.InvalidateNvBlock
        OpEventInvalidateNvBlock_InvalidateNvBlock_PS_Rte_NvmBlock_CustDiag_DidF18C: start-on-event=InvalidateNvBlock, operation=PS_Rte_NvmBlock_CustDiag_DidF18C.InvalidateNvBlock
        OpEventInvalidateNvBlock_InvalidateNvBlock_PS_Rte_NvmBlock_CustDiag_Did205B: start-on-event=InvalidateNvBlock, operation=PS_Rte_NvmBlock_CustDiag_Did205B.InvalidateNvBlock
        OpEventInvalidateNvBlock_InvalidateNvBlock_PS_Rte_NvmBlock_CustDiag_DidEE85: start-on-event=InvalidateNvBlock, operation=PS_Rte_NvmBlock_CustDiag_DidEE85.InvalidateNvBlock
        OpEventEraseBlock_EraseBlock_PS_Rte_NvmBlock_CustDiag_DidF15F: start-on-event=EraseBlock, operation=PS_Rte_NvmBlock_CustDiag_DidF15F.EraseBlock
        OpEventEraseBlock_EraseBlock_PS_Rte_NvmBlock_CustDiag_DidEE88: start-on-event=EraseBlock, operation=PS_Rte_NvmBlock_CustDiag_DidEE88.EraseBlock
        OpEventEraseBlock_EraseBlock_PS_Rte_NvmBlock_CustDiag_DidF110: start-on-event=EraseBlock, operation=PS_Rte_NvmBlock_CustDiag_DidF110.EraseBlock
        OpEventEraseBlock_EraseBlock_PS_Rte_NvmBlock_CustDiag_DidEED0: start-on-event=EraseBlock, operation=PS_Rte_NvmBlock_CustDiag_DidEED0.EraseBlock
        OpEventEraseBlock_EraseBlock_PS_Rte_NvmBlock_CustDiag_DidEE83: start-on-event=EraseBlock, operation=PS_Rte_NvmBlock_CustDiag_DidEE83.EraseBlock
        OpEventEraseBlock_EraseBlock_PS_Rte_NvmBlock_CustDiag_Did301A: start-on-event=EraseBlock, operation=PS_Rte_NvmBlock_CustDiag_Did301A.EraseBlock
        OpEventEraseBlock_EraseBlock_PS_Rte_NvmBlock_CustDiag_DidF162: start-on-event=EraseBlock, operation=PS_Rte_NvmBlock_CustDiag_DidF162.EraseBlock
        OpEventEraseBlock_EraseBlock_PS_Rte_NvmBlock_CustDiag_DidEE40: start-on-event=EraseBlock, operation=PS_Rte_NvmBlock_CustDiag_DidEE40.EraseBlock
        OpEventEraseBlock_EraseBlock_PS_Rte_NvmBlock_CustDiag_DidEE81: start-on-event=EraseBlock, operation=PS_Rte_NvmBlock_CustDiag_DidEE81.EraseBlock
        OpEventEraseBlock_EraseBlock_PS_Rte_NvmBlock_CustDiag_DidEE82: start-on-event=EraseBlock, operation=PS_Rte_NvmBlock_CustDiag_DidEE82.EraseBlock
        OpEventEraseBlock_EraseBlock_PS_Rte_NvmBlock_CustDiag_DidEE41: start-on-event=EraseBlock, operation=PS_Rte_NvmBlock_CustDiag_DidEE41.EraseBlock
        OpEventEraseBlock_EraseBlock_PS_Rte_NvmBlock_CustDiag_DidEE84: start-on-event=EraseBlock, operation=PS_Rte_NvmBlock_CustDiag_DidEE84.EraseBlock
        OpEventEraseBlock_EraseBlock_PS_Rte_NvmBlock_CustDiag_DidF18A: start-on-event=EraseBlock, operation=PS_Rte_NvmBlock_CustDiag_DidF18A.EraseBlock
        OpEventEraseBlock_EraseBlock_PS_Rte_NvmBlock_CustDiag_DidEE00: start-on-event=EraseBlock, operation=PS_Rte_NvmBlock_CustDiag_DidEE00.EraseBlock
        OpEventEraseBlock_EraseBlock_PS_Rte_NvmBlock_CustDiag_DidF166: start-on-event=EraseBlock, operation=PS_Rte_NvmBlock_CustDiag_DidF166.EraseBlock
        OpEventEraseBlock_EraseBlock_PS_Rte_NvmBlock_CustDiag_Did205A: start-on-event=EraseBlock, operation=PS_Rte_NvmBlock_CustDiag_Did205A.EraseBlock
        OpEventEraseBlock_EraseBlock_PS_Rte_NvmBlock_CustDiag_DidEE87: start-on-event=EraseBlock, operation=PS_Rte_NvmBlock_CustDiag_DidEE87.EraseBlock
        OpEventEraseBlock_EraseBlock_PS_Rte_NvmBlock_CustDiag_DidDE05: start-on-event=EraseBlock, operation=PS_Rte_NvmBlock_CustDiag_DidDE05.EraseBlock
        OpEventEraseBlock_EraseBlock_PS_Rte_NvmBlock_CustDiag_DidEE86: start-on-event=EraseBlock, operation=PS_Rte_NvmBlock_CustDiag_DidEE86.EraseBlock
        OpEventEraseBlock_EraseBlock_PS_Rte_NvmBlock_CustDiag_DidF163: start-on-event=EraseBlock, operation=PS_Rte_NvmBlock_CustDiag_DidF163.EraseBlock
        OpEventEraseBlock_EraseBlock_PS_Rte_NvmBlock_CustDiag_DidF18C: start-on-event=EraseBlock, operation=PS_Rte_NvmBlock_CustDiag_DidF18C.EraseBlock
        OpEventEraseBlock_EraseBlock_PS_Rte_NvmBlock_CustDiag_Did205B: start-on-event=EraseBlock, operation=PS_Rte_NvmBlock_CustDiag_Did205B.EraseBlock
        OpEventEraseBlock_EraseBlock_PS_Rte_NvmBlock_CustDiag_DidEE85: start-on-event=EraseBlock, operation=PS_Rte_NvmBlock_CustDiag_DidEE85.EraseBlock
        OpEventSetBlockProtection_SetBlockProtection_PAdmin_Rte_NvmBlock_CustDiag_DidF15F: start-on-event=SetBlockProtection, operation=PAdmin_Rte_NvmBlock_CustDiag_DidF15F.SetBlockProtection
        OpEventSetBlockProtection_SetBlockProtection_PAdmin_Rte_NvmBlock_CustDiag_DidEE88: start-on-event=SetBlockProtection, operation=PAdmin_Rte_NvmBlock_CustDiag_DidEE88.SetBlockProtection
        OpEventSetBlockProtection_SetBlockProtection_PAdmin_Rte_NvmBlock_CustDiag_DidF110: start-on-event=SetBlockProtection, operation=PAdmin_Rte_NvmBlock_CustDiag_DidF110.SetBlockProtection
        OpEventSetBlockProtection_SetBlockProtection_PAdmin_Rte_NvmBlock_CustDiag_DidEED0: start-on-event=SetBlockProtection, operation=PAdmin_Rte_NvmBlock_CustDiag_DidEED0.SetBlockProtection
        OpEventSetBlockProtection_SetBlockProtection_PAdmin_Rte_NvmBlock_CustDiag_DidEE83: start-on-event=SetBlockProtection, operation=PAdmin_Rte_NvmBlock_CustDiag_DidEE83.SetBlockProtection
        OpEventSetBlockProtection_SetBlockProtection_PAdmin_Rte_NvmBlock_CustDiag_Did301A: start-on-event=SetBlockProtection, operation=PAdmin_Rte_NvmBlock_CustDiag_Did301A.SetBlockProtection
        OpEventSetBlockProtection_SetBlockProtection_PAdmin_Rte_NvmBlock_CustDiag_DidF162: start-on-event=SetBlockProtection, operation=PAdmin_Rte_NvmBlock_CustDiag_DidF162.SetBlockProtection
        OpEventSetBlockProtection_SetBlockProtection_PAdmin_Rte_NvmBlock_CustDiag_DidEE40: start-on-event=SetBlockProtection, operation=PAdmin_Rte_NvmBlock_CustDiag_DidEE40.SetBlockProtection
        OpEventSetBlockProtection_SetBlockProtection_PAdmin_Rte_NvmBlock_CustDiag_DidEE81: start-on-event=SetBlockProtection, operation=PAdmin_Rte_NvmBlock_CustDiag_DidEE81.SetBlockProtection
        OpEventSetBlockProtection_SetBlockProtection_PAdmin_Rte_NvmBlock_CustDiag_DidEE82: start-on-event=SetBlockProtection, operation=PAdmin_Rte_NvmBlock_CustDiag_DidEE82.SetBlockProtection
        OpEventSetBlockProtection_SetBlockProtection_PAdmin_Rte_NvmBlock_CustDiag_DidEE41: start-on-event=SetBlockProtection, operation=PAdmin_Rte_NvmBlock_CustDiag_DidEE41.SetBlockProtection
        OpEventSetBlockProtection_SetBlockProtection_PAdmin_Rte_NvmBlock_CustDiag_DidEE84: start-on-event=SetBlockProtection, operation=PAdmin_Rte_NvmBlock_CustDiag_DidEE84.SetBlockProtection
        OpEventSetBlockProtection_SetBlockProtection_PAdmin_Rte_NvmBlock_CustDiag_DidF18A: start-on-event=SetBlockProtection, operation=PAdmin_Rte_NvmBlock_CustDiag_DidF18A.SetBlockProtection
        OpEventSetBlockProtection_SetBlockProtection_PAdmin_Rte_NvmBlock_CustDiag_DidEE00: start-on-event=SetBlockProtection, operation=PAdmin_Rte_NvmBlock_CustDiag_DidEE00.SetBlockProtection
        OpEventSetBlockProtection_SetBlockProtection_PAdmin_Rte_NvmBlock_CustDiag_DidF166: start-on-event=SetBlockProtection, operation=PAdmin_Rte_NvmBlock_CustDiag_DidF166.SetBlockProtection
        OpEventSetBlockProtection_SetBlockProtection_PAdmin_Rte_NvmBlock_CustDiag_Did205A: start-on-event=SetBlockProtection, operation=PAdmin_Rte_NvmBlock_CustDiag_Did205A.SetBlockProtection
        OpEventSetBlockProtection_SetBlockProtection_PAdmin_Rte_NvmBlock_CustDiag_DidEE87: start-on-event=SetBlockProtection, operation=PAdmin_Rte_NvmBlock_CustDiag_DidEE87.SetBlockProtection
        OpEventSetBlockProtection_SetBlockProtection_PAdmin_Rte_NvmBlock_CustDiag_DidDE05: start-on-event=SetBlockProtection, operation=PAdmin_Rte_NvmBlock_CustDiag_DidDE05.SetBlockProtection
        OpEventSetBlockProtection_SetBlockProtection_PAdmin_Rte_NvmBlock_CustDiag_DidEE86: start-on-event=SetBlockProtection, operation=PAdmin_Rte_NvmBlock_CustDiag_DidEE86.SetBlockProtection
        OpEventSetBlockProtection_SetBlockProtection_PAdmin_Rte_NvmBlock_CustDiag_DidF163: start-on-event=SetBlockProtection, operation=PAdmin_Rte_NvmBlock_CustDiag_DidF163.SetBlockProtection
        OpEventSetBlockProtection_SetBlockProtection_PAdmin_Rte_NvmBlock_CustDiag_DidF18C: start-on-event=SetBlockProtection, operation=PAdmin_Rte_NvmBlock_CustDiag_DidF18C.SetBlockProtection
        OpEventSetBlockProtection_SetBlockProtection_PAdmin_Rte_NvmBlock_CustDiag_Did205B: start-on-event=SetBlockProtection, operation=PAdmin_Rte_NvmBlock_CustDiag_Did205B.SetBlockProtection
        OpEventSetBlockProtection_SetBlockProtection_PAdmin_Rte_NvmBlock_CustDiag_DidEE85: start-on-event=SetBlockProtection, operation=PAdmin_Rte_NvmBlock_CustDiag_DidEE85.SetBlockProtection
        OpEventRestoreBlockDefaults_RestoreBlockDefaults_PS_Rte_NvmBlock_CustDiag_DidF15F: start-on-event=RestoreBlockDefaults, operation=PS_Rte_NvmBlock_CustDiag_DidF15F.RestoreBlockDefaults
        OpEventRestoreBlockDefaults_RestoreBlockDefaults_PS_Rte_NvmBlock_CustDiag_DidEE88: start-on-event=RestoreBlockDefaults, operation=PS_Rte_NvmBlock_CustDiag_DidEE88.RestoreBlockDefaults
        OpEventRestoreBlockDefaults_RestoreBlockDefaults_PS_Rte_NvmBlock_CustDiag_DidEED0: start-on-event=RestoreBlockDefaults, operation=PS_Rte_NvmBlock_CustDiag_DidEED0.RestoreBlockDefaults
        OpEventRestoreBlockDefaults_RestoreBlockDefaults_PS_Rte_NvmBlock_CustDiag_DidF110: start-on-event=RestoreBlockDefaults, operation=PS_Rte_NvmBlock_CustDiag_DidF110.RestoreBlockDefaults
        OpEventRestoreBlockDefaults_RestoreBlockDefaults_PS_Rte_NvmBlock_CustDiag_DidEE83: start-on-event=RestoreBlockDefaults, operation=PS_Rte_NvmBlock_CustDiag_DidEE83.RestoreBlockDefaults
        OpEventRestoreBlockDefaults_RestoreBlockDefaults_PS_Rte_NvmBlock_CustDiag_Did301A: start-on-event=RestoreBlockDefaults, operation=PS_Rte_NvmBlock_CustDiag_Did301A.RestoreBlockDefaults
        OpEventRestoreBlockDefaults_RestoreBlockDefaults_PS_Rte_NvmBlock_CustDiag_DidF162: start-on-event=RestoreBlockDefaults, operation=PS_Rte_NvmBlock_CustDiag_DidF162.RestoreBlockDefaults
        OpEventRestoreBlockDefaults_RestoreBlockDefaults_PS_Rte_NvmBlock_CustDiag_DidEE40: start-on-event=RestoreBlockDefaults, operation=PS_Rte_NvmBlock_CustDiag_DidEE40.RestoreBlockDefaults
        OpEventRestoreBlockDefaults_RestoreBlockDefaults_PS_Rte_NvmBlock_CustDiag_DidEE82: start-on-event=RestoreBlockDefaults, operation=PS_Rte_NvmBlock_CustDiag_DidEE82.RestoreBlockDefaults
        OpEventRestoreBlockDefaults_RestoreBlockDefaults_PS_Rte_NvmBlock_CustDiag_DidEE81: start-on-event=RestoreBlockDefaults, operation=PS_Rte_NvmBlock_CustDiag_DidEE81.RestoreBlockDefaults
        OpEventRestoreBlockDefaults_RestoreBlockDefaults_PS_Rte_NvmBlock_CustDiag_DidEE41: start-on-event=RestoreBlockDefaults, operation=PS_Rte_NvmBlock_CustDiag_DidEE41.RestoreBlockDefaults
        OpEventRestoreBlockDefaults_RestoreBlockDefaults_PS_Rte_NvmBlock_CustDiag_DidEE84: start-on-event=RestoreBlockDefaults, operation=PS_Rte_NvmBlock_CustDiag_DidEE84.RestoreBlockDefaults
        OpEventRestoreBlockDefaults_RestoreBlockDefaults_PS_Rte_NvmBlock_CustDiag_DidF18A: start-on-event=RestoreBlockDefaults, operation=PS_Rte_NvmBlock_CustDiag_DidF18A.RestoreBlockDefaults
        OpEventRestoreBlockDefaults_RestoreBlockDefaults_PS_Rte_NvmBlock_CustDiag_DidEE00: start-on-event=RestoreBlockDefaults, operation=PS_Rte_NvmBlock_CustDiag_DidEE00.RestoreBlockDefaults
        OpEventRestoreBlockDefaults_RestoreBlockDefaults_PS_Rte_NvmBlock_CustDiag_DidF166: start-on-event=RestoreBlockDefaults, operation=PS_Rte_NvmBlock_CustDiag_DidF166.RestoreBlockDefaults
        OpEventRestoreBlockDefaults_RestoreBlockDefaults_PS_Rte_NvmBlock_CustDiag_DidEE87: start-on-event=RestoreBlockDefaults, operation=PS_Rte_NvmBlock_CustDiag_DidEE87.RestoreBlockDefaults
        OpEventRestoreBlockDefaults_RestoreBlockDefaults_PS_Rte_NvmBlock_CustDiag_Did205A: start-on-event=RestoreBlockDefaults, operation=PS_Rte_NvmBlock_CustDiag_Did205A.RestoreBlockDefaults
        OpEventRestoreBlockDefaults_RestoreBlockDefaults_PS_Rte_NvmBlock_CustDiag_DidDE05: start-on-event=RestoreBlockDefaults, operation=PS_Rte_NvmBlock_CustDiag_DidDE05.RestoreBlockDefaults
        OpEventRestoreBlockDefaults_RestoreBlockDefaults_PS_Rte_NvmBlock_CustDiag_DidEE86: start-on-event=RestoreBlockDefaults, operation=PS_Rte_NvmBlock_CustDiag_DidEE86.RestoreBlockDefaults
        OpEventRestoreBlockDefaults_RestoreBlockDefaults_PS_Rte_NvmBlock_CustDiag_DidF163: start-on-event=RestoreBlockDefaults, operation=PS_Rte_NvmBlock_CustDiag_DidF163.RestoreBlockDefaults
        OpEventRestoreBlockDefaults_RestoreBlockDefaults_PS_Rte_NvmBlock_CustDiag_DidF18C: start-on-event=RestoreBlockDefaults, operation=PS_Rte_NvmBlock_CustDiag_DidF18C.RestoreBlockDefaults
        OpEventRestoreBlockDefaults_RestoreBlockDefaults_PS_Rte_NvmBlock_CustDiag_Did205B: start-on-event=RestoreBlockDefaults, operation=PS_Rte_NvmBlock_CustDiag_Did205B.RestoreBlockDefaults
        OpEventRestoreBlockDefaults_RestoreBlockDefaults_PS_Rte_NvmBlock_CustDiag_DidEE85: start-on-event=RestoreBlockDefaults, operation=PS_Rte_NvmBlock_CustDiag_DidEE85.RestoreBlockDefaults
        OpEventGetErrorStatus_GetErrorStatus_PS_Rte_NvmBlock_CustDiag_DidEE21: start-on-event=GetErrorStatus, operation=PS_Rte_NvmBlock_CustDiag_DidEE21.GetErrorStatus
        OpEventGetErrorStatus_GetErrorStatus_PS_Rte_NvmBlock_CustDiag_DidEE22: start-on-event=GetErrorStatus, operation=PS_Rte_NvmBlock_CustDiag_DidEE22.GetErrorStatus
        OpEventGetErrorStatus_GetErrorStatus_PS_Rte_NvmBlock_CustDiag_DidF190: start-on-event=GetErrorStatus, operation=PS_Rte_NvmBlock_CustDiag_DidF190.GetErrorStatus
        OpEventGetErrorStatus_GetErrorStatus_PS_Rte_NvmBlock_CustDiag_Did630F: start-on-event=GetErrorStatus, operation=PS_Rte_NvmBlock_CustDiag_Did630F.GetErrorStatus
        OpEventGetErrorStatus_GetErrorStatus_PS_Rte_NvmBlock_CustDiag_Did630FChk: start-on-event=GetErrorStatus, operation=PS_Rte_NvmBlock_CustDiag_Did630FChk.GetErrorStatus
        OpEventGetErrorStatus_GetErrorStatus_PS_Rte_NvmBlock_CustDiag_DidEE23: start-on-event=GetErrorStatus, operation=PS_Rte_NvmBlock_CustDiag_DidEE23.GetErrorStatus
        OpEventSetRamBlockStatus_SetRamBlockStatus_PS_Rte_NvmBlock_CustDiag_DidEE21: start-on-event=SetRamBlockStatus, operation=PS_Rte_NvmBlock_CustDiag_DidEE21.SetRamBlockStatus
        OpEventSetRamBlockStatus_SetRamBlockStatus_PS_Rte_NvmBlock_CustDiag_DidEE22: start-on-event=SetRamBlockStatus, operation=PS_Rte_NvmBlock_CustDiag_DidEE22.SetRamBlockStatus
        OpEventSetRamBlockStatus_SetRamBlockStatus_PS_Rte_NvmBlock_CustDiag_DidF190: start-on-event=SetRamBlockStatus, operation=PS_Rte_NvmBlock_CustDiag_DidF190.SetRamBlockStatus
        OpEventSetRamBlockStatus_SetRamBlockStatus_PS_Rte_NvmBlock_CustDiag_Did630F: start-on-event=SetRamBlockStatus, operation=PS_Rte_NvmBlock_CustDiag_Did630F.SetRamBlockStatus
        OpEventSetRamBlockStatus_SetRamBlockStatus_PS_Rte_NvmBlock_CustDiag_Did630FChk: start-on-event=SetRamBlockStatus, operation=PS_Rte_NvmBlock_CustDiag_Did630FChk.SetRamBlockStatus
        OpEventSetRamBlockStatus_SetRamBlockStatus_PS_Rte_NvmBlock_CustDiag_DidEE23: start-on-event=SetRamBlockStatus, operation=PS_Rte_NvmBlock_CustDiag_DidEE23.SetRamBlockStatus
        OpEventReadBlock_ReadBlock_PS_Rte_NvmBlock_CustDiag_DidEE21: start-on-event=ReadBlock, operation=PS_Rte_NvmBlock_CustDiag_DidEE21.ReadBlock
        OpEventReadBlock_ReadBlock_PS_Rte_NvmBlock_CustDiag_DidEE22: start-on-event=ReadBlock, operation=PS_Rte_NvmBlock_CustDiag_DidEE22.ReadBlock
        OpEventReadBlock_ReadBlock_PS_Rte_NvmBlock_CustDiag_DidF190: start-on-event=ReadBlock, operation=PS_Rte_NvmBlock_CustDiag_DidF190.ReadBlock
        OpEventReadBlock_ReadBlock_PS_Rte_NvmBlock_CustDiag_Did630F: start-on-event=ReadBlock, operation=PS_Rte_NvmBlock_CustDiag_Did630F.ReadBlock
        OpEventReadBlock_ReadBlock_PS_Rte_NvmBlock_CustDiag_Did630FChk: start-on-event=ReadBlock, operation=PS_Rte_NvmBlock_CustDiag_Did630FChk.ReadBlock
        OpEventReadBlock_ReadBlock_PS_Rte_NvmBlock_CustDiag_DidEE23: start-on-event=ReadBlock, operation=PS_Rte_NvmBlock_CustDiag_DidEE23.ReadBlock
        OpEventWriteBlock_WriteBlock_PS_Rte_NvmBlock_CustDiag_DidEE21: start-on-event=WriteBlock, operation=PS_Rte_NvmBlock_CustDiag_DidEE21.WriteBlock
        OpEventWriteBlock_WriteBlock_PS_Rte_NvmBlock_CustDiag_DidEE22: start-on-event=WriteBlock, operation=PS_Rte_NvmBlock_CustDiag_DidEE22.WriteBlock
        OpEventWriteBlock_WriteBlock_PS_Rte_NvmBlock_CustDiag_DidF190: start-on-event=WriteBlock, operation=PS_Rte_NvmBlock_CustDiag_DidF190.WriteBlock
        OpEventWriteBlock_WriteBlock_PS_Rte_NvmBlock_CustDiag_Did630F: start-on-event=WriteBlock, operation=PS_Rte_NvmBlock_CustDiag_Did630F.WriteBlock
        OpEventWriteBlock_WriteBlock_PS_Rte_NvmBlock_CustDiag_Did630FChk: start-on-event=WriteBlock, operation=PS_Rte_NvmBlock_CustDiag_Did630FChk.WriteBlock
        OpEventWriteBlock_WriteBlock_PS_Rte_NvmBlock_CustDiag_DidEE23: start-on-event=WriteBlock, operation=PS_Rte_NvmBlock_CustDiag_DidEE23.WriteBlock
        OpEventInvalidateNvBlock_InvalidateNvBlock_PS_Rte_NvmBlock_CustDiag_DidEE21: start-on-event=InvalidateNvBlock, operation=PS_Rte_NvmBlock_CustDiag_DidEE21.InvalidateNvBlock
        OpEventInvalidateNvBlock_InvalidateNvBlock_PS_Rte_NvmBlock_CustDiag_DidEE22: start-on-event=InvalidateNvBlock, operation=PS_Rte_NvmBlock_CustDiag_DidEE22.InvalidateNvBlock
        OpEventInvalidateNvBlock_InvalidateNvBlock_PS_Rte_NvmBlock_CustDiag_DidF190: start-on-event=InvalidateNvBlock, operation=PS_Rte_NvmBlock_CustDiag_DidF190.InvalidateNvBlock
        OpEventInvalidateNvBlock_InvalidateNvBlock_PS_Rte_NvmBlock_CustDiag_Did630F: start-on-event=InvalidateNvBlock, operation=PS_Rte_NvmBlock_CustDiag_Did630F.InvalidateNvBlock
        OpEventInvalidateNvBlock_InvalidateNvBlock_PS_Rte_NvmBlock_CustDiag_Did630FChk: start-on-event=InvalidateNvBlock, operation=PS_Rte_NvmBlock_CustDiag_Did630FChk.InvalidateNvBlock
        OpEventInvalidateNvBlock_InvalidateNvBlock_PS_Rte_NvmBlock_CustDiag_DidEE23: start-on-event=InvalidateNvBlock, operation=PS_Rte_NvmBlock_CustDiag_DidEE23.InvalidateNvBlock
        OpEventEraseBlock_EraseBlock_PS_Rte_NvmBlock_CustDiag_DidEE21: start-on-event=EraseBlock, operation=PS_Rte_NvmBlock_CustDiag_DidEE21.EraseBlock
        OpEventEraseBlock_EraseBlock_PS_Rte_NvmBlock_CustDiag_DidEE22: start-on-event=EraseBlock, operation=PS_Rte_NvmBlock_CustDiag_DidEE22.EraseBlock
        OpEventEraseBlock_EraseBlock_PS_Rte_NvmBlock_CustDiag_DidF190: start-on-event=EraseBlock, operation=PS_Rte_NvmBlock_CustDiag_DidF190.EraseBlock
        OpEventEraseBlock_EraseBlock_PS_Rte_NvmBlock_CustDiag_Did630F: start-on-event=EraseBlock, operation=PS_Rte_NvmBlock_CustDiag_Did630F.EraseBlock
        OpEventEraseBlock_EraseBlock_PS_Rte_NvmBlock_CustDiag_Did630FChk: start-on-event=EraseBlock, operation=PS_Rte_NvmBlock_CustDiag_Did630FChk.EraseBlock
        OpEventEraseBlock_EraseBlock_PS_Rte_NvmBlock_CustDiag_DidEE23: start-on-event=EraseBlock, operation=PS_Rte_NvmBlock_CustDiag_DidEE23.EraseBlock
        OpEventSetBlockProtection_SetBlockProtection_PAdmin_Rte_NvmBlock_CustDiag_DidEE21: start-on-event=SetBlockProtection, operation=PAdmin_Rte_NvmBlock_CustDiag_DidEE21.SetBlockProtection
        OpEventSetBlockProtection_SetBlockProtection_PAdmin_Rte_NvmBlock_CustDiag_DidEE22: start-on-event=SetBlockProtection, operation=PAdmin_Rte_NvmBlock_CustDiag_DidEE22.SetBlockProtection
        OpEventSetBlockProtection_SetBlockProtection_PAdmin_Rte_NvmBlock_CustDiag_DidF190: start-on-event=SetBlockProtection, operation=PAdmin_Rte_NvmBlock_CustDiag_DidF190.SetBlockProtection
        OpEventSetBlockProtection_SetBlockProtection_PAdmin_Rte_NvmBlock_CustDiag_Did630F: start-on-event=SetBlockProtection, operation=PAdmin_Rte_NvmBlock_CustDiag_Did630F.SetBlockProtection
        OpEventSetBlockProtection_SetBlockProtection_PAdmin_Rte_NvmBlock_CustDiag_Did630FChk: start-on-event=SetBlockProtection, operation=PAdmin_Rte_NvmBlock_CustDiag_Did630FChk.SetBlockProtection
        OpEventSetBlockProtection_SetBlockProtection_PAdmin_Rte_NvmBlock_CustDiag_DidEE23: start-on-event=SetBlockProtection, operation=PAdmin_Rte_NvmBlock_CustDiag_DidEE23.SetBlockProtection
        OpEventRestoreBlockDefaults_RestoreBlockDefaults_PS_Rte_NvmBlock_CustDiag_DidEE21: start-on-event=RestoreBlockDefaults, operation=PS_Rte_NvmBlock_CustDiag_DidEE21.RestoreBlockDefaults
        OpEventRestoreBlockDefaults_RestoreBlockDefaults_PS_Rte_NvmBlock_CustDiag_DidEE22: start-on-event=RestoreBlockDefaults, operation=PS_Rte_NvmBlock_CustDiag_DidEE22.RestoreBlockDefaults
        OpEventRestoreBlockDefaults_RestoreBlockDefaults_PS_Rte_NvmBlock_CustDiag_DidF190: start-on-event=RestoreBlockDefaults, operation=PS_Rte_NvmBlock_CustDiag_DidF190.RestoreBlockDefaults
        OpEventRestoreBlockDefaults_RestoreBlockDefaults_PS_Rte_NvmBlock_CustDiag_Did630F: start-on-event=RestoreBlockDefaults, operation=PS_Rte_NvmBlock_CustDiag_Did630F.RestoreBlockDefaults
        OpEventRestoreBlockDefaults_RestoreBlockDefaults_PS_Rte_NvmBlock_CustDiag_Did630FChk: start-on-event=RestoreBlockDefaults, operation=PS_Rte_NvmBlock_CustDiag_Did630FChk.RestoreBlockDefaults
        OpEventRestoreBlockDefaults_RestoreBlockDefaults_PS_Rte_NvmBlock_CustDiag_DidEE23: start-on-event=RestoreBlockDefaults, operation=PS_Rte_NvmBlock_CustDiag_DidEE23.RestoreBlockDefaults
        OpEventGetErrorStatus_GetErrorStatus_PS_Rte_NvmBlock_StackMeas_StackMeasRes: start-on-event=GetErrorStatus, operation=PS_Rte_NvmBlock_StackMeas_StackMeasRes.GetErrorStatus
        OpEventSetRamBlockStatus_SetRamBlockStatus_PS_Rte_NvmBlock_StackMeas_StackMeasRes: start-on-event=SetRamBlockStatus, operation=PS_Rte_NvmBlock_StackMeas_StackMeasRes.SetRamBlockStatus
        OpEventReadBlock_ReadBlock_PS_Rte_NvmBlock_StackMeas_StackMeasRes: start-on-event=ReadBlock, operation=PS_Rte_NvmBlock_StackMeas_StackMeasRes.ReadBlock
        OpEventWriteBlock_WriteBlock_PS_Rte_NvmBlock_StackMeas_StackMeasRes: start-on-event=WriteBlock, operation=PS_Rte_NvmBlock_StackMeas_StackMeasRes.WriteBlock
        OpEventInvalidateNvBlock_InvalidateNvBlock_PS_Rte_NvmBlock_StackMeas_StackMeasRes: start-on-event=InvalidateNvBlock, operation=PS_Rte_NvmBlock_StackMeas_StackMeasRes.InvalidateNvBlock
        OpEventEraseBlock_EraseBlock_PS_Rte_NvmBlock_StackMeas_StackMeasRes: start-on-event=EraseBlock, operation=PS_Rte_NvmBlock_StackMeas_StackMeasRes.EraseBlock
        OpEventSetBlockProtection_SetBlockProtection_PAdmin_Rte_NvmBlock_StackMeas_StackMeasRes: start-on-event=SetBlockProtection, operation=PAdmin_Rte_NvmBlock_StackMeas_StackMeasRes.SetBlockProtection
        OpEventRestoreBlockDefaults_RestoreBlockDefaults_PS_Rte_NvmBlock_StackMeas_StackMeasRes: start-on-event=RestoreBlockDefaults, operation=PS_Rte_NvmBlock_StackMeas_StackMeasRes.RestoreBlockDefaults
        OpEventGetErrorStatus_GetErrorStatus_PS_Rte_NvmBlock_StackMeas_StackMeasApplCrc: start-on-event=GetErrorStatus, operation=PS_Rte_NvmBlock_StackMeas_StackMeasApplCrc.GetErrorStatus
        OpEventSetRamBlockStatus_SetRamBlockStatus_PS_Rte_NvmBlock_StackMeas_StackMeasApplCrc: start-on-event=SetRamBlockStatus, operation=PS_Rte_NvmBlock_StackMeas_StackMeasApplCrc.SetRamBlockStatus
        OpEventReadBlock_ReadBlock_PS_Rte_NvmBlock_StackMeas_StackMeasApplCrc: start-on-event=ReadBlock, operation=PS_Rte_NvmBlock_StackMeas_StackMeasApplCrc.ReadBlock
        OpEventWriteBlock_WriteBlock_PS_Rte_NvmBlock_StackMeas_StackMeasApplCrc: start-on-event=WriteBlock, operation=PS_Rte_NvmBlock_StackMeas_StackMeasApplCrc.WriteBlock
        OpEventInvalidateNvBlock_InvalidateNvBlock_PS_Rte_NvmBlock_StackMeas_StackMeasApplCrc: start-on-event=InvalidateNvBlock, operation=PS_Rte_NvmBlock_StackMeas_StackMeasApplCrc.InvalidateNvBlock
        OpEventEraseBlock_EraseBlock_PS_Rte_NvmBlock_StackMeas_StackMeasApplCrc: start-on-event=EraseBlock, operation=PS_Rte_NvmBlock_StackMeas_StackMeasApplCrc.EraseBlock
        OpEventSetBlockProtection_SetBlockProtection_PAdmin_Rte_NvmBlock_StackMeas_StackMeasApplCrc: start-on-event=SetBlockProtection, operation=PAdmin_Rte_NvmBlock_StackMeas_StackMeasApplCrc.SetBlockProtection
        OpEventGetErrorStatus_GetErrorStatus_PS_Rte_NvmBlock_CDD_FordBlaBoxIfCmp1_LaneAssi: start-on-event=GetErrorStatus, operation=PS_Rte_NvmBlock_CDD_FordBlaBoxIfCmp1_LaneAssi.GetErrorStatus
        OpEventGetErrorStatus_GetErrorStatus_PS_Rte_NvmBlock_CDD_FordBlaBoxIfCmp1_PullDriftCmp: start-on-event=GetErrorStatus, operation=PS_Rte_NvmBlock_CDD_FordBlaBoxIfCmp1_PullDriftCmp.GetErrorStatus
        OpEventGetErrorStatus_GetErrorStatus_PS_Rte_NvmBlock_CDD_FordBlaBoxIfCmp1_TrlrBackupAssi: start-on-event=GetErrorStatus, operation=PS_Rte_NvmBlock_CDD_FordBlaBoxIfCmp1_TrlrBackupAssi.GetErrorStatus
        OpEventGetErrorStatus_GetErrorStatus_PS_Rte_NvmBlock_CDD_FordBlaBoxIfCmp1_ActvNiblCtrl: start-on-event=GetErrorStatus, operation=PS_Rte_NvmBlock_CDD_FordBlaBoxIfCmp1_ActvNiblCtrl.GetErrorStatus
        OpEventSetRamBlockStatus_SetRamBlockStatus_PS_Rte_NvmBlock_CDD_FordBlaBoxIfCmp1_LaneAssi: start-on-event=SetRamBlockStatus, operation=PS_Rte_NvmBlock_CDD_FordBlaBoxIfCmp1_LaneAssi.SetRamBlockStatus
        OpEventSetRamBlockStatus_SetRamBlockStatus_PS_Rte_NvmBlock_CDD_FordBlaBoxIfCmp1_PullDriftCmp: start-on-event=SetRamBlockStatus, operation=PS_Rte_NvmBlock_CDD_FordBlaBoxIfCmp1_PullDriftCmp.SetRamBlockStatus
        OpEventSetRamBlockStatus_SetRamBlockStatus_PS_Rte_NvmBlock_CDD_FordBlaBoxIfCmp1_TrlrBackupAssi: start-on-event=SetRamBlockStatus, operation=PS_Rte_NvmBlock_CDD_FordBlaBoxIfCmp1_TrlrBackupAssi.SetRamBlockStatus
        OpEventSetRamBlockStatus_SetRamBlockStatus_PS_Rte_NvmBlock_CDD_FordBlaBoxIfCmp1_ActvNiblCtrl: start-on-event=SetRamBlockStatus, operation=PS_Rte_NvmBlock_CDD_FordBlaBoxIfCmp1_ActvNiblCtrl.SetRamBlockStatus
        OpEventReadBlock_ReadBlock_PS_Rte_NvmBlock_CDD_FordBlaBoxIfCmp1_LaneAssi: start-on-event=ReadBlock, operation=PS_Rte_NvmBlock_CDD_FordBlaBoxIfCmp1_LaneAssi.ReadBlock
        OpEventReadBlock_ReadBlock_PS_Rte_NvmBlock_CDD_FordBlaBoxIfCmp1_PullDriftCmp: start-on-event=ReadBlock, operation=PS_Rte_NvmBlock_CDD_FordBlaBoxIfCmp1_PullDriftCmp.ReadBlock
        OpEventReadBlock_ReadBlock_PS_Rte_NvmBlock_CDD_FordBlaBoxIfCmp1_TrlrBackupAssi: start-on-event=ReadBlock, operation=PS_Rte_NvmBlock_CDD_FordBlaBoxIfCmp1_TrlrBackupAssi.ReadBlock
        OpEventReadBlock_ReadBlock_PS_Rte_NvmBlock_CDD_FordBlaBoxIfCmp1_ActvNiblCtrl: start-on-event=ReadBlock, operation=PS_Rte_NvmBlock_CDD_FordBlaBoxIfCmp1_ActvNiblCtrl.ReadBlock
        OpEventWriteBlock_WriteBlock_PS_Rte_NvmBlock_CDD_FordBlaBoxIfCmp1_LaneAssi: start-on-event=WriteBlock, operation=PS_Rte_NvmBlock_CDD_FordBlaBoxIfCmp1_LaneAssi.WriteBlock
        OpEventWriteBlock_WriteBlock_PS_Rte_NvmBlock_CDD_FordBlaBoxIfCmp1_PullDriftCmp: start-on-event=WriteBlock, operation=PS_Rte_NvmBlock_CDD_FordBlaBoxIfCmp1_PullDriftCmp.WriteBlock
        OpEventWriteBlock_WriteBlock_PS_Rte_NvmBlock_CDD_FordBlaBoxIfCmp1_TrlrBackupAssi: start-on-event=WriteBlock, operation=PS_Rte_NvmBlock_CDD_FordBlaBoxIfCmp1_TrlrBackupAssi.WriteBlock
        OpEventWriteBlock_WriteBlock_PS_Rte_NvmBlock_CDD_FordBlaBoxIfCmp1_ActvNiblCtrl: start-on-event=WriteBlock, operation=PS_Rte_NvmBlock_CDD_FordBlaBoxIfCmp1_ActvNiblCtrl.WriteBlock
        OpEventInvalidateNvBlock_InvalidateNvBlock_PS_Rte_NvmBlock_CDD_FordBlaBoxIfCmp1_LaneAssi: start-on-event=InvalidateNvBlock, operation=PS_Rte_NvmBlock_CDD_FordBlaBoxIfCmp1_LaneAssi.InvalidateNvBlock
        OpEventInvalidateNvBlock_InvalidateNvBlock_PS_Rte_NvmBlock_CDD_FordBlaBoxIfCmp1_PullDriftCmp: start-on-event=InvalidateNvBlock, operation=PS_Rte_NvmBlock_CDD_FordBlaBoxIfCmp1_PullDriftCmp.InvalidateNvBlock
        OpEventInvalidateNvBlock_InvalidateNvBlock_PS_Rte_NvmBlock_CDD_FordBlaBoxIfCmp1_TrlrBackupAssi: start-on-event=InvalidateNvBlock, operation=PS_Rte_NvmBlock_CDD_FordBlaBoxIfCmp1_TrlrBackupAssi.InvalidateNvBlock
        OpEventInvalidateNvBlock_InvalidateNvBlock_PS_Rte_NvmBlock_CDD_FordBlaBoxIfCmp1_ActvNiblCtrl: start-on-event=InvalidateNvBlock, operation=PS_Rte_NvmBlock_CDD_FordBlaBoxIfCmp1_ActvNiblCtrl.InvalidateNvBlock
        OpEventEraseBlock_EraseBlock_PS_Rte_NvmBlock_CDD_FordBlaBoxIfCmp1_LaneAssi: start-on-event=EraseBlock, operation=PS_Rte_NvmBlock_CDD_FordBlaBoxIfCmp1_LaneAssi.EraseBlock
        OpEventEraseBlock_EraseBlock_PS_Rte_NvmBlock_CDD_FordBlaBoxIfCmp1_PullDriftCmp: start-on-event=EraseBlock, operation=PS_Rte_NvmBlock_CDD_FordBlaBoxIfCmp1_PullDriftCmp.EraseBlock
        OpEventEraseBlock_EraseBlock_PS_Rte_NvmBlock_CDD_FordBlaBoxIfCmp1_TrlrBackupAssi: start-on-event=EraseBlock, operation=PS_Rte_NvmBlock_CDD_FordBlaBoxIfCmp1_TrlrBackupAssi.EraseBlock
        OpEventEraseBlock_EraseBlock_PS_Rte_NvmBlock_CDD_FordBlaBoxIfCmp1_ActvNiblCtrl: start-on-event=EraseBlock, operation=PS_Rte_NvmBlock_CDD_FordBlaBoxIfCmp1_ActvNiblCtrl.EraseBlock
        OpEventSetBlockProtection_SetBlockProtection_PAdmin_Rte_NvmBlock_CDD_FordBlaBoxIfCmp1_LaneAssi: start-on-event=SetBlockProtection, operation=PAdmin_Rte_NvmBlock_CDD_FordBlaBoxIfCmp1_LaneAssi.SetBlockProtection
        OpEventSetBlockProtection_SetBlockProtection_PAdmin_Rte_NvmBlock_CDD_FordBlaBoxIfCmp1_PullDriftCmp: start-on-event=SetBlockProtection, operation=PAdmin_Rte_NvmBlock_CDD_FordBlaBoxIfCmp1_PullDriftCmp.SetBlockProtection
        OpEventSetBlockProtection_SetBlockProtection_PAdmin_Rte_NvmBlock_CDD_FordBlaBoxIfCmp1_TrlrBackupAssi: start-on-event=SetBlockProtection, operation=PAdmin_Rte_NvmBlock_CDD_FordBlaBoxIfCmp1_TrlrBackupAssi.SetBlockProtection
        OpEventSetBlockProtection_SetBlockProtection_PAdmin_Rte_NvmBlock_CDD_FordBlaBoxIfCmp1_ActvNiblCtrl: start-on-event=SetBlockProtection, operation=PAdmin_Rte_NvmBlock_CDD_FordBlaBoxIfCmp1_ActvNiblCtrl.SetBlockProtection
        OpEventRestoreBlockDefaults_RestoreBlockDefaults_PS_Rte_NvmBlock_CDD_FordBlaBoxIfCmp1_LaneAssi: start-on-event=RestoreBlockDefaults, operation=PS_Rte_NvmBlock_CDD_FordBlaBoxIfCmp1_LaneAssi.RestoreBlockDefaults
        OpEventRestoreBlockDefaults_RestoreBlockDefaults_PS_Rte_NvmBlock_CDD_FordBlaBoxIfCmp1_TrlrBackupAssi: start-on-event=RestoreBlockDefaults, operation=PS_Rte_NvmBlock_CDD_FordBlaBoxIfCmp1_TrlrBackupAssi.RestoreBlockDefaults
        OpEventRestoreBlockDefaults_RestoreBlockDefaults_PS_Rte_NvmBlock_CDD_FordBlaBoxIfCmp1_PullDriftCmp: start-on-event=RestoreBlockDefaults, operation=PS_Rte_NvmBlock_CDD_FordBlaBoxIfCmp1_PullDriftCmp.RestoreBlockDefaults
        OpEventRestoreBlockDefaults_RestoreBlockDefaults_PS_Rte_NvmBlock_CDD_FordBlaBoxIfCmp1_ActvNiblCtrl: start-on-event=RestoreBlockDefaults, operation=PS_Rte_NvmBlock_CDD_FordBlaBoxIfCmp1_ActvNiblCtrl.RestoreBlockDefaults
      port-api-options:
        {enable-take-address=true, indirect-api=false, port-defined-argument-value{value=96, value-type=NvM_BlockIdType}, port=PS_Rte_NvmBlock_CDD_NvMProxy_ShtdwnClsChk}
        {enable-take-address=true, indirect-api=false, port-defined-argument-value{value=96, value-type=NvM_BlockIdType}, port=PAdmin_Rte_NvmBlock_CDD_NvMProxy_ShtdwnClsChk}
        {enable-take-address=true, indirect-api=false, port-defined-argument-value{value=93, value-type=NvM_BlockIdType}, port=PS_Rte_NvmBlock_DiagcMgr_DiagcMgrApplCrc}
        {enable-take-address=true, indirect-api=false, port-defined-argument-value{value=93, value-type=NvM_BlockIdType}, port=PAdmin_Rte_NvmBlock_DiagcMgr_DiagcMgrApplCrc}
        {enable-take-address=true, indirect-api=false, port-defined-argument-value{value=94, value-type=NvM_BlockIdType}, port=PS_Rte_NvmBlock_DiagcMgr_DiagcMgrLtchCntrAry}
        {enable-take-address=true, indirect-api=false, port-defined-argument-value{value=94, value-type=NvM_BlockIdType}, port=PAdmin_Rte_NvmBlock_DiagcMgr_DiagcMgrLtchCntrAry}
        {enable-take-address=true, indirect-api=false, port-defined-argument-value{value=95, value-type=NvM_BlockIdType}, port=PS_Rte_NvmBlock_DiagcMgr_DiagcMgrNtcFltAry}
        {enable-take-address=true, indirect-api=false, port-defined-argument-value{value=95, value-type=NvM_BlockIdType}, port=PAdmin_Rte_NvmBlock_DiagcMgr_DiagcMgrNtcFltAry}
        {enable-take-address=true, indirect-api=false, port-defined-argument-value{value=92, value-type=NvM_BlockIdType}, port=PS_SnpshtDataAry}
        {enable-take-address=true, indirect-api=false, port-defined-argument-value{value=92, value-type=NvM_BlockIdType}, port=PAdmin_SnpshtDataAry}
        {enable-take-address=true, indirect-api=false, port-defined-argument-value{value=91, value-type=NvM_BlockIdType}, port=PS_Rte_NvmBlock_CDD_MotAgCmp_MotAgCmpMotAgBackEmf}
        {enable-take-address=true, indirect-api=false, port-defined-argument-value{value=91, value-type=NvM_BlockIdType}, port=PAdmin_Rte_NvmBlock_CDD_MotAgCmp_MotAgCmpMotAgBackEmf}
        {enable-take-address=true, indirect-api=false, port-defined-argument-value{value=90, value-type=NvM_BlockIdType}, port=PS_Rte_NvmBlock_MotAg2Meas_MotAg2EolPrm}
        {enable-take-address=true, indirect-api=false, port-defined-argument-value{value=90, value-type=NvM_BlockIdType}, port=PAdmin_Rte_NvmBlock_MotAg2Meas_MotAg2EolPrm}
        {enable-take-address=true, indirect-api=false, port-defined-argument-value{value=89, value-type=NvM_BlockIdType}, port=PS_Rte_NvmBlock_PolarityCfg_PolarityCfgSaved}
        {enable-take-address=true, indirect-api=false, port-defined-argument-value{value=89, value-type=NvM_BlockIdType}, port=PAdmin_Rte_NvmBlock_PolarityCfg_PolarityCfgSaved}
        {enable-take-address=true, indirect-api=false, port-defined-argument-value{value=87, value-type=NvM_BlockIdType}, port=PS_Rte_NvmBlock_CDD_CurrMeas_CurrMeasEolGainCalSetABC}
        {enable-take-address=true, indirect-api=false, port-defined-argument-value{value=87, value-type=NvM_BlockIdType}, port=PAdmin_Rte_NvmBlock_CDD_CurrMeas_CurrMeasEolGainCalSetABC}
        {enable-take-address=true, indirect-api=false, port-defined-argument-value{value=88, value-type=NvM_BlockIdType}, port=PS_Rte_NvmBlock_CDD_CurrMeas_CurrMeasEolOffsCalSetABC}
        {enable-take-address=true, indirect-api=false, port-defined-argument-value{value=88, value-type=NvM_BlockIdType}, port=PAdmin_Rte_NvmBlock_CDD_CurrMeas_CurrMeasEolOffsCalSetABC}
        {enable-take-address=true, indirect-api=false, port-defined-argument-value{value=86, value-type=NvM_BlockIdType}, port=PS_Rte_NvmBlock_HwAgSnsrls_StordLstPrm}
        {enable-take-address=true, indirect-api=false, port-defined-argument-value{value=86, value-type=NvM_BlockIdType}, port=PAdmin_Rte_NvmBlock_HwAgSnsrls_StordLstPrm}
        {enable-take-address=true, indirect-api=false, port-defined-argument-value{value=84, value-type=NvM_BlockIdType}, port=PS_Rte_NvmBlock_EotLrng_EotNvmData}
        {enable-take-address=true, indirect-api=false, port-defined-argument-value{value=84, value-type=NvM_BlockIdType}, port=PAdmin_Rte_NvmBlock_EotLrng_EotNvmData}
        {enable-take-address=true, indirect-api=false, port-defined-argument-value{value=85, value-type=NvM_BlockIdType}, port=PS_Rte_NvmBlock_EotLrng_MaxHwAgCwAndCcw}
        {enable-take-address=true, indirect-api=false, port-defined-argument-value{value=85, value-type=NvM_BlockIdType}, port=PAdmin_Rte_NvmBlock_EotLrng_MaxHwAgCwAndCcw}
        {enable-take-address=true, indirect-api=false, port-defined-argument-value{value=80, value-type=NvM_BlockIdType}, port=PS_Rte_NvmBlock_CDD_MotRplCoggCmd_MotCoggCmdY}
        {enable-take-address=true, indirect-api=false, port-defined-argument-value{value=80, value-type=NvM_BlockIdType}, port=PAdmin_Rte_NvmBlock_CDD_MotRplCoggCmd_MotCoggCmdY}
        {enable-take-address=true, indirect-api=false, port-defined-argument-value{value=81, value-type=NvM_BlockIdType}, port=PS_Rte_NvmBlock_MotRplCoggCfg_MotRplCoggPrm}
        {enable-take-address=true, indirect-api=false, port-defined-argument-value{value=81, value-type=NvM_BlockIdType}, port=PAdmin_Rte_NvmBlock_MotRplCoggCfg_MotRplCoggPrm}
        {enable-take-address=true, indirect-api=false, port-defined-argument-value{value=82, value-type=NvM_BlockIdType}, port=PS_Rte_NvmBlock_SysFricLrng_FricNonLrngData}
        {enable-take-address=true, indirect-api=false, port-defined-argument-value{value=82, value-type=NvM_BlockIdType}, port=PAdmin_Rte_NvmBlock_SysFricLrng_FricNonLrngData}
        {enable-take-address=true, indirect-api=false, port-defined-argument-value{value=83, value-type=NvM_BlockIdType}, port=PS_Rte_NvmBlock_SysFricLrng_FricLrngData}
        {enable-take-address=true, indirect-api=false, port-defined-argument-value{value=83, value-type=NvM_BlockIdType}, port=PAdmin_Rte_NvmBlock_SysFricLrng_FricLrngData}
        {enable-take-address=true, indirect-api=false, port-defined-argument-value{value=79, value-type=NvM_BlockIdType}, port=PS_Rte_NvmBlock_CDD_VrfyCritReg_MCalReadVrfyCritRegFltNvmInfo}
        {enable-take-address=true, indirect-api=false, port-defined-argument-value{value=79, value-type=NvM_BlockIdType}, port=PAdmin_Rte_NvmBlock_CDD_VrfyCritReg_MCalReadVrfyCritRegFltNvmInfo}
        {enable-take-address=true, indirect-api=false, port-defined-argument-value{value=77, value-type=NvM_BlockIdType}, port=PS_Rte_NvmBlock_HwAg1Meas_HwAg1IfFltLtch}
        {enable-take-address=true, indirect-api=false, port-defined-argument-value{value=77, value-type=NvM_BlockIdType}, port=PAdmin_Rte_NvmBlock_HwAg1Meas_HwAg1IfFltLtch}
        {enable-take-address=true, indirect-api=false, port-defined-argument-value{value=78, value-type=NvM_BlockIdType}, port=PS_Rte_NvmBlock_HwAg1Meas_HwAg1Offs}
        {enable-take-address=true, indirect-api=false, port-defined-argument-value{value=78, value-type=NvM_BlockIdType}, port=PAdmin_Rte_NvmBlock_HwAg1Meas_HwAg1Offs}
        {enable-take-address=true, indirect-api=false, port-defined-argument-value{value=73, value-type=NvM_BlockIdType}, port=PS_Rte_NvmBlock_CDD_MotAg5Meas_MotAg5EolPrm}
        {enable-take-address=true, indirect-api=false, port-defined-argument-value{value=73, value-type=NvM_BlockIdType}, port=PAdmin_Rte_NvmBlock_CDD_MotAg5Meas_MotAg5EolPrm}
        {enable-take-address=true, indirect-api=false, port-defined-argument-value{value=74, value-type=NvM_BlockIdType}, port=PS_Rte_NvmBlock_CDD_MotAg6Meas_MotAg6StVari}
        {enable-take-address=true, indirect-api=false, port-defined-argument-value{value=74, value-type=NvM_BlockIdType}, port=PAdmin_Rte_NvmBlock_CDD_MotAg6Meas_MotAg6StVari}
        {enable-take-address=true, indirect-api=false, port-defined-argument-value{value=75, value-type=NvM_BlockIdType}, port=PS_Rte_NvmBlock_CDD_MotAg6Meas_MotAg6EolPrm}
        {enable-take-address=true, indirect-api=false, port-defined-argument-value{value=75, value-type=NvM_BlockIdType}, port=PAdmin_Rte_NvmBlock_CDD_MotAg6Meas_MotAg6EolPrm}
        {enable-take-address=true, indirect-api=false, port-defined-argument-value{value=76, value-type=NvM_BlockIdType}, port=PS_Rte_NvmBlock_CDD_MotAg5Meas_MotAg5StVari}
        {enable-take-address=true, indirect-api=false, port-defined-argument-value{value=76, value-type=NvM_BlockIdType}, port=PAdmin_Rte_NvmBlock_CDD_MotAg5Meas_MotAg5StVari}
        {enable-take-address=true, indirect-api=false, port-defined-argument-value{value=72, value-type=NvM_BlockIdType}, port=PS_Rte_NvmBlock_MotCtrlPrmEstimn_MotPrmNom}
        {enable-take-address=true, indirect-api=false, port-defined-argument-value{value=72, value-type=NvM_BlockIdType}, port=PAdmin_Rte_NvmBlock_MotCtrlPrmEstimn_MotPrmNom}
        {enable-take-address=true, indirect-api=false, port-defined-argument-value{value=71, value-type=NvM_BlockIdType}, port=PS_Deprecated_Rte_NvmBlock_HwTqCorrln_HwTqChACmnModCmpLpFilSt}
        {enable-take-address=true, indirect-api=false, port-defined-argument-value{value=71, value-type=NvM_BlockIdType}, port=PAdmin_Deprecated_Rte_NvmBlock_HwTqCorrln_HwTqChACmnModCmpLpFilSt}
        {enable-take-address=true, indirect-api=false, port-defined-argument-value{value=69, value-type=NvM_BlockIdType}, port=PS_Rte_NvmBlock_MotTqCmdSca_MotTqScaFac}
        {enable-take-address=true, indirect-api=false, port-defined-argument-value{value=69, value-type=NvM_BlockIdType}, port=PAdmin_Rte_NvmBlock_MotTqCmdSca_MotTqScaFac}
        {enable-take-address=true, indirect-api=false, port-defined-argument-value{value=70, value-type=NvM_BlockIdType}, port=PS_Rte_NvmBlock_DutyCycThermProtn_FilStVal}
        {enable-take-address=true, indirect-api=false, port-defined-argument-value{value=70, value-type=NvM_BlockIdType}, port=PAdmin_Rte_NvmBlock_DutyCycThermProtn_FilStVal}
        {enable-take-address=true, indirect-api=false, port-defined-argument-value{value=57, value-type=NvM_BlockIdType}, port=PS_Rte_NvmBlock_CmnMfgSrv_MfgTmpBuf1}
        {enable-take-address=true, indirect-api=false, port-defined-argument-value{value=57, value-type=NvM_BlockIdType}, port=PAdmin_Rte_NvmBlock_CmnMfgSrv_MfgTmpBuf1}
        {enable-take-address=true, indirect-api=false, port-defined-argument-value{value=58, value-type=NvM_BlockIdType}, port=PS_Rte_NvmBlock_CmnMfgSrv_DiRestore}
        {enable-take-address=true, indirect-api=false, port-defined-argument-value{value=58, value-type=NvM_BlockIdType}, port=PAdmin_Rte_NvmBlock_CmnMfgSrv_DiRestore}
        {enable-take-address=true, indirect-api=false, port-defined-argument-value{value=59, value-type=NvM_BlockIdType}, port=PS_Rte_NvmBlock_CmnMfgSrv_NxtrMfgEnaCntr}
        {enable-take-address=true, indirect-api=false, port-defined-argument-value{value=59, value-type=NvM_BlockIdType}, port=PAdmin_Rte_NvmBlock_CmnMfgSrv_NxtrMfgEnaCntr}
        {enable-take-address=true, indirect-api=false, port-defined-argument-value{value=60, value-type=NvM_BlockIdType}, port=PS_Rte_NvmBlock_CmnMfgSrv_MfgTmpBuf0}
        {enable-take-address=true, indirect-api=false, port-defined-argument-value{value=60, value-type=NvM_BlockIdType}, port=PAdmin_Rte_NvmBlock_CmnMfgSrv_MfgTmpBuf0}
        {enable-take-address=true, indirect-api=false, port-defined-argument-value{value=61, value-type=NvM_BlockIdType}, port=PS_Rte_NvmBlock_CmnMfgSrv_MfgTmpBuf3}
        {enable-take-address=true, indirect-api=false, port-defined-argument-value{value=61, value-type=NvM_BlockIdType}, port=PAdmin_Rte_NvmBlock_CmnMfgSrv_MfgTmpBuf3}
        {enable-take-address=true, indirect-api=false, port-defined-argument-value{value=62, value-type=NvM_BlockIdType}, port=PS_Rte_NvmBlock_CmnMfgSrv_EpsSysSerlNr}
        {enable-take-address=true, indirect-api=false, port-defined-argument-value{value=62, value-type=NvM_BlockIdType}, port=PAdmin_Rte_NvmBlock_CmnMfgSrv_EpsSysSerlNr}
        {enable-take-address=true, indirect-api=false, port-defined-argument-value{value=63, value-type=NvM_BlockIdType}, port=PS_Rte_NvmBlock_CmnMfgSrv_MfgTmpBuf2}
        {enable-take-address=true, indirect-api=false, port-defined-argument-value{value=63, value-type=NvM_BlockIdType}, port=PAdmin_Rte_NvmBlock_CmnMfgSrv_MfgTmpBuf2}
        {enable-take-address=true, indirect-api=false, port-defined-argument-value{value=64, value-type=NvM_BlockIdType}, port=PS_Rte_NvmBlock_CmnMfgSrv_CcaHwPartNr}
        {enable-take-address=true, indirect-api=false, port-defined-argument-value{value=64, value-type=NvM_BlockIdType}, port=PAdmin_Rte_NvmBlock_CmnMfgSrv_CcaHwPartNr}
        {enable-take-address=true, indirect-api=false, port-defined-argument-value{value=65, value-type=NvM_BlockIdType}, port=PS_Rte_NvmBlock_CmnMfgSrv_MfgTmpBuf4}
        {enable-take-address=true, indirect-api=false, port-defined-argument-value{value=65, value-type=NvM_BlockIdType}, port=PAdmin_Rte_NvmBlock_CmnMfgSrv_MfgTmpBuf4}
        {enable-take-address=true, indirect-api=false, port-defined-argument-value{value=66, value-type=NvM_BlockIdType}, port=PS_Rte_NvmBlock_CmnMfgSrv_SeedKey}
        {enable-take-address=true, indirect-api=false, port-defined-argument-value{value=66, value-type=NvM_BlockIdType}, port=PAdmin_Rte_NvmBlock_CmnMfgSrv_SeedKey}
        {enable-take-address=true, indirect-api=false, port-defined-argument-value{value=67, value-type=NvM_BlockIdType}, port=PS_Rte_NvmBlock_CmnMfgSrv_IgnCntr}
        {enable-take-address=true, indirect-api=false, port-defined-argument-value{value=67, value-type=NvM_BlockIdType}, port=PAdmin_Rte_NvmBlock_CmnMfgSrv_IgnCntr}
        {enable-take-address=true, indirect-api=false, port-defined-argument-value{value=68, value-type=NvM_BlockIdType}, port=PS_Rte_NvmBlock_CmnMfgSrv_CcaSerlNr}
        {enable-take-address=true, indirect-api=false, port-defined-argument-value{value=68, value-type=NvM_BlockIdType}, port=PAdmin_Rte_NvmBlock_CmnMfgSrv_CcaSerlNr}
        {enable-take-address=true, indirect-api=false, port-defined-argument-value{value=56, value-type=NvM_BlockIdType}, port=PS_Rte_NvmBlock_CDD_HwTq1Meas_HwTq1Offs}
        {enable-take-address=true, indirect-api=false, port-defined-argument-value{value=56, value-type=NvM_BlockIdType}, port=PAdmin_Rte_NvmBlock_CDD_HwTq1Meas_HwTq1Offs}
        {enable-take-address=true, indirect-api=false, port-defined-argument-value{value=55, value-type=NvM_BlockIdType}, port=PS_Rte_NvmBlock_CDD_HwTq8Meas_HwTq8Offs}
        {enable-take-address=true, indirect-api=false, port-defined-argument-value{value=55, value-type=NvM_BlockIdType}, port=PAdmin_Rte_NvmBlock_CDD_HwTq8Meas_HwTq8Offs}
        {enable-take-address=true, indirect-api=false, port-defined-argument-value{value=54, value-type=NvM_BlockIdType}, port=PS_Rte_NvmBlock_TEstimn_TFilStVal}
        {enable-take-address=true, indirect-api=false, port-defined-argument-value{value=54, value-type=NvM_BlockIdType}, port=PAdmin_Rte_NvmBlock_TEstimn_TFilStVal}
        {enable-take-address=true, indirect-api=false, port-defined-argument-value{value=52, value-type=NvM_BlockIdType}, port=PS_Rte_NvmBlock_HwTq9Meas_HwTq9Offs}
        {enable-take-address=true, indirect-api=false, port-defined-argument-value{value=52, value-type=NvM_BlockIdType}, port=PAdmin_Rte_NvmBlock_HwTq9Meas_HwTq9Offs}
        {enable-take-address=true, indirect-api=false, port-defined-argument-value{value=53, value-type=NvM_BlockIdType}, port=PS_Rte_NvmBlock_HwTq10Meas_HwTq10Offs}
        {enable-take-address=true, indirect-api=false, port-defined-argument-value{value=53, value-type=NvM_BlockIdType}, port=PAdmin_Rte_NvmBlock_HwTq10Meas_HwTq10Offs}
        {enable-take-address=true, indirect-api=false, port-defined-argument-value{value=42, value-type=NvM_BlockIdType}, port=PS_Rte_NvmBlock_CustDiag_DidDE04}
        {enable-take-address=true, indirect-api=false, port-defined-argument-value{value=42, value-type=NvM_BlockIdType}, port=PAdmin_Rte_NvmBlock_CustDiag_DidDE04}
        {enable-take-address=true, indirect-api=false, port-defined-argument-value{value=43, value-type=NvM_BlockIdType}, port=PS_Rte_NvmBlock_CustDiag_DidDE02}
        {enable-take-address=true, indirect-api=false, port-defined-argument-value{value=43, value-type=NvM_BlockIdType}, port=PAdmin_Rte_NvmBlock_CustDiag_DidDE02}
        {enable-take-address=true, indirect-api=false, port-defined-argument-value{value=44, value-type=NvM_BlockIdType}, port=PS_Rte_NvmBlock_CustDiag_Did3003}
        {enable-take-address=true, indirect-api=false, port-defined-argument-value{value=44, value-type=NvM_BlockIdType}, port=PAdmin_Rte_NvmBlock_CustDiag_Did3003}
        {enable-take-address=true, indirect-api=false, port-defined-argument-value{value=45, value-type=NvM_BlockIdType}, port=PS_Rte_NvmBlock_CustDiag_DidDE01}
        {enable-take-address=true, indirect-api=false, port-defined-argument-value{value=45, value-type=NvM_BlockIdType}, port=PAdmin_Rte_NvmBlock_CustDiag_DidDE01}
        {enable-take-address=true, indirect-api=false, port-defined-argument-value{value=46, value-type=NvM_BlockIdType}, port=PS_Rte_NvmBlock_CustDiag_DidEE01}
        {enable-take-address=true, indirect-api=false, port-defined-argument-value{value=46, value-type=NvM_BlockIdType}, port=PAdmin_Rte_NvmBlock_CustDiag_DidEE01}
        {enable-take-address=true, indirect-api=false, port-defined-argument-value{value=47, value-type=NvM_BlockIdType}, port=PS_Rte_NvmBlock_CustDiag_DidDE03}
        {enable-take-address=true, indirect-api=false, port-defined-argument-value{value=47, value-type=NvM_BlockIdType}, port=PAdmin_Rte_NvmBlock_CustDiag_DidDE03}
        {enable-take-address=true, indirect-api=false, port-defined-argument-value{value=48, value-type=NvM_BlockIdType}, port=PS_Rte_NvmBlock_CustDiag_DidDE00}
        {enable-take-address=true, indirect-api=false, port-defined-argument-value{value=48, value-type=NvM_BlockIdType}, port=PAdmin_Rte_NvmBlock_CustDiag_DidDE00}
        {enable-take-address=true, indirect-api=false, port-defined-argument-value{value=49, value-type=NvM_BlockIdType}, port=PS_Rte_NvmBlock_CustDiag_DidF113}
        {enable-take-address=true, indirect-api=false, port-defined-argument-value{value=49, value-type=NvM_BlockIdType}, port=PAdmin_Rte_NvmBlock_CustDiag_DidF113}
        {enable-take-address=true, indirect-api=false, port-defined-argument-value{value=50, value-type=NvM_BlockIdType}, port=PS_Rte_NvmBlock_CustDiag_DidEE02}
        {enable-take-address=true, indirect-api=false, port-defined-argument-value{value=50, value-type=NvM_BlockIdType}, port=PAdmin_Rte_NvmBlock_CustDiag_DidEE02}
        {enable-take-address=true, indirect-api=false, port-defined-argument-value{value=51, value-type=NvM_BlockIdType}, port=PS_Rte_NvmBlock_CustDiag_DidF111}
        {enable-take-address=true, indirect-api=false, port-defined-argument-value{value=51, value-type=NvM_BlockIdType}, port=PAdmin_Rte_NvmBlock_CustDiag_DidF111}
        {enable-take-address=true, indirect-api=false, port-defined-argument-value{value=38, value-type=NvM_BlockIdType}, port=PS_Rte_NvmBlock_FordHwAgArbn_PrevIgnCycVal}
        {enable-take-address=true, indirect-api=false, port-defined-argument-value{value=38, value-type=NvM_BlockIdType}, port=PAdmin_Rte_NvmBlock_FordHwAgArbn_PrevIgnCycVal}
        {enable-take-address=true, indirect-api=false, port-defined-argument-value{value=39, value-type=NvM_BlockIdType}, port=PS_Rte_NvmBlock_FordHwAgArbn_NonAbsOffsVldFlg}
        {enable-take-address=true, indirect-api=false, port-defined-argument-value{value=39, value-type=NvM_BlockIdType}, port=PAdmin_Rte_NvmBlock_FordHwAgArbn_NonAbsOffsVldFlg}
        {enable-take-address=true, indirect-api=false, port-defined-argument-value{value=40, value-type=NvM_BlockIdType}, port=PS_Rte_NvmBlock_FordHwAgArbn_NonAbsOffs}
        {enable-take-address=true, indirect-api=false, port-defined-argument-value{value=40, value-type=NvM_BlockIdType}, port=PAdmin_Rte_NvmBlock_FordHwAgArbn_NonAbsOffs}
        {enable-take-address=true, indirect-api=false, port-defined-argument-value{value=41, value-type=NvM_BlockIdType}, port=PS_Rte_NvmBlock_FordVehSpdArbn_FordVehTireCircum}
        {enable-take-address=true, indirect-api=false, port-defined-argument-value{value=41, value-type=NvM_BlockIdType}, port=PAdmin_Rte_NvmBlock_FordVehSpdArbn_FordVehTireCircum}
        {enable-take-address=true, indirect-api=false, port-defined-argument-value{value=15, value-type=NvM_BlockIdType}, port=PS_Rte_NvmBlock_CustDiag_DidEE87}
        {enable-take-address=true, indirect-api=false, port-defined-argument-value{value=15, value-type=NvM_BlockIdType}, port=PAdmin_Rte_NvmBlock_CustDiag_DidEE87}
        {enable-take-address=true, indirect-api=false, port-defined-argument-value{value=16, value-type=NvM_BlockIdType}, port=PS_Rte_NvmBlock_CustDiag_DidF110}
        {enable-take-address=true, indirect-api=false, port-defined-argument-value{value=16, value-type=NvM_BlockIdType}, port=PAdmin_Rte_NvmBlock_CustDiag_DidF110}
        {enable-take-address=true, indirect-api=false, port-defined-argument-value{value=17, value-type=NvM_BlockIdType}, port=PS_Rte_NvmBlock_CustDiag_DidF163}
        {enable-take-address=true, indirect-api=false, port-defined-argument-value{value=17, value-type=NvM_BlockIdType}, port=PAdmin_Rte_NvmBlock_CustDiag_DidF163}
        {enable-take-address=true, indirect-api=false, port-defined-argument-value{value=18, value-type=NvM_BlockIdType}, port=PS_Rte_NvmBlock_CustDiag_DidF18C}
        {enable-take-address=true, indirect-api=false, port-defined-argument-value{value=18, value-type=NvM_BlockIdType}, port=PAdmin_Rte_NvmBlock_CustDiag_DidF18C}
        {enable-take-address=true, indirect-api=false, port-defined-argument-value{value=19, value-type=NvM_BlockIdType}, port=PS_Rte_NvmBlock_CustDiag_Did205B}
        {enable-take-address=true, indirect-api=false, port-defined-argument-value{value=19, value-type=NvM_BlockIdType}, port=PAdmin_Rte_NvmBlock_CustDiag_Did205B}
        {enable-take-address=true, indirect-api=false, port-defined-argument-value{value=20, value-type=NvM_BlockIdType}, port=PS_Rte_NvmBlock_CustDiag_DidEE00}
        {enable-take-address=true, indirect-api=false, port-defined-argument-value{value=20, value-type=NvM_BlockIdType}, port=PAdmin_Rte_NvmBlock_CustDiag_DidEE00}
        {enable-take-address=true, indirect-api=false, port-defined-argument-value{value=21, value-type=NvM_BlockIdType}, port=PS_Rte_NvmBlock_CustDiag_DidDE05}
        {enable-take-address=true, indirect-api=false, port-defined-argument-value{value=21, value-type=NvM_BlockIdType}, port=PAdmin_Rte_NvmBlock_CustDiag_DidDE05}
        {enable-take-address=true, indirect-api=false, port-defined-argument-value{value=22, value-type=NvM_BlockIdType}, port=PS_Rte_NvmBlock_CustDiag_DidEE40}
        {enable-take-address=true, indirect-api=false, port-defined-argument-value{value=22, value-type=NvM_BlockIdType}, port=PAdmin_Rte_NvmBlock_CustDiag_DidEE40}
        {enable-take-address=true, indirect-api=false, port-defined-argument-value{value=23, value-type=NvM_BlockIdType}, port=PS_Rte_NvmBlock_CustDiag_DidF18A}
        {enable-take-address=true, indirect-api=false, port-defined-argument-value{value=23, value-type=NvM_BlockIdType}, port=PAdmin_Rte_NvmBlock_CustDiag_DidF18A}
        {enable-take-address=true, indirect-api=false, port-defined-argument-value{value=24, value-type=NvM_BlockIdType}, port=PS_Rte_NvmBlock_CustDiag_DidEE84}
        {enable-take-address=true, indirect-api=false, port-defined-argument-value{value=24, value-type=NvM_BlockIdType}, port=PAdmin_Rte_NvmBlock_CustDiag_DidEE84}
        {enable-take-address=true, indirect-api=false, port-defined-argument-value{value=25, value-type=NvM_BlockIdType}, port=PS_Rte_NvmBlock_CustDiag_DidF15F}
        {enable-take-address=true, indirect-api=false, port-defined-argument-value{value=25, value-type=NvM_BlockIdType}, port=PAdmin_Rte_NvmBlock_CustDiag_DidF15F}
        {enable-take-address=true, indirect-api=false, port-defined-argument-value{value=26, value-type=NvM_BlockIdType}, port=PS_Rte_NvmBlock_CustDiag_DidF166}
        {enable-take-address=true, indirect-api=false, port-defined-argument-value{value=26, value-type=NvM_BlockIdType}, port=PAdmin_Rte_NvmBlock_CustDiag_DidF166}
        {enable-take-address=true, indirect-api=false, port-defined-argument-value{value=27, value-type=NvM_BlockIdType}, port=PS_Rte_NvmBlock_CustDiag_DidF162}
        {enable-take-address=true, indirect-api=false, port-defined-argument-value{value=27, value-type=NvM_BlockIdType}, port=PAdmin_Rte_NvmBlock_CustDiag_DidF162}
        {enable-take-address=true, indirect-api=false, port-defined-argument-value{value=28, value-type=NvM_BlockIdType}, port=PS_Rte_NvmBlock_CustDiag_DidEE82}
        {enable-take-address=true, indirect-api=false, port-defined-argument-value{value=28, value-type=NvM_BlockIdType}, port=PAdmin_Rte_NvmBlock_CustDiag_DidEE82}
        {enable-take-address=true, indirect-api=false, port-defined-argument-value{value=29, value-type=NvM_BlockIdType}, port=PS_Rte_NvmBlock_CustDiag_DidEE86}
        {enable-take-address=true, indirect-api=false, port-defined-argument-value{value=29, value-type=NvM_BlockIdType}, port=PAdmin_Rte_NvmBlock_CustDiag_DidEE86}
        {enable-take-address=true, indirect-api=false, port-defined-argument-value{value=30, value-type=NvM_BlockIdType}, port=PS_Rte_NvmBlock_CustDiag_DidEE88}
        {enable-take-address=true, indirect-api=false, port-defined-argument-value{value=30, value-type=NvM_BlockIdType}, port=PAdmin_Rte_NvmBlock_CustDiag_DidEE88}
        {enable-take-address=true, indirect-api=false, port-defined-argument-value{value=31, value-type=NvM_BlockIdType}, port=PS_Rte_NvmBlock_CustDiag_DidEE85}
        {enable-take-address=true, indirect-api=false, port-defined-argument-value{value=31, value-type=NvM_BlockIdType}, port=PAdmin_Rte_NvmBlock_CustDiag_DidEE85}
        {enable-take-address=true, indirect-api=false, port-defined-argument-value{value=32, value-type=NvM_BlockIdType}, port=PS_Rte_NvmBlock_CustDiag_Did205A}
        {enable-take-address=true, indirect-api=false, port-defined-argument-value{value=32, value-type=NvM_BlockIdType}, port=PAdmin_Rte_NvmBlock_CustDiag_Did205A}
        {enable-take-address=true, indirect-api=false, port-defined-argument-value{value=33, value-type=NvM_BlockIdType}, port=PS_Rte_NvmBlock_CustDiag_DidEE81}
        {enable-take-address=true, indirect-api=false, port-defined-argument-value{value=33, value-type=NvM_BlockIdType}, port=PAdmin_Rte_NvmBlock_CustDiag_DidEE81}
        {enable-take-address=true, indirect-api=false, port-defined-argument-value{value=34, value-type=NvM_BlockIdType}, port=PS_Rte_NvmBlock_CustDiag_Did301A}
        {enable-take-address=true, indirect-api=false, port-defined-argument-value{value=34, value-type=NvM_BlockIdType}, port=PAdmin_Rte_NvmBlock_CustDiag_Did301A}
        {enable-take-address=true, indirect-api=false, port-defined-argument-value{value=35, value-type=NvM_BlockIdType}, port=PS_Rte_NvmBlock_CustDiag_DidEE41}
        {enable-take-address=true, indirect-api=false, port-defined-argument-value{value=35, value-type=NvM_BlockIdType}, port=PAdmin_Rte_NvmBlock_CustDiag_DidEE41}
        {enable-take-address=true, indirect-api=false, port-defined-argument-value{value=36, value-type=NvM_BlockIdType}, port=PS_Rte_NvmBlock_CustDiag_DidEE83}
        {enable-take-address=true, indirect-api=false, port-defined-argument-value{value=36, value-type=NvM_BlockIdType}, port=PAdmin_Rte_NvmBlock_CustDiag_DidEE83}
        {enable-take-address=true, indirect-api=false, port-defined-argument-value{value=37, value-type=NvM_BlockIdType}, port=PS_Rte_NvmBlock_CustDiag_DidEED0}
        {enable-take-address=true, indirect-api=false, port-defined-argument-value{value=37, value-type=NvM_BlockIdType}, port=PAdmin_Rte_NvmBlock_CustDiag_DidEED0}
        {enable-take-address=true, indirect-api=false, port-defined-argument-value{value=9, value-type=NvM_BlockIdType}, port=PS_Rte_NvmBlock_CustDiag_DidEE21}
        {enable-take-address=true, indirect-api=false, port-defined-argument-value{value=9, value-type=NvM_BlockIdType}, port=PAdmin_Rte_NvmBlock_CustDiag_DidEE21}
        {enable-take-address=true, indirect-api=false, port-defined-argument-value{value=10, value-type=NvM_BlockIdType}, port=PS_Rte_NvmBlock_CustDiag_Did630F}
        {enable-take-address=true, indirect-api=false, port-defined-argument-value{value=10, value-type=NvM_BlockIdType}, port=PAdmin_Rte_NvmBlock_CustDiag_Did630F}
        {enable-take-address=true, indirect-api=false, port-defined-argument-value{value=11, value-type=NvM_BlockIdType}, port=PS_Rte_NvmBlock_CustDiag_DidEE22}
        {enable-take-address=true, indirect-api=false, port-defined-argument-value{value=11, value-type=NvM_BlockIdType}, port=PAdmin_Rte_NvmBlock_CustDiag_DidEE22}
        {enable-take-address=true, indirect-api=false, port-defined-argument-value{value=12, value-type=NvM_BlockIdType}, port=PS_Rte_NvmBlock_CustDiag_DidEE23}
        {enable-take-address=true, indirect-api=false, port-defined-argument-value{value=12, value-type=NvM_BlockIdType}, port=PAdmin_Rte_NvmBlock_CustDiag_DidEE23}
        {enable-take-address=true, indirect-api=false, port-defined-argument-value{value=13, value-type=NvM_BlockIdType}, port=PS_Rte_NvmBlock_CustDiag_Did630FChk}
        {enable-take-address=true, indirect-api=false, port-defined-argument-value{value=13, value-type=NvM_BlockIdType}, port=PAdmin_Rte_NvmBlock_CustDiag_Did630FChk}
        {enable-take-address=true, indirect-api=false, port-defined-argument-value{value=14, value-type=NvM_BlockIdType}, port=PS_Rte_NvmBlock_CustDiag_DidF190}
        {enable-take-address=true, indirect-api=false, port-defined-argument-value{value=14, value-type=NvM_BlockIdType}, port=PAdmin_Rte_NvmBlock_CustDiag_DidF190}
        {enable-take-address=true, indirect-api=false, port-defined-argument-value{value=7, value-type=NvM_BlockIdType}, port=PS_Rte_NvmBlock_StackMeas_StackMeasRes}
        {enable-take-address=true, indirect-api=false, port-defined-argument-value{value=7, value-type=NvM_BlockIdType}, port=PAdmin_Rte_NvmBlock_StackMeas_StackMeasRes}
        {enable-take-address=true, indirect-api=false, port-defined-argument-value{value=8, value-type=NvM_BlockIdType}, port=PS_Rte_NvmBlock_StackMeas_StackMeasApplCrc}
        {enable-take-address=true, indirect-api=false, port-defined-argument-value{value=8, value-type=NvM_BlockIdType}, port=PAdmin_Rte_NvmBlock_StackMeas_StackMeasApplCrc}
        {enable-take-address=true, indirect-api=false, port-defined-argument-value{value=3, value-type=NvM_BlockIdType}, port=PAdmin_Rte_NvmBlock_CDD_FordBlaBoxIfCmp1_LaneAssi}
        {enable-take-address=true, indirect-api=false, port-defined-argument-value{value=6, value-type=NvM_BlockIdType}, port=PAdmin_Rte_NvmBlock_CDD_FordBlaBoxIfCmp1_PullDriftCmp}
        {enable-take-address=true, indirect-api=false, port-defined-argument-value{value=5, value-type=NvM_BlockIdType}, port=PAdmin_Rte_NvmBlock_CDD_FordBlaBoxIfCmp1_TrlrBackupAssi}
        {enable-take-address=true, indirect-api=false, port-defined-argument-value{value=4, value-type=NvM_BlockIdType}, port=PAdmin_Rte_NvmBlock_CDD_FordBlaBoxIfCmp1_ActvNiblCtrl}
        {enable-take-address=true, indirect-api=false, port-defined-argument-value{value=3, value-type=NvM_BlockIdType}, port=PS_Rte_NvmBlock_CDD_FordBlaBoxIfCmp1_LaneAssi}
        {enable-take-address=true, indirect-api=false, port-defined-argument-value{value=5, value-type=NvM_BlockIdType}, port=PS_Rte_NvmBlock_CDD_FordBlaBoxIfCmp1_TrlrBackupAssi}
        {enable-take-address=true, indirect-api=false, port-defined-argument-value{value=6, value-type=NvM_BlockIdType}, port=PS_Rte_NvmBlock_CDD_FordBlaBoxIfCmp1_PullDriftCmp}
        {enable-take-address=true, indirect-api=false, port-defined-argument-value{value=4, value-type=NvM_BlockIdType}, port=PS_Rte_NvmBlock_CDD_FordBlaBoxIfCmp1_ActvNiblCtrl}
      9 x runnable:
        NvM_MainFunction
        GetErrorStatus: can-be-invoked-concurrently=true, symbol=NvM_GetErrorStatus
        SetRamBlockStatus: can-be-invoked-concurrently=true, symbol=NvM_SetRamBlockStatus
        ReadBlock: can-be-invoked-concurrently=true, symbol=NvM_ReadBlock
        WriteBlock: can-be-invoked-concurrently=true, symbol=NvM_WriteBlock
        InvalidateNvBlock: can-be-invoked-concurrently=true, symbol=NvM_InvalidateNvBlock
        EraseBlock: can-be-invoked-concurrently=true, symbol=NvM_EraseNvBlock
        SetBlockProtection: can-be-invoked-concurrently=true, symbol=NvM_SetBlockProtection
        RestoreBlockDefaults: can-be-invoked-concurrently=true, symbol=NvM_RestoreBlockDefaults
  swc implementation NvMImplementation: programming-language=C, behavior=NvMInternalBehavior
